VERSION "created by canmatrix"

NS_ :

BS_:

BU_: HUT T_BOX GW XBOX_D CEM Tester

BO_ 728 HUT23: 8 HUT
 SG_ ADAS_Stub_MsgTyp : 7|3@0+ (1,0) [0|7] "" GW
 SG_ ADAS_Stub_Offset : 4|13@0+ (1,0) [0|8190] "m" GW
 SG_ ADAS_Stub_CycCnt : 23|2@0+ (1,0) [0|3] "" GW
 SG_ ADAS_Stub_PathIdx : 21|6@0+ (1,0) [0|63] "" GW
 SG_ ADAS_Stub_StubPathIdx : 31|6@0+ (1,0) [0|63] "" GW
 SG_ ADAS_Stub_Retr : 25|1@0+ (1,0) [0|1] "" GW
 SG_ ADAS_Stub_Update : 24|1@0+ (1,0) [0|1] "" GW
 SG_ ADAS_Stub_RelProbb : 39|5@0+ (3.33333333333333,0) [0|100] "" GW
 SG_ ADAS_Stub_FuncRoadClass : 34|3@0+ (1,0) [0|7] "" GW
 SG_ ADAS_Stub_PartOfCalcRoute : 47|2@0+ (1,0) [0|3] "" GW
 SG_ ADAS_Stub_CmplxInsct : 45|2@0+ (1,0) [0|3] "" GW
 SG_ ADAS_Stub_FormOfWay : 43|4@0+ (1,0) [0|15] "" GW
 SG_ ADAS_Stub_TurnAngl : 55|8@0+ (1.41732283464567,0) [0|358.583] "" GW
 SG_ ADAS_Stub_LastStub : 63|1@0+ (1,0) [0|1] "" GW
 SG_ ADAS_Stub_RtOfWay : 62|2@0+ (1,0) [0|3] "" GW
 SG_ ADAS_Stub_NumOfLaneOppDir : 60|2@0+ (1,0) [0|3] "" GW
 SG_ ADAS_Stub_NumOfLaneDrvDir : 58|3@0+ (1,0) [0|7] "" GW

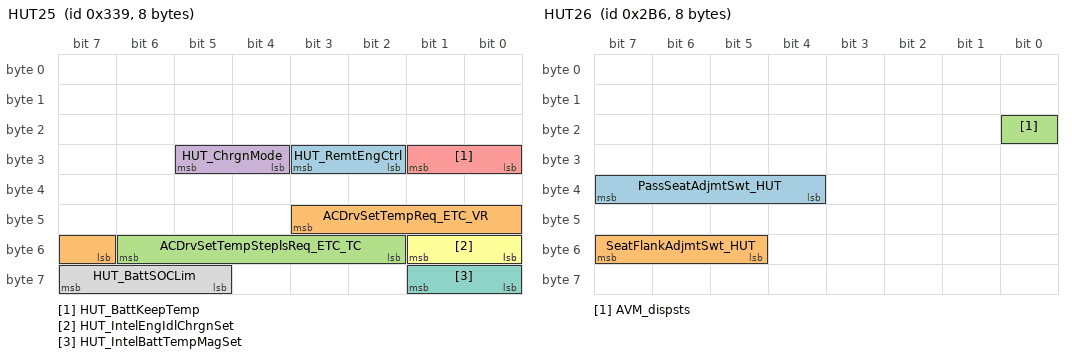
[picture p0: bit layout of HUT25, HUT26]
BO_ 825 HUT25: 8 HUT
 SG_ HUT_RemtEngCtrl : 27|2@0+ (1,0) [0|3] "" T_BOX
 SG_ ACDrvSetTempReq_ETC_VR : 43|5@0+ (1,0) [0|31] "" Vector__XXX
 SG_ ACDrvSetTempSteplsReq_ETC_TC : 54|5@0+ (1,0) [0|31] "" Vector__XXX
 SG_ HUT_ChrgnMode : 29|2@0+ (1,0) [0|3] "" GW
 SG_ HUT_BattKeepTemp : 25|2@0+ (1,0) [0|3] "" GW
 SG_ HUT_IntelEngIdlChrgnSet : 49|2@0+ (1,0) [0|3] "" GW
 SG_ HUT_IntelBattTempMagSet : 57|2@0+ (1,0) [0|3] "" GW
 SG_ HUT_BattSOCLim : 63|3@0+ (1,0) [0|7] "" GW

BO_ 694 HUT26: 8 HUT
 SG_ PassSeatAdjmtSwt_HUT : 39|4@0+ (1,0) [0|15] "" CEM
 SG_ SeatFlankAdjmtSwt_HUT : 55|3@0+ (1,0) [0|7] "" CEM
 SG_ AVM_dispsts : 16|1@0+ (1,0) [0|1] "" Vector__XXX

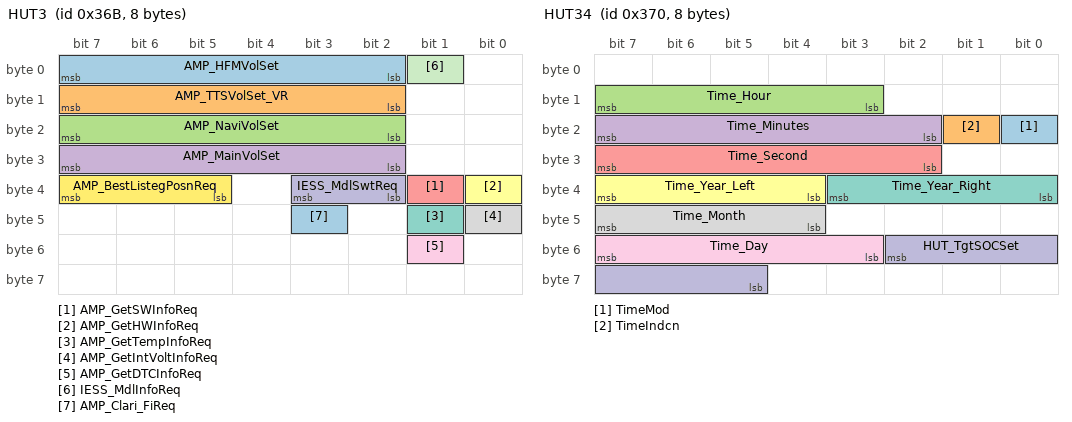
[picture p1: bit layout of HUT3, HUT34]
BO_ 875 HUT3: 8 HUT
 SG_ AMP_HFMVolSet : 7|6@0+ (1,0) [0|39] "" GW
 SG_ AMP_TTSVolSet_VR : 15|6@0+ (1,0) [0|39] "" GW
 SG_ AMP_NaviVolSet : 23|6@0+ (1,0) [0|39] "" GW
 SG_ AMP_MainVolSet : 31|6@0+ (1,0) [0|39] "" GW
 SG_ AMP_GetSWInfoReq : 33|1@0+ (1,0) [0|1] "" GW
 SG_ AMP_GetHWInfoReq : 32|1@0+ (1,0) [0|1] "" GW
 SG_ AMP_GetTempInfoReq : 41|1@0+ (1,0) [0|1] "" GW
 SG_ AMP_GetIntVoltInfoReq : 40|1@0+ (1,0) [0|1] "" GW
 SG_ AMP_GetDTCInfoReq : 49|1@0+ (1,0) [0|1] "" GW
 SG_ IESS_MdlSwtReq : 35|2@0+ (1,0) [0|3] "" GW
 SG_ IESS_MdlInfoReq : 1|1@0+ (1,0) [0|1] "" GW
 SG_ AMP_BestListegPosnReq : 39|3@0+ (1,0) [0|7] "" GW
 SG_ AMP_Clari_FiReq : 43|1@0+ (1,0) [0|1] "" GW

BO_ 489 HUT30: 8 HUT
 SG_ HUD_HeightLvlSwt : 12|5@0+ (1,0) [0|31] "" GW
 SG_ HUD_BrightnessLvlSwt : 31|4@0+ (1,0) [0|15] "" GW
 SG_ HUD_SwtReq : 25|2@0+ (1,0) [0|3] "" GW
 SG_ BackReq_AVM : 13|1@0+ (1,0) [0|1] "" CEM
 SG_ PPMIHWSwtSet : 5|2@0+ (1,0) [0|3] "" Vector__XXX
 SG_ PPMIBSRSwtSet : 3|2@0+ (1,0) [0|3] "" Vector__XXX
 SG_ PPMIHW_SwtSet : 5|2@0+ (1,0) [0|3] "" Vector__XXX
 SG_ PPMIBSR_SwtSet : 3|2@0+ (1,0) [0|3] "" Vector__XXX

BO_ 780 HUT31: 8 HUT
 SG_ HUT_PhoneNextRoad : 7|64@0+ (1,0) [0|1.84467440737096E+019] "" Vector__XXX

BO_ 623 HUT32: 8 HUT
 SG_ CheckSum_HUT32 : 7|8@0+ (1,0) [0|255] "" GW
 SG_ ScrnOpSts : 47|2@0+ (1,0) [0|3] "" GW
 SG_ XLvl : 23|11@0+ (1,0) [0|2046] "" GW
 SG_ YLvl : 26|11@0+ (1,0) [0|2046] "" GW
 SG_ DetVideoLost : 9|1@0+ (1,0) [0|1] "" GW
 SG_ PrkgCtrlModReqValid : 10|1@0+ (1,0) [0|1] "" GW
 SG_ PrkgCtrlModReq : 13|2@0+ (1,0) [0|3] "" GW
 SG_ ContnPrkgReqValid : 8|1@0+ (1,0) [0|1] "" GW
 SG_ ContnPrkgReq : 15|2@0+ (1,0) [0|3] "" GW
 SG_ PrkStraightSwtReq_HUT : 11|1@0+ (1,0) [0|1] "" GW
 SG_ PrkStraightSuspendOrFinishReq_HU : 28|2@0+ (1,0) [0|3] "" GW
 SG_ PrkStraightModSel_HUT : 63|3@0+ (1,0) [0|3] "" GW
 SG_ PrkStraightSts_HUT : 60|1@0+ (1,0) [0|1] "" GW
 SG_ PrkStraightStrtReq_HUT : 45|1@0+ (1,0) [0|1] "" GW
 SG_ PrkStraightVehStrtReq_HUT_Valid : 44|1@0+ (1,0) [0|1] "" GW
 SG_ PrkStraightContinueReq_HUT : 55|1@0+ (1,0) [0|1] "" GW
 SG_ P2P_PrkgDirSwtReq : 54|1@0+ (1,0) [0|1] "" Vector__XXX
 SG_ RainMode_Swt_Req : 51|1@0+ (1,0) [0|1] "" GW
 SG_ LCMode_Swt_Req : 50|2@0+ (1,0) [0|3] "" GW
 SG_ NavDecSwtReq : 48|1@0+ (1,0) [0|1] "_" GW
 SG_ RollingCounter_HUT32 : 59|4@0+ (1,0) [0|15] "" GW

BO_ 493 HUT33: 8 HUT
 SG_ FlaoutUnlockSet : 5|2@0+ (1,0) [0|3] "" CEM
 SG_ PrkInDirChoice : 12|2@0+ (1,0) [0|3] "" GW
 SG_ ADASDispSwt : 61|2@0+ (1,0) [0|1] "" Vector__XXX
 SG_ NaviDispSwt : 57|2@0+ (1,0) [0|1] "" Vector__XXX
 SG_ NaviDispSwt_VR : 59|2@0+ (1,0) [0|1] "" Vector__XXX
 SG_ ADASDispSwt_VR : 63|2@0+ (1,0) [0|1] "" Vector__XXX
 SG_ ApproachLampSet : 7|2@0+ (1,0) [0|3] "" CEM
 SG_ SuperLockSet : 3|2@0+ (1,0) [0|3] "" CEM
 SG_ ALCMDynModSet : 52|3@0+ (1,0) [0|7] "" CEM
 SG_ RLWinSwtReq_VR : 34|3@0+ (1,0) [0|7] "" CEM
 SG_ RRWinSwtReq_VR : 55|3@0+ (1,0) [0|7] "" CEM
 SG_ DrvWinSwtReq_VR : 15|3@0+ (1,0) [0|7] "" CEM
 SG_ PassWinSwtReq_VR : 37|3@0+ (1,0) [0|7] "" CEM
 SG_ ChairMemPosnSetSwt : 10|3@0+ (1,0) [0|7] "" CEM
 SG_ PathLrngFinshCmd : 17|1@0+ (1,0) [0|1] "" GW
 SG_ PathLrngStartCmd : 18|1@0+ (1,0) [0|1] "" GW
 SG_ SelPrkOutDirReq : 23|3@0+ (1,0) [0|7] "" GW
 SG_ StartPrkgPath2Cmd : 25|1@0+ (1,0) [0|1] "" GW
 SG_ DeletePath2Cmd : 26|1@0+ (1,0) [0|1] "" GW
 SG_ StartPrkgPath1Cmd : 27|1@0+ (1,0) [0|1] "" GW
 SG_ DeletePath1Cmd : 28|1@0+ (1,0) [0|1] "" GW
 SG_ SelPrkgFctnCmd : 31|3@0+ (1,0) [0|7] "" GW
 SG_ ParkMdlCmd : 19|1@0+ (1,0) [0|1] "" GW
 SG_ BackReq_APS : 20|1@0+ (1,0) [0|1] "" GW
 SG_ ACFGAEnaReq_TC : 47|2@0+ (1,0) [0|3] "" GW
 SG_ ACFGAChanTyp_TC : 45|3@0+ (1,0) [0|7] "" GW
 SG_ ACFGALvlReq_TC : 42|3@0+ (1,0) [0|7] "" GW
 SG_ P2P_PrkgDirectSwtCmd : 16|1@0+ (1,0) [0|1] "" GW

BO_ 880 HUT34: 8 HUT
 SG_ TimeMod : 16|1@0+ (1,0) [0|1] "" GW,CEM
 SG_ TimeIndcn : 17|1@0+ (1,0) [0|1] "" GW,CEM
 SG_ Time_Hour : 15|5@0+ (1,0) [0|31] "" GW,CEM,XBOX_D,T_BOX
 SG_ Time_Minutes : 23|6@0+ (1,0) [0|63] "" GW,CEM,XBOX_D,T_BOX
 SG_ Time_Second : 31|6@0+ (1,0) [0|63] "" GW,CEM,XBOX_D,T_BOX
 SG_ Time_Year_Left : 39|4@0+ (1,0) [0|15] "" GW,CEM,XBOX_D,T_BOX
 SG_ Time_Year_Right : 35|4@0+ (1,0) [0|15] "" GW,CEM,XBOX_D,T_BOX
 SG_ Time_Month : 47|4@0+ (1,0) [0|15] "" GW,CEM,XBOX_D,T_BOX
 SG_ Time_Day : 55|5@0+ (1,0) [0|31] "" GW,CEM,XBOX_D,T_BOX
 SG_ HUT_TgtSOCSet : 50|6@0+ (1,30) [30|80] "" GW

BO_ 485 HUT35: 8 HUT
 SG_ ACRearTempReq_ETC_VR : 23|5@0+ (1,0) [0|31] "" Vector__XXX
 SG_ ACRearTempSteplsReq_ETC_TC : 31|5@0+ (1,0) [0|31] "" Vector__XXX
 SG_ ACDrvTempDecReq_ETC_TC : 39|2@0+ (1,0) [0|3] "" Vector__XXX
 SG_ ACDrvTempIncReq_ETC_TC : 37|2@0+ (1,0) [0|3] "" Vector__XXX
 SG_ ACRearTempDecReq_ETC_TC : 35|2@0+ (1,0) [0|3] "" Vector__XXX
 SG_ ACRearTempIncReq_ETC_TC : 33|2@0+ (1,0) [0|3] "" Vector__XXX
 SG_ ACRearPowerReq_VR : 47|2@0+ (1,0) [0|3] "" GW,CEM
 SG_ ACMaxReq_VR : 26|2@0+ (1,0) [0|3] "" GW,CEM
 SG_ ACMaxReq_TC : 18|2@0+ (1,0) [0|3] "" GW,CEM
 SG_ FrntWiprCtrl_VR : 63|2@0+ (1,0) [0|3] "" CEM
 SG_ ACRearAutoModReq_VR : 43|2@0+ (1,0) [0|3] "" GW,CEM
 SG_ LockWinSet : 49|1@0+ (1,0) [0|1] "" CEM
 SG_ ACRearLockReq_TC : 45|2@0+ (1,0) [0|3] "" GW
 SG_ SrSpdCtrlSwt : 16|1@0+ (1,0) [0|1] "" CEM
 SG_ DPF_Request : 58|2@0+ (1,0) [0|3] "" GW
 SG_ ColorCategory : 3|2@0+ (1,0) [0|3] "" CEM
 SG_ SingleColorNr : 14|7@0+ (1,0) [0|64] "" CEM

BO_ 487 HUT38: 8 HUT
 SG_ ACRLTempDecReq_TC : 7|2@0+ (1,0) [0|3] "" GW,CEM
 SG_ ACRLTempIncReq_TC : 5|2@0+ (1,0) [0|3] "" GW,CEM
 SG_ ACRLTempReq_VR : 15|6@0+ (0.5,15.5) [16|32] "" GW,CEM
 SG_ ACRRTempDecReq_TC : 3|2@0+ (1,0) [0|3] "" CEM
 SG_ ACRRTempIncReq_TC : 1|2@0+ (1,0) [0|3] "" CEM
 SG_ ACRRTempReq_VR : 23|6@0+ (0.5,15.5) [16|32] "" CEM
 SG_ ACRRTempSteplsReq_TC : 17|2@0+ (1,0) [0|3] "" CEM
 SG_ ACHumidifierReq_VR : 31|2@0+ (1,0) [0|3] "" CEM
 SG_ ACHumidifierReq_TC : 29|2@0+ (1,0) [0|3] "" CEM
 SG_ ACOzoneReq_TC : 27|2@0+ (1,0) [0|3] "" CEM
 SG_ ACOzoneReq_VR : 25|2@0+ (1,0) [0|3] "" CEM
 SG_ ACUltravioletReq_TC : 39|2@0+ (1,0) [0|3] "" CEM
 SG_ ACUltravioletReq_VR : 37|2@0+ (1,0) [0|3] "" CEM
 SG_ ACFrntWinHeatCmd_TC : 35|2@0+ (1,0) [0|3] "" CEM
 SG_ ACFrntWinHeatCmd_VR : 33|2@0+ (1,0) [0|3] "" CEM
 SG_ DrvDoorALCMFlashFreq : 47|3@0+ (1,0) [0|7] "" CEM
 SG_ PassDoorALCMFlashFreq : 44|3@0+ (1,0) [0|7] "" CEM
 SG_ LRDoorALCMFlashFreq : 41|3@0+ (1,0) [0|7] "" CEM
 SG_ RRDoorALCMFlashFreq : 54|3@0+ (1,0) [0|7] "" CEM
 SG_ FootALCMFlashFreq : 51|3@0+ (1,0) [0|7] "" CEM
 SG_ LeftPanelALCMFlashFreq : 63|3@0+ (1,0) [0|7] "" CEM
 SG_ RightPanelALCMFlashFreq : 60|3@0+ (1,0) [0|7] "" CEM
 SG_ ACRearLockReq_VR : 57|2@0+ (1,0) [0|3] "" GW

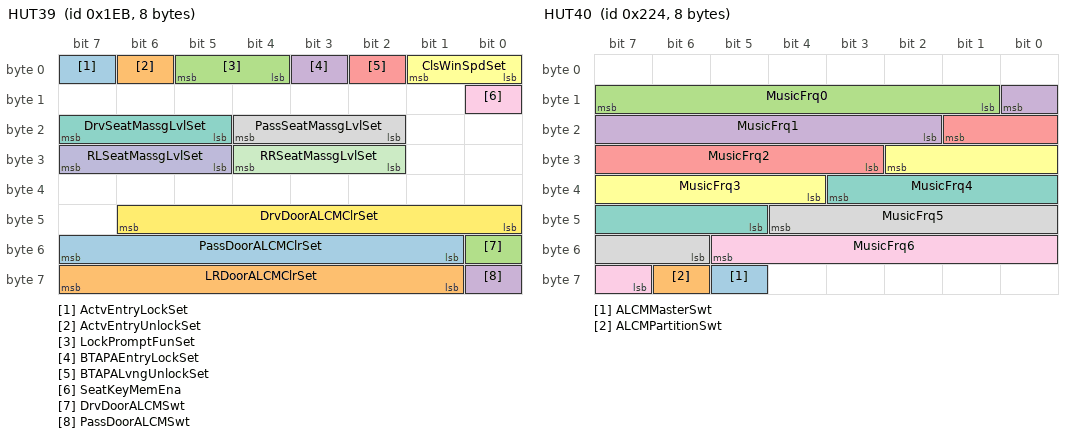
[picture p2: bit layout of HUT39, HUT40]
BO_ 491 HUT39: 8 HUT
 SG_ ActvEntryLockSet : 7|1@0+ (1,0) [0|1] "" CEM
 SG_ ActvEntryUnlockSet : 6|1@0+ (1,0) [0|1] "" CEM
 SG_ LockPromptFunSet : 5|2@0+ (1,0) [0|3] "" CEM
 SG_ BTAPAEntryLockSet : 3|1@0+ (1,0) [0|1] "" CEM
 SG_ BTAPALvngUnlockSet : 2|1@0+ (1,0) [0|1] "" CEM
 SG_ ClsWinSpdSet : 1|2@0+ (1,0) [0|3] "" CEM
 SG_ DrvSeatMassgLvlSet : 23|3@0+ (1,0) [0|7] "" GW,CEM
 SG_ PassSeatMassgLvlSet : 20|3@0+ (1,0) [0|7] "" GW,CEM
 SG_ SeatKeyMemEna : 8|1@0+ (1,0) [0|1] "" CEM
 SG_ RLSeatMassgLvlSet : 31|3@0+ (1,0) [0|7] "" GW,CEM
 SG_ RRSeatMassgLvlSet : 28|3@0+ (1,0) [0|7] "" GW,CEM
 SG_ DrvDoorALCMClrSet : 46|7@0+ (1,0) [0|127] "" CEM
 SG_ PassDoorALCMClrSet : 55|7@0+ (1,0) [0|127] "" CEM
 SG_ LRDoorALCMClrSet : 63|7@0+ (1,0) [0|127] "" CEM
 SG_ DrvDoorALCMSwt : 48|1@0+ (1,0) [0|1] "" CEM
 SG_ PassDoorALCMSwt : 56|1@0+ (1,0) [0|1] "" CEM

BO_ 877 HUT4: 8 HUT
 SG_ DrvSeatVentnLvlSet : 9|2@0+ (1,0) [0|3] "" CEM
 SG_ PassSeatVentnLvlSet : 23|2@0+ (1,0) [0|3] "" CEM
 SG_ ACAutoModReq_VR : 25|2@0+ (1,0) [0|3] "" GW
 SG_ ACCmprReq_VR : 39|2@0+ (1,0) [0|3] "" GW
 SG_ ACPowerReq_VR : 37|2@0+ (1,0) [0|3] "" GW
 SG_ ACBlwrSpdReq_VR : 35|4@0+ (1,0) [0|15] "" GW
 SG_ ACDrvTempReq_VR : 47|6@0+ (0.5,15.5) [16|32] "Ã‚Â°C" GW
 SG_ ACFrntDefrostReq_VR : 41|2@0+ (1,0) [0|3] "" GW
 SG_ ACDrvAirDistribModReq_VR : 55|3@0+ (1,0) [0|7] "" GW
 SG_ ACAirInletReq_VR : 52|2@0+ (1,0) [0|3] "" GW
 SG_ ACModReq_HUT : 63|2@0+ (1,0) [0|3] "" Vector__XXX
 SG_ ElecSideSteppingSysSet : 21|1@0+ (1,0) [0|1] "" CEM
 SG_ RoofModSet : 18|1@0+ (1,0) [0|1] "" CEM
 SG_ AllTerrainDislSet : 29|1@0+ (1,0) [0|1] "" CEM
 SG_ RemUpgrdSts : 56|1@0+ (1,0) [0|1] "" CEM,T_BOX
 SG_ ACRearAutoModReq_TC : 13|1@0+ (1,0) [0|1] "" GW,CEM
 SG_ DrvSeatSupportLvlSet : 7|3@0+ (1,0) [0|7] "" CEM
 SG_ PassSeatSupportLvlSet : 2|3@0+ (1,0) [0|7] "" CEM
 SG_ ACRearOffReq_TC : 10|1@0+ (1,0) [0|3] "" GW,CEM
 SG_ ACRearAirDistribModReq_TC : 50|3@0+ (1,0) [0|7] "" GW,CEM
 SG_ RLSeatVentnLvlSet : 20|2@0+ (1,0) [0|3] "" CEM
 SG_ RRSeatVentnLvlSet : 17|2@0+ (1,0) [0|3] "" CEM

BO_ 548 HUT40: 8 HUT
 SG_ ALCMMasterSwt : 61|1@0+ (1,0) [0|1] "" CEM
 SG_ ALCMPartitionSwt : 62|1@0+ (1,0) [0|1] "" CEM
 SG_ MusicFrq0 : 15|7@0+ (1,0) [0|127] "" CEM
 SG_ MusicFrq1 : 8|7@0+ (1,0) [0|127] "" CEM
 SG_ MusicFrq2 : 17|7@0+ (1,0) [0|127] "" CEM
 SG_ MusicFrq3 : 26|7@0+ (1,0) [0|127] "" CEM
 SG_ MusicFrq4 : 35|7@0+ (1,0) [0|127] "" CEM
 SG_ MusicFrq5 : 44|7@0+ (1,0) [0|127] "" CEM
 SG_ MusicFrq6 : 53|7@0+ (1,0) [0|127] "" CEM

BO_ 507 HUT41: 8 HUT
 SG_ RRDoorALCMClrSet : 7|7@0+ (1,0) [0|127] "" CEM
 SG_ LeftPanelALCMClrSet : 15|7@0+ (1,0) [0|127] "" CEM
 SG_ RightPanelALCMClrSet : 23|7@0+ (1,0) [0|127] "" CEM
 SG_ FootALCMClrSet : 31|7@0+ (1,0) [0|127] "" CEM
 SG_ DrvDoorALCMLightLvlSet : 39|4@0+ (1,0) [0|15] "" CEM
 SG_ PassDoorALCMLightLvlSet : 35|4@0+ (1,0) [0|15] "" CEM
 SG_ LRDoorALCMLightLvlSet : 47|4@0+ (1,0) [0|15] "" CEM
 SG_ RRDoorALCMLightLvlSet : 43|4@0+ (1,0) [0|15] "" CEM
 SG_ LeftPanelALCMLightLvlSet : 55|4@0+ (1,0) [0|15] "" CEM
 SG_ RightPanelALCMLightLvlSet : 51|4@0+ (1,0) [0|15] "" CEM
 SG_ FootALCMLightLvlSet : 63|4@0+ (1,0) [0|15] "" CEM
 SG_ ALCMFloSwt : 0|1@0+ (1,0) [0|1] "" CEM
 SG_ ALCMBreSwt : 8|1@0+ (1,0) [0|1] "" CEM
 SG_ RightPanelALCMSwt : 24|1@0+ (1,0) [0|1] "" CEM
 SG_ LRDoorALCMSwt : 59|1@0+ (1,0) [0|1] "" CEM
 SG_ RRDoorALCMSwt : 58|1@0+ (1,0) [0|1] "" CEM
 SG_ FootALCMSwt : 57|1@0+ (1,0) [0|1] "" CEM
 SG_ RoofALCMSwt : 56|1@0+ (1,0) [0|1] "" CEM
 SG_ LeftPanelALCMSwt : 16|1@0+ (1,0) [0|1] "" CEM

BO_ 505 HUT42: 8 HUT
 SG_ ACRLTempSteplsReq_TC : 37|6@0+ (0.5,15.5) [16|32] "" GW

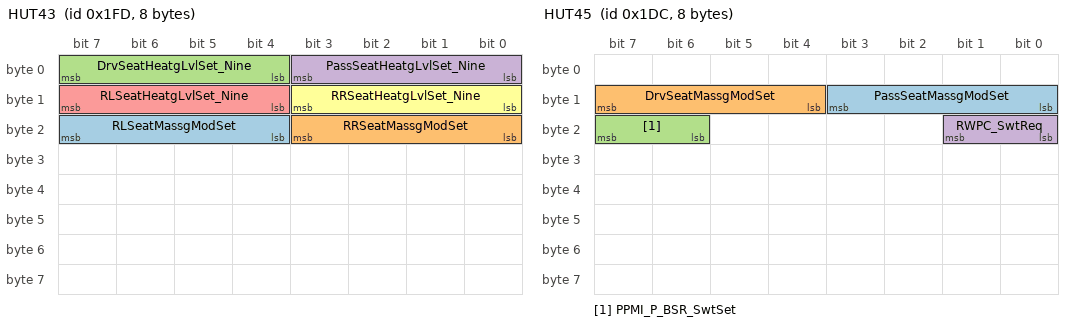
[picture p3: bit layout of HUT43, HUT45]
BO_ 509 HUT43: 8 HUT
 SG_ RLSeatMassgModSet : 23|4@0+ (1,0) [0|15] "" GW,CEM
 SG_ RRSeatMassgModSet : 19|4@0+ (1,0) [0|15] "" GW,CEM
 SG_ DrvSeatHeatgLvlSet_Nine : 7|4@0+ (1,0) [0|15] "" CEM
 SG_ PassSeatHeatgLvlSet_Nine : 3|4@0+ (1,0) [0|15] "" CEM
 SG_ RLSeatHeatgLvlSet_Nine : 15|4@0+ (1,0) [0|15] "" CEM
 SG_ RRSeatHeatgLvlSet_Nine : 11|4@0+ (1,0) [0|15] "" CEM

BO_ 476 HUT45: 8 HUT
 SG_ PassSeatMassgModSet : 11|4@0+ (1,0) [0|15] "" GW
 SG_ DrvSeatMassgModSet : 15|4@0+ (1,0) [0|15] "" GW
 SG_ PPMI_P_BSR_SwtSet : 23|2@0+ (1,0) [0|3] "" Vector__XXX
 SG_ RWPC_SwtReq : 17|2@0+ (1,0) [0|3] "" Vector__XXX

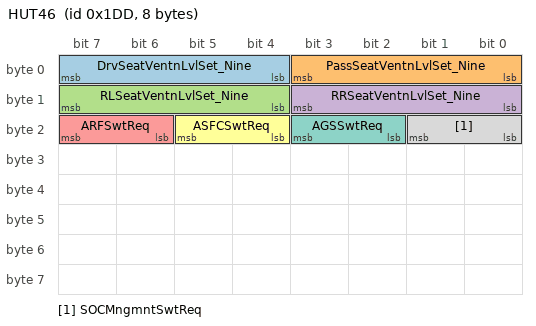
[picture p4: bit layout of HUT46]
BO_ 477 HUT46: 8 HUT
 SG_ DrvSeatVentnLvlSet_Nine : 7|4@0+ (1,0) [0|15] "" CEM
 SG_ PassSeatVentnLvlSet_Nine : 3|4@0+ (1,0) [0|15] "" CEM
 SG_ RLSeatVentnLvlSet_Nine : 15|4@0+ (1,0) [0|15] "" CEM
 SG_ RRSeatVentnLvlSet_Nine : 11|4@0+ (1,0) [0|15] "" CEM
 SG_ ARFSwtReq : 23|2@0+ (1,0) [0|2] "" GW
 SG_ ASFCSwtReq : 21|2@0+ (1,0) [0|2] "" GW
 SG_ AGSSwtReq : 19|2@0+ (1,0) [0|2] "" GW
 SG_ SOCMngmntSwtReq : 17|2@0+ (1,0) [0|2] "" GW

BO_ 74 HUT6: 8 HUT
 SG_ AUTODefrost_TC : 6|2@0+ (1,0) [0|3] "" GW,CEM
 SG_ AUTODefrost_VR : 4|2@0+ (1,0) [0|3] "" GW,CEM
 SG_ LaneCalActvtCmd : 42|1@0+ (1,0) [0|1] "" GW
 SG_ MODChgReq : 62|1@0+ (1,0) [0|1] "" GW
 SG_ Radar_DispCmd : 40|1@0+ (1,0) [0|1] "" GW
 SG_ Guid_Ovl_Display_Cmd : 7|1@0+ (1,0) [0|1] "" GW
 SG_ Sgl_View_Sel : 36|4@0+ (1,0) [0|15] "" GW
 SG_ SwToFieldCalRstCmd : 58|1@0+ (1,0) [0|1] "" GW
 SG_ AutoViewChgCmd : 55|1@0+ (1,0) [0|1] "" GW
 SG_ MdlColrChgCmd : 53|1@0+ (1,0) [0|1] "" GW
 SG_ CarMdlTrsprcySwtCmd : 49|1@0+ (1,0) [0|1] "" GW
 SG_ CarMdlDispCmd : 63|1@0+ (1,0) [0|1] "" GW
 SG_ AutoAVMSwSet_Cmd : 57|1@0+ (1,0) [0|1] "" GW
 SG_ FPAS_AutoModSwt : 60|1@0+ (1,0) [0|1] "" GW
 SG_ MEBSwtSet : 61|1@0+ (1,0) [0|1] "" GW
 SG_ WshSoftSwt : 56|1@0+ (1,0) [0|1] "" GW
 SG_ View_SoftswitchCmd : 59|1@0+ (1,0) [0|1] "" GW

BO_ 465 HUT49: 8 HUT
 SG_ AntiDisIdnResp : 7|32@0+ (1,0) [0|4294967295] "" GW

BO_ 288 Ibooster_FD2: 64 GW
 SG_ IB_Warn : 46|1@0+ (1,0) [0|1] "" HUT

BO_ 573 IFC_FD2: 64 IFC
 SG_ Checksum_IFC3 : 71|8@0+ (1,0) [0|255] "" HUT
 SG_ LDWResp : 79|1@0+ (1,0) [0|1] "" HUT
 SG_ LKAResp : 78|1@0+ (1,0) [0|1] "" HUT
 SG_ LCKResp : 77|1@0+ (1,0) [0|1] "" HUT
 SG_ ELKResp : 76|1@0+ (1,0) [0|1] "" HUT
 SG_ LDW_LKA_Snvty : 74|2@0+ (1,0) [0|3] "" HUT
 SG_ IFCHUTInterface : 72|1@0+ (1,0) [0|1] "" HUT
 SG_ LSSWarnFormResp : 85|2@0+ (1,0) [0|3] "" HUT
 SG_ LSSResp : 83|1@0+ (1,0) [0|1] "" HUT
 SG_ AESSts : 81|2@0+ (1,0) [0|3] "" HUT
 SG_ ESSSts : 95|2@0+ (1,0) [0|3] "" HUT
 SG_ AESErrSts : 93|1@0+ (1,0) [0|1] "" HUT
 SG_ ESSErrSts : 92|1@0+ (1,0) [0|1] "" HUT
 SG_ RollingCounter_IFC3 : 123|4@0+ (1,0) [0|15] "" HUT
 SG_ Checksum_IFC4 : 135|8@0+ (1,0) [0|255] "" HUT
 SG_ IFC_Handsoffwarn : 157|3@0+ (1,0) [0|7] "" HUT
 SG_ IFCCalibrationSts : 154|2@0+ (1,0) [0|3] "" HUT
 SG_ CameraBlockageSts : 152|1@0+ (1,0) [0|1] "" HUT
 SG_ LDW_LKAWarn : 143|2@0+ (1,0) [0|3] "" HUT
 SG_ LSSIntervention : 141|3@0+ (1,0) [0|7] "" HUT,T_BOX
 SG_ LSSFuncSts : 138|3@0+ (1,0) [0|7] "" HUT
 SG_ ELKMainState : 151|3@0+ (1,0) [0|7] "" HUT
 SG_ LaneAvailability : 148|2@0+ (1,0) [0|3] "" HUT
 SG_ TJA_FollowSts : 146|2@0+ (1,0) [0|3] "" HUT
 SG_ LSSErrSts : 144|3@0+ (1,0) [0|7] "" HUT
 SG_ AESintervention : 191|2@0+ (1,0) [0|3] "" HUT
 SG_ ESSintervention : 189|2@0+ (1,0) [0|3] "" HUT
 SG_ ELKActSts : 167|2@0+ (1,0) [0|3] "" HUT
 SG_ IntelligentEvaActSts : 165|2@0+ (1,0) [0|3] "" HUT
 SG_ LCKStsIndcr : 163|2@0+ (1,0) [0|3] "" HUT
 SG_ RollingCounter_IFC4 : 187|4@0+ (1,0) [0|15] "" HUT
 SG_ Checksum_IFC5 : 199|8@0+ (1,0) [0|255] "" HUT
 SG_ IFC_LaneCurve : 207|12@0+ (0.000015,-0.030705) [-0.030705|0.030705] "" HUT
 SG_ IFC_LeLaneTyp : 211|3@0+ (1,0) [0|7] "" HUT
 SG_ IFC_RiLaneTyp : 208|3@0+ (1,0) [0|7] "" HUT
 SG_ IFC_NextLeLaneTyp : 221|3@0+ (1,0) [0|7] "" HUT
 SG_ IFC_NextRiLaneTyp : 218|3@0+ (1,0) [0|7] "" HUT
 SG_ IFC_LeLane_dy : 231|12@0+ (0.00390625,-8) [-8|7.9921875] "" HUT
 SG_ IFC_RiLane_dy : 235|12@0+ (0.00390625,-8) [-8|7.9921875] "" HUT
 SG_ RollingCounter_IFC5 : 251|4@0+ (1,0) [0|15] "" HUT
 SG_ Checksum_IFC6 : 263|8@0+ (1,0) [0|255] "" HUT
 SG_ IFC_NextLeLane_dy : 271|12@0+ (0.00390625,-8) [-8|7.9921875] "" HUT
 SG_ IFC_NextRiLane_dy : 275|12@0+ (0.00390625,-8) [-8|7.9921875] "" HUT
 SG_ RollingCounter_IFC6 : 315|4@0+ (1,0) [0|15] "" HUT
 SG_ AESResp : 75|1@0+ (1,0) [0|1] "" HUT
 SG_ ESS_Pedresp : 87|1@0+ (1,0) [0|1] "" HUT
 SG_ ESS_Vehresp : 86|1@0+ (1,0) [0|1] "" HUT
 SG_ IntelligentEvaResp : 82|1@0+ (1,0) [0|1] "" HUT
 SG_ FreshnessValue_IFC_FD2 : 455|16@0+ (1,0) [0|65535] "" HUT
 SG_ MAC_Check_IFC_FD2 : 471|48@0+ (1,0) [0|281474976710655] "" HUT

BO_ 719 IFC_FD3: 64 GW
 SG_ TSRResp : 79|1@0+ (1,0) [0|1] "" HUT
 SG_ TSRSpdLimUnit : 78|2@0+ (1,0) [0|3] "" HUT
 SG_ TSRSpdLim : 87|6@0+ (1,0) [0|63] "" HUT
 SG_ TSRSpdLimCfdc : 76|2@0+ (1,0) [0|3] "" HUT
 SG_ TSRSts : 74|3@0+ (1,0) [0|7] "" HUT
 SG_ TSRSpdLimSts : 81|2@0+ (1,0) [0|3] "" HUT
 SG_ TSRTrfcSignValCfdc : 95|2@0+ (1,0) [0|3] "" HUT
 SG_ TSRTrfcSignVal : 93|8@0+ (1,0) [0|255] "" HUT
 SG_ TSRSpdLimWarn : 101|1@0+ (1,0) [0|1] "" HUT
 SG_ TSRWarnResp : 108|1@0+ (1,0) [0|1] "" HUT
 SG_ TSR_Snvty : 100|5@0+ (1,-15) [-15|15] "kmh" HUT
 SG_ IDC_L2_TurnLightReq : 110|2@0+ (1,0) [0|3] "" HUT
 SG_ HWA_ALC_Trig : 143|2@0+ (1,0) [0|3] "" HUT
 SG_ HWA_WarnInfoDisp : 141|4@0+ (1,0) [0|15] "" HUT
 SG_ HWA_TakOver_Trig : 151|3@0+ (1,0) [0|7] "" HUT
 SG_ HWA_TakOver_Req : 137|2@0+ (1,0) [0|3] "" HUT
 SG_ MRC_InterSysInfoDisp : 148|4@0+ (1,0) [0|15] "" HUT
 SG_ MRC_TakOver_Req : 159|2@0+ (1,0) [0|3] "" HUT
 SG_ NOH_WarnInfoDisp : 157|4@0+ (1,0) [0|15] "" HUT
 SG_ IFC_Line01_Source : 144|1@0+ (1,0) [0|1] "" HUT
 SG_ IFC_Line02_Source : 174|1@0+ (1,0) [0|1] "" HUT
 SG_ TSR_Traffic_Light_Posn : 153|2@0+ (1,0) [0|3] "" HUT
 SG_ Stop_Mark_Detn : 173|2@0+ (1,0) [0|3] "" HUT
 SG_ Stop_Mark_Dx : 167|9@0+ (0.5,0) [0|150] "m" HUT
 SG_ Zebra_Mark_Detn : 171|2@0+ (1,0) [0|3] "" HUT
 SG_ Grid_Mark_Detn : 169|2@0+ (1,0) [0|3] "" HUT
 SG_ HWA_InhibitWarn : 183|3@0+ (1,0) [0|7] "" HUT
 SG_ LaneChngCfmSwt_Resp : 189|1@0+ (1,0) [0|1] "" HUT
 SG_ ALC_SwtReq_Resp : 190|1@0+ (1,0) [0|1] "" HUT
 SG_ AutoSpdSetSwt_Resp : 191|1@0+ (1,0) [0|1] "" HUT
 SG_ VoiceBrdcSwt_Resp : 176|1@0+ (1,0) [0|1] "" HUT
 SG_ UsrManSts_Resp : 180|4@0+ (1,0) [0|15] "" HUT
 SG_ Grid_Mark_Dx : 207|9@0+ (0.5,0) [0|150] "m" HUT
 SG_ Zebra_Mark_Dx : 223|9@0+ (0.5,0) [0|150] "m" HUT
 SG_ TSR_Traffic_Light : 214|2@0+ (1,0) [0|3] "" HUT
 SG_ TSR_Traffic_Light_Through : 212|2@0+ (1,0) [0|3] "" HUT
 SG_ TSR_Traffic_Light_Le : 210|2@0+ (1,0) [0|3] "" HUT
 SG_ TSR_Traffic_Light_Ri : 230|2@0+ (1,0) [0|3] "" HUT
 SG_ RainMode_Swt_Resp : 228|1@0+ (1,0) [0|1] "" HUT
 SG_ LCMode_Swt_Resp : 227|2@0+ (1,0) [0|1] "" HUT
 SG_ NavDecSwtResp : 225|1@0+ (1,0) [0|1] "" HUT

BO_ 415 IFC_FD5: 64 GW
 SG_ IFC_Line01_Dy : 15|13@0+ (0.01,-30) [-30|30] "m" HUT
 SG_ IFC_Line01_Curv : 18|15@0+ (0.000016,-0.25) [-0.25|0.25] "1m" HUT
 SG_ IFC_Line01_CurvChange : 35|20@0+ (5E-008,-0.024) [-0.024|0.024] "1(m*m)" HUT
 SG_ IFC_Line01_Type : 63|4@0+ (1,0) [0|15] "" HUT
 SG_ IFC_Line02_Dy : 79|13@0+ (0.01,-30) [-30|30] "m" HUT
 SG_ IFC_Line02_Curv : 82|15@0+ (0.000016,-0.25) [-0.25|0.25] "1m" HUT
 SG_ IFC_Line02_CurvChange : 99|20@0+ (5E-008,-0.024) [-0.024|0.024] "1(m*m)" HUT
 SG_ IFC_Line02_Type : 127|4@0+ (1,0) [0|15] "" HUT
 SG_ IFC_Line03_Dy : 143|13@0+ (0.01,-30) [-30|30] "m" HUT
 SG_ IFC_Line03_Curv : 146|15@0+ (0.000016,-0.25) [-0.25|0.25] "1m" HUT
 SG_ IFC_Line03_CurvChange : 163|20@0+ (5E-008,-0.024) [-0.024|0.024] "1(m*m)" HUT
 SG_ IFC_Line03_Type : 191|4@0+ (1,0) [0|15] "" HUT
 SG_ IFC_Line04_Dy : 207|13@0+ (0.01,-30) [-30|30] "m" HUT
 SG_ IFC_Line04_Curv : 210|15@0+ (0.000016,-0.25) [-0.25|0.25] "1m" HUT
 SG_ IFC_Line04_CurvChange : 227|20@0+ (5E-008,-0.024) [-0.024|0.024] "1(m*m)" HUT
 SG_ IFC_Line04_Type : 255|4@0+ (1,0) [0|15] "" HUT
 SG_ IFC_Roadedge01_Dy : 271|13@0+ (0.01,-30) [-30|30] "m" HUT
 SG_ IFC_Roadedge01_Curv : 274|15@0+ (0.000016,-0.25) [-0.25|0.25] "1m" HUT
 SG_ IFC_Roadedge01_CurvChange : 291|20@0+ (5E-008,-0.024) [-0.024|0.024] "1(m*m)" HUT
 SG_ IFC_Roadedge01_Type : 319|4@0+ (1,0) [0|15] "" HUT
 SG_ IFC_Roadedge02_Dy : 335|13@0+ (0.01,-30) [-30|30] "m" HUT
 SG_ IFC_Roadedge02_Curv : 338|15@0+ (0.000016,-0.25) [-0.25|0.25] "1m" HUT
 SG_ IFC_Roadedge02_CurvChange : 355|20@0+ (5E-008,-0.024) [-0.024|0.024] "1(m*m)" HUT
 SG_ IFC_Roadedge02_Type : 383|4@0+ (1,0) [0|15] "" HUT

BO_ 546 IFC_FD6: 64 GW
 SG_ IFC_Line01_DxStart : 15|15@0+ (0.01,0) [0|200] "m" HUT
 SG_ IFC_Line01_DxEnd : 16|15@0+ (0.01,0) [0|200] "m" HUT
 SG_ IFC_Line01_HeadingAngle : 33|9@0+ (0.01,-2) [-2|2] "rad" HUT
 SG_ IFC_Line02_HeadingAngle : 40|9@0+ (0.01,-2) [-2|2] "rad" HUT
 SG_ IFC_Line02_DxStart : 79|15@0+ (0.01,0) [0|200] "m" HUT
 SG_ IFC_Line02_DxEnd : 95|15@0+ (0.01,0) [0|200] "m" HUT
 SG_ IFC_Line03_DxStart : 111|15@0+ (0.01,0) [0|200] "m" HUT
 SG_ IFC_Line03_DxEnd : 143|15@0+ (0.01,0) [0|200] "m" HUT
 SG_ IFC_Line03_HeadingAngle : 144|9@0+ (0.01,-2) [-2|2] "rad" HUT
 SG_ IFC_Line04_DxStart : 167|15@0+ (0.01,0) [0|200] "m" HUT
 SG_ IFC_Line04_HeadingAngle : 168|9@0+ (0.01,-2) [-2|2] "rad" HUT
 SG_ IFC_Line04_DxEnd : 207|15@0+ (0.01,0) [0|200] "m" HUT
 SG_ IFC_Roadedge01_DxStart : 223|15@0+ (0.01,0) [0|200] "m" HUT
 SG_ IFC_Roadedge01_DxEnd : 239|15@0+ (0.01,0) [0|200] "m" HUT
 SG_ IFC_Roadedge01_HeadingAngle : 271|9@0+ (0.01,-2) [-2|2] "rad" HUT
 SG_ IFC_Roadedge02_DxStart : 278|15@0+ (0.01,0) [0|200] "m" HUT
 SG_ IFC_Roadedge02_DxEnd : 295|15@0+ (0.01,0) [0|200] "m" HUT
 SG_ IFC_Roadedge02_HeadingAngle : 296|9@0+ (0.01,-2) [-2|2] "rad" HUT

BO_ 265 IFC1: 8 GW
 SG_ IFCTrqOvlCmdProtnValue : 15|14@0+ (1,0) [0|16383] "" HUT
 SG_ IFCTrqOvlCmdReqValue : 39|11@0+ (0.01,-10.23) [-10.23|10.24] "Nm" HUT

CM_ SG_ 728 ADAS_Stub_MsgTyp "Identify type of messageADAS-CANFD To:IFC,IDC_L2";
CM_ SG_ 728 ADAS_Stub_Offset "Distance from stub start to Path startADAS-CANFD To:IFC,IDC_L2";
CM_ SG_ 728 ADAS_Stub_CycCnt "Message rollingcounterADAS-CANFD To:IFC,IDC_L2";
CM_ SG_ 728 ADAS_Stub_PathIdx "ADAS_Stub_PathIdxADAS-CANFD To:IFC,IDC_L2";
CM_ SG_ 728 ADAS_Stub_StubPathIdx "stub path  indexesADAS-CANFD To:IFC,IDC_L2";
CM_ SG_ 728 ADAS_Stub_Retr "ADAS_Stub_RetrADAS-CANFD To:IFC,IDC_L2";
CM_ SG_ 728 ADAS_Stub_Update "Stub Segment updateADAS-CANFD To:IFC,IDC_L2";
CM_ SG_ 728 ADAS_Stub_RelProbb "Relative probability of new path at the intersectionADAS-CANFD To:IFC,IDC_L2";
CM_ SG_ 728 ADAS_Stub_FuncRoadClass "stub FRC informationÃ¯Â¼Âˆfor lane typeÃ¯Â¼Â‰ADAS-CANFD To:IFC,IDC_L2";
CM_ SG_ 728 ADAS_Stub_PartOfCalcRoute "Whether stub plan path informationADAS-CANFD To:IFC,IDC_L2";
CM_ SG_ 728 ADAS_Stub_CmplxInsct "complex intersection information from stubADAS-CANFD To:IFC,IDC_L2";
CM_ SG_ 728 ADAS_Stub_FormOfWay "Road facilities information from stubADAS-CANFD To:IFC,IDC_L2";
CM_ SG_ 728 ADAS_Stub_TurnAngl "Steering angle information from stubADAS-CANFD To:IFC,IDC_L2";
CM_ SG_ 728 ADAS_Stub_LastStub "ADAS_Stub_LastStubADAS-CANFD To:IFC,IDC_L2";
CM_ SG_ 728 ADAS_Stub_RtOfWay "Right of way information from stubADAS-CANFD To:IFC,IDC_L2";
CM_ SG_ 728 ADAS_Stub_NumOfLaneOppDir "Number of tfaffic lane in opposite  direction from stubADAS-CANFD To:IFC,IDC_L2";
CM_ SG_ 728 ADAS_Stub_NumOfLaneDrvDir "Number of tfaffic lane in forward  direction from stubADAS-CANFD To:IFC,IDC_L2";
CM_ SG_ 825 HUT_RemtEngCtrl "Remote engine control";
CM_ SG_ 825 ACDrvSetTempReq_ETC_VR "ETC AC(Air Conditioning) Driver Set Temperature Request(Voice Request)";
CM_ SG_ 825 ACDrvSetTempSteplsReq_ETC_TC "ETC AC(Air Conditioning) Driver Set Temperature Stepless Request-Touch Control";
CM_ SG_ 825 HUT_ChrgnMode "Charging mode including Immediate Charging and Delay Charging set on HUTHC_CAN:To PDCU";
CM_ SG_ 825 HUT_BattKeepTemp "Setting Battery Keep Temperature by user on  HUTHC_CAN:To PDCU";
CM_ SG_ 825 HUT_IntelEngIdlChrgnSet "Intelligent  Engine Idle Charging for BMS Setting on HUTHC_CAN:To PDCU";
CM_ SG_ 825 HUT_IntelBattTempMagSet "Intelligent Battery Temperature Management Setting on HUTHC_CAN:To PDCU";
CM_ SG_ 825 HUT_BattSOCLim "Setting external charging level for SOCHC_CAN:To PDCU";
CM_ SG_ 694 PassSeatAdjmtSwt_HUT "Passenger seat adjustment switch by HUT";
CM_ SG_ 694 SeatFlankAdjmtSwt_HUT "Seat flank adjustment switch by HUT";
CM_ SG_ 694 AVM_dispsts "AVM Display Status";
CM_ SG_ 875 AMP_HFMVolSet "HFM(Hand Free Mode), RT(Ring Tone) and Tbox-IBcall(InformationBreakdown call) volume set.BD2-CAN To:AMP";
CM_ SG_ 875 AMP_TTSVolSet_VR "TTS(text to sound) volume set.(Voice Request)BD2-CAN To:AMP";
CM_ SG_ 875 AMP_NaviVolSet "Navigation volume set.BD2-CAN To:AMP";
CM_ SG_ 875 AMP_MainVolSet "Main volume set.BD2-CAN To:AMP";
CM_ SG_ 875 AMP_GetSWInfoReq "Get Amplifier Software Information RequestBD2-CAN To:AMP";
CM_ SG_ 875 AMP_GetHWInfoReq "Get Amplifier Hardware Information RequestBD2-CAN To:AMP";
CM_ SG_ 875 AMP_GetTempInfoReq "Get Amplifier temperature Value requestBD2-CAN To:AMP";
CM_ SG_ 875 AMP_GetIntVoltInfoReq "Get Amplifier internal voltage information request.BD2-CAN To:AMP";
CM_ SG_ 875 AMP_GetDTCInfoReq "Get Amplifier DTC(Diagnostic Trouble Code) information request.BD2-CAN To:AMP";
CM_ SG_ 875 IESS_MdlSwtReq "IESS(Internal Electronic Sound Synthesis)  Model requestBD2-CAN To:AMP";
CM_ SG_ 875 IESS_MdlInfoReq "IESS(Internal Electronic Sound Synthesis) Model information requestBD2-CAN To:AMP";
CM_ SG_ 875 AMP_BestListegPosnReq "Best listenting Position request.BD2-CAN To:AMP";
CM_ SG_ 875 AMP_Clari_FiReq "Clari_Fi request.Ã¯Â¼ÂˆAudio source repair Technology Request)BD2-CAN To:AMP";
CM_ SG_ 489 HUD_HeightLvlSwt "HUD Height Level switchBD2-CAN To:HUD";
CM_ SG_ 489 HUD_BrightnessLvlSwt "HUD Brightness Level switchBD2-CAN To:HUD";
CM_ SG_ 489 HUD_SwtReq "HUD switch requestBD2-CAN To:HUD";
CM_ SG_ 489 BackReq_AVM "Exit AVM and back to HUT interface request";
CM_ SG_ 489 PPMIHWSwtSet "PPMI Haptic Warning switch set";
CM_ SG_ 489 PPMIBSRSwtSet "PPMI Belt Slack Reduction switch set";
CM_ SG_ 489 PPMIHW_SwtSet "PPMI Haptic Warning switch set";
CM_ SG_ 489 PPMIBSR_SwtSet "PPMI Belt Slack Reduction switch set";
CM_ SG_ 780 HUT_PhoneNextRoad "HUT_PhoneNumber
And HUT_PhoneName AndHUT_NextRoadName
Since UTF-8 variable length character encoding is adopted, coding is not defined in the signal matrix. For details, please refer to HUT-HUD interactive function requirement specification";
CM_ SG_ 623 CheckSum_HUT32 "Use the checksum strategy from document Ã¢Â€ÂœEnd-to-End Communication Protection SpecificationÃ¢Â€ÂADAS-CANFD To:HAP";
CM_ SG_ 623 ScrnOpSts "HUT screen operate statusADAS-CANFD To:HAP,PAS";
CM_ SG_ 623 XLvl "View's global X-coordinate signalADAS-CANFD To:HAP,PAS";
CM_ SG_ 623 YLvl "View's global Y-coordinate signalADAS-CANFD To:HAP,PAS";
CM_ SG_ 623 DetVideoLost "HUT detect video lostADAS-CANFD To:HAP,PAS";
CM_ SG_ 623 PrkgCtrlModReqValid "Parking control mode request validADAS-CANFD To:HAP";
CM_ SG_ 623 PrkgCtrlModReq "Parking control mode requestADAS-CANFD To:HAP";
CM_ SG_ 623 ContnPrkgReqValid "Continue parking request validADAS-CANFD To:HAP";
CM_ SG_ 623 ContnPrkgReq "Continue parking requestADAS-CANFD To:HAP";
CM_ SG_ 623 PrkStraightSwtReq_HUT "Remote parking straight Switch requestADAS-CANFD To:HAP";
CM_ SG_ 623 PrkStraightSuspendOrFinishReq_HU "User suspend or finish parking straight functionADAS-CANFD To:HAP";
CM_ SG_ 623 PrkStraightModSel_HUT "Remote parking straight mode selection requestADAS-CANFD To:HAP";
CM_ SG_ 623 PrkStraightSts_HUT "Remote parking straight statusADAS-CANFD To:HAP";
CM_ SG_ 623 PrkStraightStrtReq_HUT "Remote parking straight handshake requestADAS-CANFD To:HAP";
CM_ SG_ 623 PrkStraightVehStrtReq_HUT_Valid "Remote parking straight handshake request validADAS-CANFD To:HAP";
CM_ SG_ 623 PrkStraightContinueReq_HUT "Remote parking straight continue forward or backwark requestADAS-CANFD To:HAP";
CM_ SG_ 623 P2P_PrkgDirSwtReq "Point to Point Parking Direct Switch requestADAS-CANFD To:HAP";
CM_ SG_ 623 RainMode_Swt_Req "Request_of_rain_mode_switchADAS-CANFD To:ICU1.5";
CM_ SG_ 623 LCMode_Swt_Req "Request_of_lane_change_mode_switchADAS-CANFD To:ICU1.5";
CM_ SG_ 623 NavDecSwtReq "Request_of_Control_NavDec(Navigation_Deceleration__Recognition)_SwitchADAS1_CAN:To ICU1.5";
CM_ SG_ 623 RollingCounter_HUT32 "Rolling Counter_HUT32ADAS-CANFD To:HAP";
CM_ SG_ 493 FlaoutUnlockSet "Flameout unlock set";
CM_ SG_ 493 PrkInDirChoice "UsedÃ‚Â toÃ‚Â chooseÃ‚Â whetherÃ‚Â toÃ‚Â parkÃ‚Â inÃ‚Â frontÃ‚Â orÃ‚Â rear of carADAS-CANFD To:HAP";
CM_ SG_ 493 ADASDispSwt "ADAS display switch by HUT";
CM_ SG_ 493 NaviDispSwt "Navigation display switch by HUT";
CM_ SG_ 493 NaviDispSwt_VR "Navigation display switch by HUT(Voice Request)";
CM_ SG_ 493 ADASDispSwt_VR "ADAS display switch by HUT(Voice Request)";
CM_ SG_ 493 ApproachLampSet "Approach lamp set";
CM_ SG_ 493 SuperLockSet "Super lock set";
CM_ SG_ 493 ALCMDynModSet "ALCM dynamic mode set";
CM_ SG_ 493 RLWinSwtReq_VR "Rear left window Switch request status(Voice Request)";
CM_ SG_ 493 RRWinSwtReq_VR "Rear right window Switch request status(Voice Request)";
CM_ SG_ 493 DrvWinSwtReq_VR "Driver window Switch request status(Voice Request)";
CM_ SG_ 493 PassWinSwtReq_VR "Passenger window Switch request status(Voice Request)";
CM_ SG_ 493 ChairMemPosnSetSwt "Chair Memory Position Set switch";
CM_ SG_ 493 PathLrngFinshCmd "Path learning finished commandADAS-CANFD To:HAP";
CM_ SG_ 493 PathLrngStartCmd "Start path learning commandADAS-CANFD To:HAP";
CM_ SG_ 493 SelPrkOutDirReq "Select parking out direction requestADAS-CANFD To:HAP";
CM_ SG_ 493 StartPrkgPath2Cmd "Start parking path two commandADAS-CANFD To:HAP";
CM_ SG_ 493 DeletePath2Cmd "Delete path two commandADAS-CANFD To:HAP";
CM_ SG_ 493 StartPrkgPath1Cmd "Start parking path one commandADAS-CANFD To:HAP";
CM_ SG_ 493 DeletePath1Cmd "Delete path one commandADAS-CANFD To:HAP";
CM_ SG_ 493 SelPrkgFctnCmd "Select Parking function commandADAS-CANFD To:HAP";
CM_ SG_ 493 ParkMdlCmd "Parking mode change requestADAS-CANFD To:HAP";
CM_ SG_ 493 BackReq_APS "Back to AVM interface requestADAS-CANFD To:HAP";
CM_ SG_ 493 ACFGAEnaReq_TC "AC(Air Conditioning) Fragrance system enable request-Touch ControlBD1_CAN:To AC";
CM_ SG_ 493 ACFGAChanTyp_TC "AC(Air Conditioning) Fragrance Type Channel Select-Touch ControlBD1_CAN:To AC";
CM_ SG_ 493 ACFGALvlReq_TC "AC(Air Conditioning) Fragrance concentration request-Touch ControlBD1_CAN:To AC";
CM_ SG_ 493 P2P_PrkgDirectSwtCmd "P2P Parking Direction switch commandADAS1_CAN:To ICU1.5";
CM_ SG_ 880 TimeMod "Time ModeBD1-CAN To:WPC,AC,BLE
BD2-CAN To:ABM,AMP,SVM,ELD,TOD
PT_CAN:EDC
ADAS-CANFD To:IFC,HAP,PAS,IDC_L2
HC_CAN:To DCDC,BSG,BMS
BD_Sub_CAN:To DDCM,PDCM,DSC,HVSM,CP,RHVSM";
CM_ SG_ 880 TimeIndcn "Indicaion for  time :am or pmBD1-CAN To:WPC,AC,BLE
BD2-CAN To:ABM,AMP,SVM,ELD,TOD
PT_CAN:EDC
ADAS-CANFD To:IFC,HAP,PAS,IDC_L2
HC_CAN:To DCDC,BSG,BMS
BD_Sub_CAN:To DDCM,PDCM,DSC,HVSM,CP,RHVSM";
CM_ SG_ 880 Time_Hour "The value for hoursBD1-CAN To:CSA,ESCL,WPC,AC,BLE
BD2-CAN To:ABM,HUD,AMP,PPMI_D,PPMI_P,SBWM,SVM,ELD,TOD
PT_CAN To:ECM,ESP,TCU,Ibooster,EDC,EPS
ADAS-CANFD To:IFC,RSDS_R,RSDS_L,HAP,PAS,RPAS,CR_L,CR_R,ALS,IDC_L2
HC_CAN:To DCDC,BSG,BMS
BD_Sub_CAN:To DDCM,PDCM,DSC,HVSM,CP,RHVSM";
CM_ SG_ 880 Time_Minutes "The value for minutesBD1-CAN To:CSA,ESCL,WPC,AC,BLE
BD2-CAN To:ABM,HUD,AMP,PPMI_D,PPMI_P,SBWM,SVM,ELD,TOD
PT_CAN To:ECM,ESP,TCU,Ibooster,EDC,EPS
ADAS-CANFD To:IFC,RSDS_R,RSDS_L,HAP,PAS,RPAS,CR_L,CR_R,ALS,IDC_L2
HC_CAN:To DCDC,BSG,BMS
BD_Sub_CAN:To DDCM,PDCM,DSC,HVSM,CP,RHVSM";
CM_ SG_ 880 Time_Second "The value for secondsBD1-CAN To:AC
BD2-CAN To:ABM,HUD,AMP,SVM,ELD,TOD
PT_CAN To:TCU,Ibooster,EDC
ADAS-CANFD To:IFC,RSDS_R,RSDS_L,HAP,PAS,RPAS,CR_L,CR_R,ALS,IDC_L2
HC_CAN:To DCDC,BSG,BMS
BD_Sub_CAN:To DDCM,PDCM,DSC,HVSM,CP,RHVSM";
CM_ SG_ 880 Time_Year_Left "The value for yearsBD1-CAN To:CSA,ESCL,WPC,AC,BLE
BD2-CAN To:ABM,AMP,PPMI_D,PPMI_P,SBWM,SVM,ELD,TOD
PT_CAN To:ECM,ESP,TCU,Ibooster,EDC,EPS
ADAS-CANFD To:IFC,RSDS_R,RSDS_L,HAP,PAS,RPAS,CR_L,CR_R,ALS,IDC_L2
HC_CAN:To DCDC,BSG,BMS
BD_Sub_CAN:To DDCM,PDCM,DSC,HVSM,CP,RHVSM";
CM_ SG_ 880 Time_Year_Right "The value for yearsBD1-CAN To:CSA,ESCL,WPC,AC,BLE
BD2-CAN To:ABM,HUD,AMP,PPMI_D,PPMI_P,SBWM,SVM,ELD,TOD
PT_CAN To:ECM,ESP,TCU,Ibooster,EDC,EPS
ADAS-CANFD To:IFC,RSDS_R,RSDS_L,HAP,PAS,RPAS,CR_L,CR_R,ALS,IDC_L2
HC_CAN:To DCDC,BSG,BMS
BD_Sub_CAN:To DDCM,PDCM,DSC,HVSM,CP,RHVSM";
CM_ SG_ 880 Time_Month "The value for monthsBD1-CAN To:CSA,ESCL,WPC,AC,BLE
BD2-CAN To:ABM,HUD,AMP,PPMI_D,PPMI_P,SBWM,SVM,ELD,TOD
PT_CAN To:ECM,ESP,TCU,Ibooster,EDC,EPS
ADAS-CANFD To:IFC,RSDS_R,RSDS_L,HAP,PAS,RPAS,CR_L,CR_R,ALS,IDC_L2
HC_CAN:To DCDC,BSG,BMS
BD_Sub_CAN:To DDCM,PDCM,DSC,HVSM,CP,RHVSM";
CM_ SG_ 880 Time_Day "The value for daysBD1-CAN To:CSA,ESCL,WPC,AC,BLE
BD2-CAN To:ABM,HUD,AMP,PPMI_D,PPMI_P,SBWM,SVM,ELD,TOD
PT_CAN To:ECM,ESP,TCU,Ibooster,EDC,EPS
ADAS-CANFD To:IFC,RSDS_R,RSDS_L,HAP,PAS,RPAS,CR_L,CR_R,ALS,IDC_L2
HC_CAN:To DCDC,BSG,BMS
BD_Sub_CAN:To DDCM,PDCM,DSC,HVSM,CP,RHVSM";
CM_ SG_ 880 HUT_TgtSOCSet "Target value for custom SOC setPT-CAN To:PDCU";
CM_ SG_ 485 ACRearTempReq_ETC_VR "ETC Rear AC(Air Conditioning) Temperature  Request(Voice Request)";
CM_ SG_ 485 ACRearTempSteplsReq_ETC_TC "ETC Rear AC(Air Conditioning) Temperature Stepless Request-Touch Control";
CM_ SG_ 485 ACDrvTempDecReq_ETC_TC "ETC AC(Air Conditioning) Driver Temperature Decrease Request-Touch Control";
CM_ SG_ 485 ACDrvTempIncReq_ETC_TC "ETC AC(Air Conditioning) Driver Temperature Increase  Request-Touch Control";
CM_ SG_ 485 ACRearTempDecReq_ETC_TC "ETC Rear AC(Air Conditioning) Temperature Decrease Request-Touch Control";
CM_ SG_ 485 ACRearTempIncReq_ETC_TC "ETC Rear AC(Air Conditioning) Temperature Increase Request-Touch Control";
CM_ SG_ 485 ACRearPowerReq_VR "AC rear system power onoff request  for AC controlling  (Voice Request)BD1_CAN:To AC";
CM_ SG_ 485 ACMaxReq_VR "AC(Air Conditioning) Max Request-Voice RequestBD1_CAN:To AC";
CM_ SG_ 485 ACMaxReq_TC "AC(Air Conditioning) Max Request-Touch ControlBD1_CAN:To AC";
CM_ SG_ 485 FrntWiprCtrl_VR "Front Wiper Control (Voice Request)";
CM_ SG_ 485 ACRearAutoModReq_VR "Rear auto mode request for AC(Air Conditioning) controlling  (Voice Request)BD1_CAN:To AC";
CM_ SG_ 485 LockWinSet "Lock Window Set";
CM_ SG_ 485 ACRearLockReq_TC "Rear AC(Air Conditioning) Lock Request by HUT(Head Unit System)-Touch ControlBD1_CAN:To AC";
CM_ SG_ 485 SrSpdCtrlSwt "Sunroof speed control switch";
CM_ SG_ 485 DPF_Request "DPF RequestPT-CAN To:ECM";
CM_ SG_ 485 ColorCategory "Color category";
CM_ SG_ 485 SingleColorNr "Single color number";
CM_ SG_ 487 ACRLTempDecReq_TC "AC(Air Conditioning) Rear Left Temperature Decrease Request-Touch ControlBD1_CAN:To AC";
CM_ SG_ 487 ACRLTempIncReq_TC "AC(Air Conditioning) Rear Left  Temperature Increase Request-Touch ControlBD1_CAN:To AC";
CM_ SG_ 487 ACRLTempReq_VR "AC(Air Conditioning) Rear Left  Temperature  Request(Voice Request)BD1_CAN:To AC";
CM_ SG_ 487 ACRRTempDecReq_TC "AC(Air Conditioning) Rear Right Temperature Decrease Request-Touch Control";
CM_ SG_ 487 ACRRTempIncReq_TC "AC(Air Conditioning) Rear Right Temperature Increase Request-Touch Control";
CM_ SG_ 487 ACRRTempReq_VR "AC(Air Conditioning) Rear Right Temperature  Request(Voice Request)";
CM_ SG_ 487 ACRRTempSteplsReq_TC "AC(Air Conditioning) Rear Right Temperature Stepless Request-Touch Control";
CM_ SG_ 487 ACHumidifierReq_VR "AC(Air Conditioning) Humidifier Request(Voice Request)";
CM_ SG_ 487 ACHumidifierReq_TC "AC(Air Conditioning) Humidifier Request-Touch Control";
CM_ SG_ 487 ACOzoneReq_TC "AC(Air Conditioning) Air Ozone Unit Request-Touch Control";
CM_ SG_ 487 ACOzoneReq_VR "AC(Air Conditioning) Air Ozone Unit Request(Voice Request)";
CM_ SG_ 487 ACUltravioletReq_TC "AC(Air Conditioning) Ultraviolet Rays Unit request-Touch Control";
CM_ SG_ 487 ACUltravioletReq_VR "AC(Air Conditioning) Ultraviolet Rays Unit request(Voice Request)";
CM_ SG_ 487 ACFrntWinHeatCmd_TC "AC(Air Conditioning) Front Window Heat Command-Touch Control";
CM_ SG_ 487 ACFrntWinHeatCmd_VR "AC(Air Conditioning) Front Window Heat Command(Voice Request)";
CM_ SG_ 487 DrvDoorALCMFlashFreq "Driver door ALCM flash frequency";
CM_ SG_ 487 PassDoorALCMFlashFreq "Passenger door ALCM flash frequency";
CM_ SG_ 487 LRDoorALCMFlashFreq "Left rear door ALCM flash frequency";
CM_ SG_ 487 RRDoorALCMFlashFreq "Right rear door ALCM flash frequency";
CM_ SG_ 487 FootALCMFlashFreq "Foot ALCM flash frequency";
CM_ SG_ 487 LeftPanelALCMFlashFreq "Left panel ALCM flash frequency";
CM_ SG_ 487 RightPanelALCMFlashFreq "Right panel ALCM flash frequency";
CM_ SG_ 487 ACRearLockReq_VR "Rear AC(Air Conditioning) Lock Request by HUT(Head Unit System)-Voice RequestBD1_CAN:To AC";
CM_ SG_ 491 ActvEntryLockSet "Active entry lock set";
CM_ SG_ 491 ActvEntryUnlockSet "Active entry unlock set";
CM_ SG_ 491 LockPromptFunSet "Unlock prompt function Settings";
CM_ SG_ 491 BTAPAEntryLockSet "Bluetooth APA entry lock set";
CM_ SG_ 491 BTAPALvngUnlockSet "Bluetooth APA leaving unlock set";
CM_ SG_ 491 ClsWinSpdSet "Close windows speed set";
CM_ SG_ 491 DrvSeatMassgLvlSet "Driver Seat massage level setBD_Sub_CAN:To DSC";
CM_ SG_ 491 PassSeatMassgLvlSet "Passenger Seat massage level setBD_Sub_CAN:To DSC";
CM_ SG_ 491 SeatKeyMemEna "Seat key memory enablement";
CM_ SG_ 491 RLSeatMassgLvlSet "Rear Left Seat massage level setBD_Sub_CAN:To DSC";
CM_ SG_ 491 RRSeatMassgLvlSet "Rear Right Seat massage level setBD_Sub_CAN:To DSC";
CM_ SG_ 491 DrvDoorALCMClrSet "Driver door ALCM color set";
CM_ SG_ 491 PassDoorALCMClrSet "Passenger door ALCM color set";
CM_ SG_ 491 LRDoorALCMClrSet "Left rear door ALCM color set";
CM_ SG_ 491 DrvDoorALCMSwt "Driver door ALCM switch";
CM_ SG_ 491 PassDoorALCMSwt "Passenger door ALCM switch";
CM_ SG_ 877 DrvSeatVentnLvlSet "Driver Seat ventilation level set";
CM_ SG_ 877 PassSeatVentnLvlSet "Passenger Seat ventilation level set";
CM_ SG_ 877 ACAutoModReq_VR "Auto mode request for AC(Air Conditioning) controlling  (Voice Request)BD1-CAN To:AC";
CM_ SG_ 877 ACCmprReq_VR "Compressor Request  for AC(Air Conditioning) controlling(Voice Request)BD1-CAN To:AC";
CM_ SG_ 877 ACPowerReq_VR "AC system power onoff request  for AC controlling  (Voice Request)BD1-CAN To:AC";
CM_ SG_ 877 ACBlwrSpdReq_VR "Blower speed request  for AC(Air Conditioning) controlling  (Voice Request)BD1-CAN To:AC";
CM_ SG_ 877 ACDrvTempReq_VR "Driver side temperature request  for AC(Air Conditioning) controlling  (Voice Request)BD1-CAN To:AC";
CM_ SG_ 877 ACFrntDefrostReq_VR "Front defrost request  for AC(Air Conditioning) controlling  (Voice Request)BD1-CAN To:AC";
CM_ SG_ 877 ACDrvAirDistribModReq_VR "Driver Air Distribution Mode Request for AC(Air Conditioning) controlling  (Voice Request)BD1-CAN To:AC";
CM_ SG_ 877 ACAirInletReq_VR "Air Conditioning FreshRecirculation mode request for AC controlling  (Voice Request)BD1-CAN To:AC";
CM_ SG_ 877 ACModReq_HUT "AC mode request by HUT(Head Unit System)";
CM_ SG_ 877 ElecSideSteppingSysSet "Electric side stepping system set";
CM_ SG_ 877 RoofModSet "Roof mode set";
CM_ SG_ 877 AllTerrainDislSet "All terrain disable set";
CM_ SG_ 877 RemUpgrdSts "Remote upgrade mode";
CM_ SG_ 877 ACRearAutoModReq_TC "Rear AC(Air Conditioning) Auto Mode Request-Touch ControlBD1-CAN:To AC";
CM_ SG_ 877 DrvSeatSupportLvlSet "Driver Seat supporting level set";
CM_ SG_ 877 PassSeatSupportLvlSet "Passenger Seat supporting level set";
CM_ SG_ 877 ACRearOffReq_TC "Rear Off AC Request  by HUT-Touch ControlBD1-CAN:To AC";
CM_ SG_ 877 ACRearAirDistribModReq_TC "AC(Air Conditioning) Rear Air Distribution Mode Request-Touch ControlBD1-CAN:To AC";
CM_ SG_ 877 RLSeatVentnLvlSet "Rear Left Seat ventilation level set";
CM_ SG_ 877 RRSeatVentnLvlSet "Rear Right Seat ventilation level set";
CM_ SG_ 548 ALCMMasterSwt "ALCM master switch";
CM_ SG_ 548 ALCMPartitionSwt "ALCM partition switch";
CM_ SG_ 548 MusicFrq0 "Music frequency 0";
CM_ SG_ 548 MusicFrq1 "Music frequency 1";
CM_ SG_ 548 MusicFrq2 "Music frequency 2";
CM_ SG_ 548 MusicFrq3 "Music frequency 3";
CM_ SG_ 548 MusicFrq4 "Music frequency 4";
CM_ SG_ 548 MusicFrq5 "Music frequency 5";
CM_ SG_ 548 MusicFrq6 "Music frequency 6";
CM_ SG_ 507 RRDoorALCMClrSet "Right rear door ALCM color set";
CM_ SG_ 507 LeftPanelALCMClrSet "Left panel ALCM color set";
CM_ SG_ 507 RightPanelALCMClrSet "Right panel ALCM color set";
CM_ SG_ 507 FootALCMClrSet "Foot ALCM color set";
CM_ SG_ 507 DrvDoorALCMLightLvlSet "Driver door ALCM light level set";
CM_ SG_ 507 PassDoorALCMLightLvlSet "Passenger door ALCM light level set";
CM_ SG_ 507 LRDoorALCMLightLvlSet "Left rear door ALCM light level set";
CM_ SG_ 507 RRDoorALCMLightLvlSet "Right rear door ALCM light level set";
CM_ SG_ 507 LeftPanelALCMLightLvlSet "Left panel ALCM light level set";
CM_ SG_ 507 RightPanelALCMLightLvlSet "Right panel ALCM light level set";
CM_ SG_ 507 FootALCMLightLvlSet "Foot ALCM light level set";
CM_ SG_ 507 ALCMFloSwt "Flowing mode Swtich";
CM_ SG_ 507 ALCMBreSwt "Breathing mode Swtich";
CM_ SG_ 507 RightPanelALCMSwt "Right panel ALCM switch";
CM_ SG_ 507 LRDoorALCMSwt "Left rear door ALCM switch";
CM_ SG_ 507 RRDoorALCMSwt "Right rear door ALCM switch";
CM_ SG_ 507 FootALCMSwt "Foot ALCM switch";
CM_ SG_ 507 RoofALCMSwt "Roof ALCM switch";
CM_ SG_ 507 LeftPanelALCMSwt "Left panel ALCM switch";
CM_ SG_ 505 ACRLTempSteplsReq_TC "AC(Air Conditioning) Rear Left  Temperature Stepless  Request-Touch ControlBD1_CAN:To AC";
CM_ SG_ 509 RLSeatMassgModSet "Rear Left Seat massage mode setBD_Sub_CAN:To DSC";
CM_ SG_ 509 RRSeatMassgModSet "Rear Right Seat massage mode setBD_Sub_CAN:To DSC";
CM_ SG_ 509 DrvSeatHeatgLvlSet_Nine "Driver Seat Heating 9 level  set";
CM_ SG_ 509 PassSeatHeatgLvlSet_Nine "Passenger Seat Heating 9 level set";
CM_ SG_ 509 RLSeatHeatgLvlSet_Nine "Rear Left Passenger Seat Heating 9 level set";
CM_ SG_ 509 RRSeatHeatgLvlSet_Nine "Rear Right Passenger Seat Heating 9 level set";
CM_ SG_ 476 PassSeatMassgModSet "Passenger Seat massage mode setBD_Sub_CAN:To DSC";
CM_ SG_ 476 DrvSeatMassgModSet "Driver Seat massage mode setBD_Sub_CAN:To DSC";
CM_ SG_ 476 PPMI_P_BSR_SwtSet "PPMI_P Belt Slack Reduction switch set";
CM_ SG_ 476 RWPC_SwtReq "RWPC switch request";
CM_ SG_ 477 DrvSeatVentnLvlSet_Nine "Driver Seat ventilation 9 level setTo:DSC HVSM";
CM_ SG_ 477 PassSeatVentnLvlSet_Nine "Passenger Seat ventilation 9 level setTo:DSC HVSM";
CM_ SG_ 477 RLSeatVentnLvlSet_Nine "Rear Left Seat ventilation 9 level set";
CM_ SG_ 477 RRSeatVentnLvlSet_Nine "Rear Right Seat ventilation 9 level set";
CM_ SG_ 477 ARFSwtReq "Adaptive Recuperation function requestPT-CAN To:PDCU";
CM_ SG_ 477 ASFCSwtReq "Adaptive startstop control function requestPT-CAN To:PDCU";
CM_ SG_ 477 AGSSwtReq "Adaptive gear shifting function requestPT-CAN To:PDCU";
CM_ SG_ 477 SOCMngmntSwtReq "Soc management function requestPT-CAN To:PDCU";
CM_ SG_ 74 AUTODefrost_TC "AUTO Defrost Request-Touch ControlBD1-CAN:To AC";
CM_ SG_ 74 AUTODefrost_VR "AUTO Defrost request for AC controlling  (Voice Request)BD1-CAN:To AC";
CM_ SG_ 74 LaneCalActvtCmd "Lane-Calibration Activate CommandADAS-CANFD To:HAP,PAS";
CM_ SG_ 74 MODChgReq "MOD change requestADAS-CANFD To:HAP,PAS";
CM_ SG_ 74 Radar_DispCmd "Used to configure the display mothod of guidance overlayADAS-CANFD To:HAP,PAS";
CM_ SG_ 74 Guid_Ovl_Display_Cmd "Used to configure the display mothod of guidance overlayADAS-CANFD To:HAP,PAS";
CM_ SG_ 74 Sgl_View_Sel "Single View SelectionADAS-CANFD To:HAP,PAS";
CM_ SG_ 74 SwToFieldCalRstCmd "Return to Auto or Manual  Calibration Result commandADAS-CANFD To:HAP,PAS";
CM_ SG_ 74 AutoViewChgCmd "Auto change view function switchADAS-CANFD To:HAP,PAS";
CM_ SG_ 74 MdlColrChgCmd "Switch the color of car modelADAS-CANFD To:HAP,PAS";
CM_ SG_ 74 CarMdlTrsprcySwtCmd "Car Model Transparency Switch CommandADAS-CANFD To:HAP,PAS";
CM_ SG_ 74 CarMdlDispCmd "Change 2D3D display mode commandADAS-CANFD To:HAP,PAS";
CM_ SG_ 74 AutoAVMSwSet_Cmd "Auto Around view swtich command to AVM.ADAS-CANFD To:HAP,PAS";
CM_ SG_ 74 FPAS_AutoModSwt "Front Park Assistant System Automatic mode RequestADAS-CANFD To:HAP,PAS";
CM_ SG_ 74 MEBSwtSet "Maneuver Braking Assistance  switch SetADAS-CANFD To:HAP,PAS,RPAS";
CM_ SG_ 74 WshSoftSwt "Car wash function softswitchADAS-CANFD To:HAP,PAS";
CM_ SG_ 74 View_SoftswitchCmd "View mode SoftswitchADAS-CANFD To:HAP,PAS";
CM_ SG_ 465 AntiDisIdnResp "Anti-dismantle identification responseBD1_CAN:To ETC";
CM_ SG_ 288 IB_Warn "iBooster requests the yellow warning lamp in the dashboard";
CM_ SG_ 573 Checksum_IFC3 "Use the checksum strategy from document Ã¢Â€ÂœEnd-to-End Communication Protection SpecificationÃ¢Â€Â";
CM_ SG_ 573 LDWResp "Indicate LDW(Lane Detection Warning) Switch status";
CM_ SG_ 573 LKAResp "Indicate LKA(Ã‚Â Lane Keeping Assist) Switch status";
CM_ SG_ 573 LCKResp "Indicate LCK(Ã‚Â Lane Center Keeping ) Switch status";
CM_ SG_ 573 ELKResp "Indicate ELK(Ã‚Â Emergency Lane Keeping ) Switch status";
CM_ SG_ 573 LDW_LKA_Snvty "LDW(Lane Detection Warning)_LKA(Ã‚Â Lane Keeping Assist)   Sensitivity";
CM_ SG_ 573 IFCHUTInterface "This signal indicates if IFC and HUT communication  interface is available or not.";
CM_ SG_ 573 LSSWarnFormResp "LSS Warning Form Switch status";
CM_ SG_ 573 LSSResp "Indicate LSS(Ã‚Â Lane Support System ) Switch status";
CM_ SG_ 573 AESSts "AES function statusIP Received";
CM_ SG_ 573 ESSSts "ESS function statusIP Received";
CM_ SG_ 573 AESErrSts "AES function error statusIP Received";
CM_ SG_ 573 ESSErrSts "ESS function error statusIP Received";
CM_ SG_ 573 RollingCounter_IFC3 "RollingCounter_IFC3";
CM_ SG_ 573 Checksum_IFC4 "Use the checksum strategy from document Ã¢Â€ÂœEnd-to-End Communication Protection SpecificationÃ¢Â€Â";
CM_ SG_ 573 IFC_Handsoffwarn "Hands Off Warning";
CM_ SG_ 573 IFCCalibrationSts "Lane Detection Warning Calibration Status
IFC Calibration StatusIP Received";
CM_ SG_ 573 CameraBlockageSts "Camera Blockage StatusIP Received";
CM_ SG_ 573 LDW_LKAWarn "LDW waring statusIP Received";
CM_ SG_ 573 LSSIntervention "LSS(Lane Support System)  torque intercention statusIP Received";
CM_ SG_ 573 LSSFuncSts "LSS(Lane Support System) statusIP Received";
CM_ SG_ 573 ELKMainState "ELK Main State";
CM_ SG_ 573 LaneAvailability "Lane availabilityIP Received";
CM_ SG_ 573 TJA_FollowSts "Indicator TJA function lateral control's following status";
CM_ SG_ 573 LSSErrSts "LSS(Lane Support System)  error status.IP Received";
CM_ SG_ 573 AESintervention "AES intervention statusIP Received";
CM_ SG_ 573 ESSintervention "ESS intervention statusIP Received";
CM_ SG_ 573 ELKActSts "ELK function active status";
CM_ SG_ 573 IntelligentEvaActSts "Intelligent Evade function active status";
CM_ SG_ 573 LCKStsIndcr "LCK(Lane Center Keeping) Status Indicator";
CM_ SG_ 573 RollingCounter_IFC4 "RollingCounter_IFC4";
CM_ SG_ 573 Checksum_IFC5 "Use the checksum strategy from document Ã¢Â€ÂœEnd-to-End Communication Protection SpecificationÃ¢Â€Â";
CM_ SG_ 573 IFC_LaneCurve "Lane curatureIP Received";
CM_ SG_ 573 IFC_LeLaneTyp "Left lane typeIP Received";
CM_ SG_ 573 IFC_RiLaneTyp "Right lane typeIP Received";
CM_ SG_ 573 IFC_NextLeLaneTyp "Left Next lane typeIP Received";
CM_ SG_ 573 IFC_NextRiLaneTyp "Right Next lane typeIP Received";
CM_ SG_ 573 IFC_LeLane_dy "Distance from the vehicle to the left next laneIP Received";
CM_ SG_ 573 IFC_RiLane_dy "Distance from the vehicle to the right next laneIP Received";
CM_ SG_ 573 RollingCounter_IFC5 "RollingCounter_IFC5";
CM_ SG_ 573 Checksum_IFC6 "Use the checksum strategy from document Ã¢Â€ÂœEnd-to-End Communication Protection SpecificationÃ¢Â€Â";
CM_ SG_ 573 IFC_NextLeLane_dy "Distance from the vehicle to the left lane";
CM_ SG_ 573 IFC_NextRiLane_dy "Distance from the vehicle to the right lane";
CM_ SG_ 573 RollingCounter_IFC6 "RollingCounter_IFC6";
CM_ SG_ 573 AESResp "Indicate AES(Automatic Emergency Steering) Switch status";
CM_ SG_ 573 ESS_Pedresp "ESS(Evasive Steering Support)-Pedestrian switch status response";
CM_ SG_ 573 ESS_Vehresp "ESS(Evasive Steering Support)-Vehicle switch status response";
CM_ SG_ 573 IntelligentEvaResp "Intelligent evade switch status response";
CM_ SG_ 573 MAC_Check_IFC_FD2 "MAC protection mechanism should comply with the GWM MAC Specificatio";
CM_ SG_ 719 TSRResp "Indicate TSR(Traffic Sign Recognition) switch status";
CM_ SG_ 719 TSRSpdLimUnit "Indicate speed limit unit of current rode";
CM_ SG_ 719 TSRSpdLim "Indicate the value of speed limit sign detected by cameraIP Received";
CM_ SG_ 719 TSRSpdLimCfdc "Indicate the confidience of the speed limit";
CM_ SG_ 719 TSRSts "Indicate current mode of the TSR(Traffic Sign Recognition)IP Received";
CM_ SG_ 719 TSRSpdLimSts "Indicate speed limit status of current roadIP Received";
CM_ SG_ 719 TSRTrfcSignValCfdc "Indicate the confidience of the traffic sign";
CM_ SG_ 719 TSRTrfcSignVal "Indicate the value of speed limit sign detected by cameraIP Received";
CM_ SG_ 719 TSRSpdLimWarn "Request to warn when this vehicle speed is over speed limitIP Received";
CM_ SG_ 719 TSRWarnResp "Indicate TSR(Traffic Sign Warning) switch status";
CM_ SG_ 719 TSR_Snvty "TSR Warning offsetIP Received";
CM_ SG_ 719 IDC_L2_TurnLightReq "Open the Turn light from IDC_L2";
CM_ SG_ 719 HWA_ALC_Trig "Trigger for ALC";
CM_ SG_ 719 HWA_WarnInfoDisp "HWA warning for driver";
CM_ SG_ 719 HWA_TakOver_Trig "triggers for takeoverÃ¦ÂŽÂ¥Ã§Â®Â¡Ã¨Â§Â¦Ã¥ÂÂ‘Ã¥ÂŽÂŸÃ¥Â›Â ";
CM_ SG_ 719 HWA_TakOver_Req "requests for takeoverÃ¨Â¯Â·Ã¦Â±Â‚Ã¦ÂŽÂ¥Ã§Â®Â¡";
CM_ SG_ 719 MRC_InterSysInfoDisp "MRC warning for driver";
CM_ SG_ 719 MRC_TakOver_Req "requests for MRC takeover MRCÃ¦ÂŽÂ¥Ã§Â®Â¡Ã¨Â¯Â·Ã¦Â±Â‚";
CM_ SG_ 719 NOH_WarnInfoDisp "NOH warning for driver";
CM_ SG_ 719 IFC_Line01_Source "source of Line 01 detectionÃ¨Â½Â¦Ã©ÂÂ“Ã§ÂºÂ¿Ã¦Â£Â€Ã¦ÂµÂ‹Ã¦ÂÂ¥Ã¦ÂºÂ";
CM_ SG_ 719 IFC_Line02_Source "source of Line 02 detectionÃ¨Â½Â¦Ã©ÂÂ“Ã§ÂºÂ¿Ã¦Â£Â€Ã¦ÂµÂ‹Ã¦ÂÂ¥Ã¦ÂºÂ";
CM_ SG_ 719 TSR_Traffic_Light_Posn "Position of traffic lightÃ¤ÂºÂ¤Ã©Â€ÂšÃ§ÂÂ¯Ã§ÂšÂ„Ã¤Â½ÂÃ§Â½Â®";
CM_ SG_ 719 Stop_Mark_Detn "existence of stop lineÃ¥ÂÂœÃ¦Â­Â¢Ã§ÂºÂ¿Ã¦Â˜Â¯Ã¥ÂÂ¦Ã¥Â­Â˜Ã¥ÂœÂ¨";
CM_ SG_ 719 Stop_Mark_Dx "longitudinal distance of stop lineÃ¥ÂÂœÃ¦Â­Â¢Ã§ÂºÂ¿Ã¨Â·ÂÃ¨Â‡ÂªÃ¨Â½Â¦Ã§ÂšÂ„Ã§ÂºÂµÃ¥ÂÂ‘Ã¨Â·ÂÃ§Â¦Â»";
CM_ SG_ 719 Zebra_Mark_Detn "existence of zebra lineÃ¦Â–Â‘Ã©Â©Â¬Ã§ÂºÂ¿Ã¦Â˜Â¯Ã¥ÂÂ¦Ã¥Â­Â˜Ã¥ÂœÂ¨";
CM_ SG_ 719 Grid_Mark_Detn "existence of grid lineÃ§Â½Â‘Ã¦Â Â¼Ã§ÂºÂ¿Ã¦Â˜Â¯Ã¥ÂÂ¦Ã¥Â­Â˜Ã¥ÂœÂ¨";
CM_ SG_ 719 HWA_InhibitWarn "i-pilot faultsÃ¦Â™ÂºÃ¦Â…Â§Ã¥Â·Â¡Ã¨ÂˆÂªÃ¤Â¸ÂÃ¥ÂÂ¯Ã§Â”Â¨Ã¥ÂŽÂŸÃ¥Â›Â ";
CM_ SG_ 719 LaneChngCfmSwt_Resp "controller response  for the switch of lane change manual confirmationÃ§Â”Â¨Ã¦ÂˆÂ·Ã©Â€ÂšÃ¨Â¿Â‡Ã¤Â¸Â­Ã¦ÂŽÂ§Ã¨Â®Â¾Ã§Â½Â®Ã§Â•ÂŒÃ©ÂÂ¢Ã¨Â®Â¾Ã§Â½Â®Ã¦Â„ÂÃ¥Â›Â¾Ã§Â¡Â®Ã¨Â®Â¤Ã¥ÂŠÂŸÃ¨ÂƒÂ½Ã¤Â¸ÂºÃ¥Â¼Â€Ã¥ÂÂ¯Ã¦ÂˆÂ–Ã¥Â…Â³Ã©Â—Â­Ã¦Â—Â¶Ã¯Â¼ÂŒADASÃ¦ÂŽÂ§Ã¥ÂˆÂ¶Ã¥Â™Â¨Ã¥ÂÂ‘Ã©Â€ÂÃ§ÂšÂ„Ã¥ÂÂÃ©Â¦ÂˆÃ¤Â¿Â¡Ã¥ÂÂ·";
CM_ SG_ 719 ALC_SwtReq_Resp "controller response for the switch of automated lane changeÃ¨Â‡ÂªÃ¥ÂŠÂ¨Ã¥ÂÂ˜Ã©ÂÂ“Ã¨Â¾Â…Ã¥ÂŠÂ©Ã¥ÂŠÂŸÃ¨ÂƒÂ½Ã¥Â¼Â€Ã¥Â…Â³(Ã¦ÂŒÂ‰Ã¨Â®Â°Ã¥Â½Â•Ã§ÂšÂ„Ã§ÂŠÂ¶Ã¦Â€ÂÃ¨Â¿Â›Ã¨Â¡ÂŒÃ¥ÂÂ‘Ã©Â€Â)Ã§ÂšÂ„Ã¥ÂÂÃ©Â¦ÂˆÃ¤Â¿Â¡Ã¥ÂÂ·";
CM_ SG_ 719 AutoSpdSetSwt_Resp "controller response for the auto speed set switchÃ¨Â‡ÂªÃ¥ÂŠÂ¨Ã¨Â°ÂƒÃ¨ÂŠÂ‚Ã¨Â½Â¦Ã¨Â¾Â†Ã©Â™ÂÃ©Â€ÂŸÃ¥ÂŠÂŸÃ¨ÂƒÂ½Ã¥Â¼Â€Ã¥Â…Â³(Ã¦ÂŒÂ‰Ã¨Â®Â°Ã¥Â½Â•Ã§ÂšÂ„Ã§ÂŠÂ¶Ã¦Â€ÂÃ¨Â¿Â›Ã¨Â¡ÂŒÃ¥ÂÂ‘Ã©Â€Â)Ã§ÂšÂ„Ã¥ÂÂÃ©Â¦ÂˆÃ¤Â¿Â¡Ã¥ÂÂ·";
CM_ SG_ 719 VoiceBrdcSwt_Resp "controller response for the voice ONOFF switchÃ§Â”Â¨Ã¦ÂˆÂ·Ã¦Â‰Â“Ã¥Â¼Â€Ã¥Â’ÂŒÃ¥Â…Â³Ã©Â—Â­Ã¨Â¯Â­Ã©ÂŸÂ³Ã¦Â’Â­Ã¦ÂŠÂ¥Ã§ÂšÂ„Ã¦ÂƒÂ…Ã¥Â†ÂµÃ¯Â¼ÂˆÃ§Â”Â¨Ã¤ÂºÂŽÃ¦Â•Â°Ã¦ÂÂ®Ã¥Â›ÂžÃ¤Â¼Â Ã¯Â¼Â‰Ã§ÂšÂ„Ã¥ÂÂÃ©Â¦ÂˆÃ¤Â¿Â¡Ã¥ÂÂ·";
CM_ SG_ 719 UsrManSts_Resp "controller response for the survey of user manual usage Ã§Â”Â¨Ã¦ÂˆÂ·Ã¦Â‰Â“Ã¥Â¼Â€Ã¥Â’ÂŒÃ¥Â…Â³Ã©Â—Â­Ã¦Â–Â°Ã¦Â‰Â‹Ã¦Â•Â™Ã§Â¨Â‹Ã§ÂšÂ„Ã¦ÂƒÂ…Ã¥Â†ÂµÃ¯Â¼ÂˆÃ§Â”Â¨Ã¤ÂºÂŽÃ¦Â•Â°Ã¦ÂÂ®Ã¥Â›ÂžÃ¤Â¼Â Ã¯Â¼Â‰Ã§ÂšÂ„Ã¥ÂÂÃ©Â¦ÂˆÃ¤Â¿Â¡Ã¥ÂÂ·";
CM_ SG_ 719 Grid_Mark_Dx "longitudinal distance of grid lineÃ§Â½Â‘Ã¦Â Â¼Ã§ÂºÂ¿Ã¨Â·ÂÃ¨Â‡ÂªÃ¨Â½Â¦Ã§ÂšÂ„Ã§ÂºÂµÃ¥ÂÂ‘Ã¨Â·ÂÃ§Â¦Â»";
CM_ SG_ 719 Zebra_Mark_Dx "longitudinal distance of zebra lineÃ¦Â–Â‘Ã©Â©Â¬Ã§ÂºÂ¿Ã¨Â·ÂÃ¨Â‡ÂªÃ¨Â½Â¦Ã§ÂšÂ„Ã§ÂºÂµÃ¥ÂÂ‘Ã¨Â·ÂÃ§Â¦Â»";
CM_ SG_ 719 TSR_Traffic_Light "Color of traffic lightÃ¤ÂºÂ¤Ã©Â€ÂšÃ§ÂÂ¯Ã§ÂšÂ„Ã©Â¢ÂœÃ¨Â‰Â²";
CM_ SG_ 719 TSR_Traffic_Light_Through "Color of through traffic lightÃ§Â›Â´Ã¨Â¡ÂŒÃ¤ÂºÂ¤Ã©Â€ÂšÃ§ÂÂ¯Ã§ÂšÂ„Ã©Â¢ÂœÃ¨Â‰Â²";
CM_ SG_ 719 TSR_Traffic_Light_Le "Color of left turn traffic lightÃ¥Â·Â¦Ã¨Â½Â¬Ã¤ÂºÂ¤Ã©Â€ÂšÃ§ÂÂ¯Ã§ÂšÂ„Ã©Â¢ÂœÃ¨Â‰Â²";
CM_ SG_ 719 TSR_Traffic_Light_Ri "Color of right turn traffic lightÃ¥ÂÂ³Ã¨Â½Â¬Ã¤ÂºÂ¤Ã©Â€ÂšÃ§ÂÂ¯Ã§ÂšÂ„Ã©Â¢ÂœÃ¨Â‰Â²";
CM_ SG_ 719 RainMode_Swt_Resp "Response_of_rain_mode_switch";
CM_ SG_ 719 LCMode_Swt_Resp "Response_of_lane_change_mode_switch";
CM_ SG_ 719 NavDecSwtResp "Indicate_NavDec(Navigation_Deceleration__Recognition)_Switch_status";
CM_ SG_ 415 IFC_Line01_Dy "Dy at position of DxStart  (not always x=0, because of high values for 2nd segment)";
CM_ SG_ 415 IFC_Line01_Curv "Curvature of the Line, also called kappa";
CM_ SG_ 415 IFC_Line01_CurvChange "Currvature change or alteration of the Line, also called kappaDt";
CM_ SG_ 415 IFC_Line01_Type "Type of the Line";
CM_ SG_ 415 IFC_Line02_Dy "Dy at position of DxStart  (not always x=0, because of high values for 2nd segment)";
CM_ SG_ 415 IFC_Line02_Curv "Curvature of the Line, also called kappa";
CM_ SG_ 415 IFC_Line02_CurvChange "Currvature change or alteration of the Line, also called kappaDt";
CM_ SG_ 415 IFC_Line02_Type "Type of the Line";
CM_ SG_ 415 IFC_Line03_Dy "Dy at position of DxStart  (not always x=0, because of high values for 2nd segment)";
CM_ SG_ 415 IFC_Line03_Curv "Curvature of the Line, also called kappa";
CM_ SG_ 415 IFC_Line03_CurvChange "Currvature change or alteration of the Line, also called kappaDt";
CM_ SG_ 415 IFC_Line03_Type "Type of the Line";
CM_ SG_ 415 IFC_Line04_Dy "Dy at position of DxStart  (not always x=0, because of high values for 2nd segment)";
CM_ SG_ 415 IFC_Line04_Curv "Curvature of the Line, also called kappa";
CM_ SG_ 415 IFC_Line04_CurvChange "Currvature change or alteration of the Line, also called kappaDt";
CM_ SG_ 415 IFC_Line04_Type "Type of the Line";
CM_ SG_ 415 IFC_Roadedge01_Dy "Dy at position of DxStart  (not always x=0, because of high values for 2nd segment)";
CM_ SG_ 415 IFC_Roadedge01_Curv "Curvature of the Line, also called kappa";
CM_ SG_ 415 IFC_Roadedge01_CurvChange "Currvature change or alteration of the Line, also called kappaDt";
CM_ SG_ 415 IFC_Roadedge01_Type "Type of the Line";
CM_ SG_ 415 IFC_Roadedge02_Dy "Dy at position of DxStart  (not always x=0, because of high values for 2nd segment)";
CM_ SG_ 415 IFC_Roadedge02_Curv "Curvature of the Line, also called kappa";
CM_ SG_ 415 IFC_Roadedge02_CurvChange "Currvature change or alteration of the Line, also called kappaDt";
CM_ SG_ 415 IFC_Roadedge02_Type "Type of the Line";
CM_ SG_ 546 IFC_Line01_DxStart "Longitudinal start point of the line, also called dxStart";
CM_ SG_ 546 IFC_Line01_DxEnd "Longitudinal range of the line, also called dxEnd";
CM_ SG_ 546 IFC_Line01_HeadingAngle "Heading angle, difference in yaw angle between vehicle heading and Line";
CM_ SG_ 546 IFC_Line02_HeadingAngle "Heading angle, difference in yaw angle between vehicle heading and Line";
CM_ SG_ 546 IFC_Line02_DxStart "Longitudinal start point of the line, also called dxStart";
CM_ SG_ 546 IFC_Line02_DxEnd "Longitudinal range of the line, also called dxEnd";
CM_ SG_ 546 IFC_Line03_DxStart "Longitudinal start point of the line, also called dxStart";
CM_ SG_ 546 IFC_Line03_DxEnd "Longitudinal range of the line, also called dxEnd";
CM_ SG_ 546 IFC_Line03_HeadingAngle "Heading angle, difference in yaw angle between vehicle heading and Line";
CM_ SG_ 546 IFC_Line04_DxStart "Longitudinal start point of the line, also called dxStart";
CM_ SG_ 546 IFC_Line04_HeadingAngle "Heading angle, difference in yaw angle between vehicle heading and Line";
CM_ SG_ 546 IFC_Line04_DxEnd "Longitudinal range of the line, also called dxEnd";
CM_ SG_ 546 IFC_Roadedge01_DxStart "Longitudinal start point of the line, also called dxStart";
CM_ SG_ 546 IFC_Roadedge01_DxEnd "Longitudinal range of the line, also called dxEnd";
CM_ SG_ 546 IFC_Roadedge01_HeadingAngle "Heading angle, difference in yaw angle between vehicle heading and Line";
CM_ SG_ 546 IFC_Roadedge02_DxStart "Longitudinal start point of the line, also called dxStart";
CM_ SG_ 546 IFC_Roadedge02_DxEnd "Longitudinal range of the line, also called dxEnd";
CM_ SG_ 546 IFC_Roadedge02_HeadingAngle "Heading angle, difference in yaw angle between vehicle heading and Line";
CM_ SG_ 265 IFCTrqOvlCmdProtnValue "Lane Keeping Assist Torque overlay Command Protection Value";
CM_ SG_ 265 IFCTrqOvlCmdReqValue "Lane Keeping Assist Torque overlay Command Request ValuePositive means steers left, negative means steers right";

BA_DEF_ BO_ "DiagRequest" ENUM  "No","Yes";
BA_DEF_ BO_ "DiagResponse" ENUM  "No","Yes";
BA_DEF_ BO_ "DiagState" ENUM  "No","Yes";
BA_DEF_ BO_ "GenMsgCycleTime" INT 0 65535;
BA_DEF_ BO_ "GenMsgCycleTimeFast" INT 0 65535;
BA_DEF_ BO_ "GenMsgILSupport" ENUM  "No","Yes";
BA_DEF_ BO_ "GenMsgNrOfRepetition" INT 0 65535;
BA_DEF_ BO_ "GenMsgSendType" ENUM  "Cyclic","CyclicAndSpontanX","Event";
BA_DEF_ BO_ "NmAsrMessage" ENUM  "No","Yes";
BA_DEF_ BO_ "OriginFrame" STRING;
BA_DEF_ BO_ "SCP_AuthInfoTxLength" INT 0 512;
BA_DEF_ BO_ "SCP_DataId" INT 0 65535;
BA_DEF_ BO_ "SCP_FreshnessValueLength" INT 0 512;
BA_DEF_ BO_ "SCP_FreshnessValueTxLength" INT 0 512;
BA_DEF_ BO_ "SC_Message" ENUM  "NO","YES";
BA_DEF_ BO_ "VFrameFormat" ENUM  "StandardCAN","ExtendedCAN","reserved","reserved","reserved","reserved","reserved","reserved","reserved","reserved","reserved","reserved","reserved","reserved","StandardCAN_FD","ExtendedCAN_FD";
BA_DEF_ SG_ "GenSigCycleTime" INT 0 65535;
BA_DEF_ SG_ "GenSigSendType" ENUM  "Cyclic","OnWrite","OnWriteWithRepetition","OnChange","OnChangeWithRepetition","NotUsed","NotUsed","NoSigSendType";
BA_DEF_ SG_ "GenSigStartValue" FLOAT 0 100000000000;
BA_DEF_ SG_ "Match" STRING;
BA_DEF_ SG_ "Origin" STRING;
BA_DEF_ SG_ "SystemSignalLongSymbol" STRING;
BA_DEF_DEF_ "DiagRequest" "No";
BA_DEF_DEF_ "DiagResponse" "No";
BA_DEF_DEF_ "DiagState" "No";
BA_DEF_DEF_ "GenMsgCycleTime" 0;
BA_DEF_DEF_ "GenMsgCycleTimeFast" 0;
BA_DEF_DEF_ "GenMsgILSupport" "No";
BA_DEF_DEF_ "GenMsgNrOfRepetition" 0;
BA_DEF_DEF_ "GenMsgSendType" "Cyclic";
BA_DEF_DEF_ "GenSigCycleTime" 0;
BA_DEF_DEF_ "GenSigSendType" "Cyclic";
BA_DEF_DEF_ "GenSigStartValue" 0;
BA_DEF_DEF_ "Match" "";
BA_DEF_DEF_ "NmAsrMessage" "No";
BA_DEF_DEF_ "Origin" "";
BA_DEF_DEF_ "OriginFrame" "";
BA_DEF_DEF_ "SCP_AuthInfoTxLength" 0;
BA_DEF_DEF_ "SCP_DataId" 0;
BA_DEF_DEF_ "SCP_FreshnessValueLength" 0;
BA_DEF_DEF_ "SCP_FreshnessValueTxLength" 0;
BA_DEF_DEF_ "SC_Message" "NO";
BA_DEF_DEF_ "SystemSignalLongSymbol" "";
BA_DEF_DEF_ "VFrameFormat" "";
BA_ "GenMsgCycleTimeFast" BO_ 728 20;
BA_ "GenMsgILSupport" BO_ 728 1;
BA_ "GenMsgNrOfRepetition" BO_ 728 5;
BA_ "GenMsgSendType" BO_ 728 2;
BA_ "OriginFrame" BO_ 728 "fuel,ev";
BA_ "VFrameFormat" BO_ 728 14;
BA_ "GenMsgCycleTimeFast" BO_ 825 20;
BA_ "GenMsgILSupport" BO_ 825 1;
BA_ "GenMsgNrOfRepetition" BO_ 825 5;
BA_ "GenMsgSendType" BO_ 825 2;
BA_ "OriginFrame" BO_ 825 "fuel,ev";
BA_ "VFrameFormat" BO_ 825 14;
BA_ "GenMsgCycleTime" BO_ 694 100;
BA_ "GenMsgILSupport" BO_ 694 1;
BA_ "OriginFrame" BO_ 694 "fuel,ev";
BA_ "VFrameFormat" BO_ 694 14;
BA_ "GenMsgCycleTimeFast" BO_ 875 20;
BA_ "GenMsgILSupport" BO_ 875 1;
BA_ "GenMsgNrOfRepetition" BO_ 875 5;
BA_ "GenMsgSendType" BO_ 875 2;
BA_ "OriginFrame" BO_ 875 "fuel,ev";
BA_ "VFrameFormat" BO_ 875 14;
BA_ "GenMsgCycleTimeFast" BO_ 489 20;
BA_ "GenMsgILSupport" BO_ 489 1;
BA_ "GenMsgNrOfRepetition" BO_ 489 5;
BA_ "GenMsgSendType" BO_ 489 2;
BA_ "OriginFrame" BO_ 489 "fuel,ev";
BA_ "VFrameFormat" BO_ 489 14;
BA_ "GenMsgCycleTime" BO_ 780 200;
BA_ "GenMsgILSupport" BO_ 780 1;
BA_ "OriginFrame" BO_ 780 "fuel,ev";
BA_ "VFrameFormat" BO_ 780 14;
BA_ "GenMsgCycleTime" BO_ 623 50;
BA_ "GenMsgILSupport" BO_ 623 1;
BA_ "OriginFrame" BO_ 623 "fuel,ev";
BA_ "VFrameFormat" BO_ 623 14;
BA_ "GenMsgCycleTimeFast" BO_ 493 20;
BA_ "GenMsgILSupport" BO_ 493 1;
BA_ "GenMsgNrOfRepetition" BO_ 493 5;
BA_ "GenMsgSendType" BO_ 493 2;
BA_ "OriginFrame" BO_ 493 "fuel,ev";
BA_ "VFrameFormat" BO_ 493 14;
BA_ "GenMsgCycleTime" BO_ 880 1000;
BA_ "GenMsgILSupport" BO_ 880 1;
BA_ "OriginFrame" BO_ 880 "fuel,ev";
BA_ "VFrameFormat" BO_ 880 14;
BA_ "GenMsgCycleTimeFast" BO_ 485 20;
BA_ "GenMsgILSupport" BO_ 485 1;
BA_ "GenMsgNrOfRepetition" BO_ 485 5;
BA_ "GenMsgSendType" BO_ 485 2;
BA_ "OriginFrame" BO_ 485 "fuel,ev";
BA_ "VFrameFormat" BO_ 485 14;
BA_ "GenMsgCycleTimeFast" BO_ 487 20;
BA_ "GenMsgILSupport" BO_ 487 1;
BA_ "GenMsgNrOfRepetition" BO_ 487 5;
BA_ "GenMsgSendType" BO_ 487 2;
BA_ "OriginFrame" BO_ 487 "fuel,ev";
BA_ "VFrameFormat" BO_ 487 14;
BA_ "GenMsgCycleTimeFast" BO_ 491 20;
BA_ "GenMsgILSupport" BO_ 491 1;
BA_ "GenMsgNrOfRepetition" BO_ 491 5;
BA_ "GenMsgSendType" BO_ 491 2;
BA_ "OriginFrame" BO_ 491 "fuel,ev";
BA_ "VFrameFormat" BO_ 491 14;
BA_ "GenMsgCycleTimeFast" BO_ 877 20;
BA_ "GenMsgILSupport" BO_ 877 1;
BA_ "GenMsgNrOfRepetition" BO_ 877 5;
BA_ "GenMsgSendType" BO_ 877 2;
BA_ "OriginFrame" BO_ 877 "fuel,ev";
BA_ "VFrameFormat" BO_ 877 14;
BA_ "GenMsgCycleTime" BO_ 548 50;
BA_ "GenMsgILSupport" BO_ 548 1;
BA_ "OriginFrame" BO_ 548 "fuel,ev";
BA_ "VFrameFormat" BO_ 548 14;
BA_ "GenMsgCycleTimeFast" BO_ 507 20;
BA_ "GenMsgILSupport" BO_ 507 1;
BA_ "GenMsgNrOfRepetition" BO_ 507 5;
BA_ "GenMsgSendType" BO_ 507 2;
BA_ "OriginFrame" BO_ 507 "fuel,ev";
BA_ "VFrameFormat" BO_ 507 14;
BA_ "GenMsgCycleTimeFast" BO_ 505 20;
BA_ "GenMsgILSupport" BO_ 505 1;
BA_ "GenMsgNrOfRepetition" BO_ 505 5;
BA_ "GenMsgSendType" BO_ 505 2;
BA_ "OriginFrame" BO_ 505 "fuel,ev";
BA_ "VFrameFormat" BO_ 505 14;
BA_ "GenMsgCycleTimeFast" BO_ 509 20;
BA_ "GenMsgILSupport" BO_ 509 1;
BA_ "GenMsgNrOfRepetition" BO_ 509 5;
BA_ "GenMsgSendType" BO_ 509 2;
BA_ "OriginFrame" BO_ 509 "fuel,ev";
BA_ "VFrameFormat" BO_ 509 14;
BA_ "GenMsgCycleTimeFast" BO_ 476 20;
BA_ "GenMsgILSupport" BO_ 476 1;
BA_ "GenMsgNrOfRepetition" BO_ 476 5;
BA_ "GenMsgSendType" BO_ 476 2;
BA_ "OriginFrame" BO_ 476 "fuel,ev";
BA_ "VFrameFormat" BO_ 476 14;
BA_ "GenMsgCycleTimeFast" BO_ 477 20;
BA_ "GenMsgILSupport" BO_ 477 1;
BA_ "GenMsgNrOfRepetition" BO_ 477 5;
BA_ "GenMsgSendType" BO_ 477 2;
BA_ "OriginFrame" BO_ 477 "fuel,ev";
BA_ "VFrameFormat" BO_ 477 14;
BA_ "GenMsgCycleTimeFast" BO_ 74 20;
BA_ "GenMsgILSupport" BO_ 74 1;
BA_ "GenMsgNrOfRepetition" BO_ 74 5;
BA_ "GenMsgSendType" BO_ 74 2;
BA_ "OriginFrame" BO_ 74 "fuel,ev";
BA_ "VFrameFormat" BO_ 74 14;
BA_ "GenMsgCycleTimeFast" BO_ 465 20;
BA_ "GenMsgILSupport" BO_ 465 1;
BA_ "GenMsgNrOfRepetition" BO_ 465 5;
BA_ "GenMsgSendType" BO_ 465 2;
BA_ "OriginFrame" BO_ 465 "fuel,ev";
BA_ "VFrameFormat" BO_ 465 14;
BA_ "GenMsgCycleTime" BO_ 288 20;
BA_ "GenMsgILSupport" BO_ 288 1;
BA_ "OriginFrame" BO_ 288 "fuel,ev";
BA_ "VFrameFormat" BO_ 288 14;
BA_ "GenMsgCycleTime" BO_ 573 50;
BA_ "GenMsgILSupport" BO_ 573 1;
BA_ "OriginFrame" BO_ 573 "fuel,ev";
BA_ "SCP_AuthInfoTxLength" BO_ 573 48;
BA_ "SCP_DataId" BO_ 573 573;
BA_ "SCP_FreshnessValueLength" BO_ 573 64;
BA_ "SCP_FreshnessValueTxLength" BO_ 573 16;
BA_ "SC_Message" BO_ 573 1;
BA_ "VFrameFormat" BO_ 573 14;
BA_ "GenMsgCycleTime" BO_ 719 100;
BA_ "GenMsgILSupport" BO_ 719 1;
BA_ "OriginFrame" BO_ 719 "fuel,ev";
BA_ "VFrameFormat" BO_ 719 14;
BA_ "GenMsgCycleTime" BO_ 415 50;
BA_ "GenMsgILSupport" BO_ 415 1;
BA_ "OriginFrame" BO_ 415 "fuel,ev";
BA_ "VFrameFormat" BO_ 415 14;
BA_ "GenMsgCycleTime" BO_ 546 50;
BA_ "GenMsgILSupport" BO_ 546 1;
BA_ "OriginFrame" BO_ 546 "fuel,ev";
BA_ "VFrameFormat" BO_ 546 14;
BA_ "GenMsgCycleTime" BO_ 265 20;
BA_ "GenMsgILSupport" BO_ 265 1;
BA_ "OriginFrame" BO_ 265 "fuel,ev";
BA_ "VFrameFormat" BO_ 265 14;
BA_ "GenSigSendType" SG_ 728 ADAS_Stub_MsgTyp 2;
BA_ "Match" SG_ 728 ADAS_Stub_MsgTyp "ADAS_Stub_MsgTyp";
BA_ "Origin" SG_ 728 ADAS_Stub_MsgTyp "fuel,ev";
BA_ "GenSigSendType" SG_ 728 ADAS_Stub_Offset 2;
BA_ "Match" SG_ 728 ADAS_Stub_Offset "ADAS_Stub_Offset";
BA_ "Origin" SG_ 728 ADAS_Stub_Offset "fuel,ev";
BA_ "GenSigSendType" SG_ 728 ADAS_Stub_CycCnt 2;
BA_ "Match" SG_ 728 ADAS_Stub_CycCnt "ADAS_Stub_CycCnt";
BA_ "Origin" SG_ 728 ADAS_Stub_CycCnt "fuel,ev";
BA_ "GenSigSendType" SG_ 728 ADAS_Stub_PathIdx 2;
BA_ "Match" SG_ 728 ADAS_Stub_PathIdx "ADAS_Stub_PathIdx";
BA_ "Origin" SG_ 728 ADAS_Stub_PathIdx "fuel,ev";
BA_ "GenSigSendType" SG_ 728 ADAS_Stub_StubPathIdx 2;
BA_ "Match" SG_ 728 ADAS_Stub_StubPathIdx "ADAS_Stub_StubPathIdx";
BA_ "Origin" SG_ 728 ADAS_Stub_StubPathIdx "fuel,ev";
BA_ "GenSigSendType" SG_ 728 ADAS_Stub_Retr 2;
BA_ "Match" SG_ 728 ADAS_Stub_Retr "ADAS_Stub_Retr";
BA_ "Origin" SG_ 728 ADAS_Stub_Retr "fuel,ev";
BA_ "GenSigSendType" SG_ 728 ADAS_Stub_Update 2;
BA_ "Match" SG_ 728 ADAS_Stub_Update "ADAS_Stub_Update";
BA_ "Origin" SG_ 728 ADAS_Stub_Update "fuel,ev";
BA_ "GenSigSendType" SG_ 728 ADAS_Stub_RelProbb 2;
BA_ "Match" SG_ 728 ADAS_Stub_RelProbb "ADAS_Stub_RelProbb";
BA_ "Origin" SG_ 728 ADAS_Stub_RelProbb "fuel,ev";
BA_ "GenSigSendType" SG_ 728 ADAS_Stub_FuncRoadClass 2;
BA_ "Match" SG_ 728 ADAS_Stub_FuncRoadClass "ADAS_Stub_FuncRoadClass";
BA_ "Origin" SG_ 728 ADAS_Stub_FuncRoadClass "fuel,ev";
BA_ "GenSigSendType" SG_ 728 ADAS_Stub_PartOfCalcRoute 2;
BA_ "Match" SG_ 728 ADAS_Stub_PartOfCalcRoute "ADAS_Stub_PartOfCalcRoute";
BA_ "Origin" SG_ 728 ADAS_Stub_PartOfCalcRoute "fuel,ev";
BA_ "GenSigSendType" SG_ 728 ADAS_Stub_CmplxInsct 2;
BA_ "Match" SG_ 728 ADAS_Stub_CmplxInsct "ADAS_Stub_CmplxInsct";
BA_ "Origin" SG_ 728 ADAS_Stub_CmplxInsct "fuel,ev";
BA_ "GenSigSendType" SG_ 728 ADAS_Stub_FormOfWay 2;
BA_ "Match" SG_ 728 ADAS_Stub_FormOfWay "ADAS_Stub_FormOfWay";
BA_ "Origin" SG_ 728 ADAS_Stub_FormOfWay "fuel,ev";
BA_ "GenSigSendType" SG_ 728 ADAS_Stub_TurnAngl 2;
BA_ "Match" SG_ 728 ADAS_Stub_TurnAngl "ADAS_Stub_TurnAngl";
BA_ "Origin" SG_ 728 ADAS_Stub_TurnAngl "fuel,ev";
BA_ "GenSigSendType" SG_ 728 ADAS_Stub_LastStub 2;
BA_ "Match" SG_ 728 ADAS_Stub_LastStub "ADAS_Stub_LastStub";
BA_ "Origin" SG_ 728 ADAS_Stub_LastStub "fuel,ev";
BA_ "GenSigSendType" SG_ 728 ADAS_Stub_RtOfWay 2;
BA_ "Match" SG_ 728 ADAS_Stub_RtOfWay "ADAS_Stub_RtOfWay";
BA_ "Origin" SG_ 728 ADAS_Stub_RtOfWay "fuel,ev";
BA_ "GenSigSendType" SG_ 728 ADAS_Stub_NumOfLaneOppDir 2;
BA_ "Match" SG_ 728 ADAS_Stub_NumOfLaneOppDir "ADAS_Stub_NumOfLaneOppDir";
BA_ "Origin" SG_ 728 ADAS_Stub_NumOfLaneOppDir "fuel,ev";
BA_ "GenSigSendType" SG_ 728 ADAS_Stub_NumOfLaneDrvDir 2;
BA_ "Match" SG_ 728 ADAS_Stub_NumOfLaneDrvDir "ADAS_Stub_NumOfLaneDrvDir";
BA_ "Origin" SG_ 728 ADAS_Stub_NumOfLaneDrvDir "fuel,ev";
BA_ "GenSigSendType" SG_ 825 HUT_RemtEngCtrl 2;
BA_ "Match" SG_ 825 HUT_RemtEngCtrl "HUT_RemtEngCtrl";
BA_ "Origin" SG_ 825 HUT_RemtEngCtrl "fuel,ev";
BA_ "GenSigSendType" SG_ 825 ACDrvSetTempReq_ETC_VR 2;
BA_ "Match" SG_ 825 ACDrvSetTempReq_ETC_VR "ACDrvSetTempReq_ETC_VR";
BA_ "Origin" SG_ 825 ACDrvSetTempReq_ETC_VR "fuel,ev";
BA_ "GenSigSendType" SG_ 825 ACDrvSetTempSteplsReq_ETC_TC 2;
BA_ "Match" SG_ 825 ACDrvSetTempSteplsReq_ETC_TC "ACDrvSetTempSteplsReq_ETC_TC";
BA_ "Origin" SG_ 825 ACDrvSetTempSteplsReq_ETC_TC "fuel,ev";
BA_ "GenSigSendType" SG_ 825 HUT_ChrgnMode 2;
BA_ "Match" SG_ 825 HUT_ChrgnMode "HUT_ChrgnMode";
BA_ "Origin" SG_ 825 HUT_ChrgnMode "ev";
BA_ "GenSigSendType" SG_ 825 HUT_BattKeepTemp 2;
BA_ "Match" SG_ 825 HUT_BattKeepTemp "HUT_BattKeepTemp";
BA_ "Origin" SG_ 825 HUT_BattKeepTemp "ev";
BA_ "GenSigSendType" SG_ 825 HUT_IntelEngIdlChrgnSet 2;
BA_ "Match" SG_ 825 HUT_IntelEngIdlChrgnSet "HUT_IntelEngIdlChrgnSet";
BA_ "Origin" SG_ 825 HUT_IntelEngIdlChrgnSet "ev";
BA_ "GenSigSendType" SG_ 825 HUT_IntelBattTempMagSet 2;
BA_ "Match" SG_ 825 HUT_IntelBattTempMagSet "HUT_IntelBattTempMagSet";
BA_ "Origin" SG_ 825 HUT_IntelBattTempMagSet "ev";
BA_ "GenSigSendType" SG_ 825 HUT_BattSOCLim 2;
BA_ "GenSigStartValue" SG_ 825 HUT_BattSOCLim 6;
BA_ "Match" SG_ 825 HUT_BattSOCLim "HUT_BattSOCLim";
BA_ "Origin" SG_ 825 HUT_BattSOCLim "ev";
BA_ "GenSigCycleTime" SG_ 694 PassSeatAdjmtSwt_HUT 100;
BA_ "Match" SG_ 694 PassSeatAdjmtSwt_HUT "PassSeatAdjmtSwt_HUT";
BA_ "Origin" SG_ 694 PassSeatAdjmtSwt_HUT "fuel,ev";
BA_ "GenSigCycleTime" SG_ 694 SeatFlankAdjmtSwt_HUT 100;
BA_ "Match" SG_ 694 SeatFlankAdjmtSwt_HUT "SeatFlankAdjmtSwt_HUT";
BA_ "Origin" SG_ 694 SeatFlankAdjmtSwt_HUT "fuel,ev";
BA_ "GenSigCycleTime" SG_ 694 AVM_dispsts 100;
BA_ "Match" SG_ 694 AVM_dispsts "AVM_dispsts";
BA_ "Origin" SG_ 694 AVM_dispsts "fuel,ev";
BA_ "GenSigSendType" SG_ 875 AMP_HFMVolSet 2;
BA_ "GenSigStartValue" SG_ 875 AMP_HFMVolSet 10;
BA_ "Match" SG_ 875 AMP_HFMVolSet "AMP_HFMVolSet";
BA_ "Origin" SG_ 875 AMP_HFMVolSet "fuel,ev";
BA_ "GenSigSendType" SG_ 875 AMP_TTSVolSet_VR 2;
BA_ "GenSigStartValue" SG_ 875 AMP_TTSVolSet_VR 10;
BA_ "Match" SG_ 875 AMP_TTSVolSet_VR "AMP_TTSVolSet_VR";
BA_ "Origin" SG_ 875 AMP_TTSVolSet_VR "fuel,ev";
BA_ "GenSigSendType" SG_ 875 AMP_NaviVolSet 2;
BA_ "GenSigStartValue" SG_ 875 AMP_NaviVolSet 10;
BA_ "Match" SG_ 875 AMP_NaviVolSet "AMP_NaviVolSet";
BA_ "Origin" SG_ 875 AMP_NaviVolSet "fuel,ev";
BA_ "GenSigSendType" SG_ 875 AMP_MainVolSet 2;
BA_ "GenSigStartValue" SG_ 875 AMP_MainVolSet 10;
BA_ "Match" SG_ 875 AMP_MainVolSet "AMP_MainVolSet";
BA_ "Origin" SG_ 875 AMP_MainVolSet "fuel,ev";
BA_ "GenSigSendType" SG_ 875 AMP_GetSWInfoReq 2;
BA_ "Match" SG_ 875 AMP_GetSWInfoReq "AMP_GetSWInfoReq";
BA_ "Origin" SG_ 875 AMP_GetSWInfoReq "fuel,ev";
BA_ "GenSigSendType" SG_ 875 AMP_GetHWInfoReq 2;
BA_ "Match" SG_ 875 AMP_GetHWInfoReq "AMP_GetHWInfoReq";
BA_ "Origin" SG_ 875 AMP_GetHWInfoReq "fuel,ev";
BA_ "GenSigSendType" SG_ 875 AMP_GetTempInfoReq 2;
BA_ "Match" SG_ 875 AMP_GetTempInfoReq "AMP_GetTempInfoReq";
BA_ "Origin" SG_ 875 AMP_GetTempInfoReq "fuel,ev";
BA_ "GenSigSendType" SG_ 875 AMP_GetIntVoltInfoReq 2;
BA_ "Match" SG_ 875 AMP_GetIntVoltInfoReq "AMP_GetIntVoltInfoReq";
BA_ "Origin" SG_ 875 AMP_GetIntVoltInfoReq "fuel,ev";
BA_ "GenSigSendType" SG_ 875 AMP_GetDTCInfoReq 2;
BA_ "Match" SG_ 875 AMP_GetDTCInfoReq "AMP_GetDTCInfoReq";
BA_ "Origin" SG_ 875 AMP_GetDTCInfoReq "fuel,ev";
BA_ "GenSigSendType" SG_ 875 IESS_MdlSwtReq 2;
BA_ "Match" SG_ 875 IESS_MdlSwtReq "IESS_MdlSwtReq";
BA_ "Origin" SG_ 875 IESS_MdlSwtReq "fuel,ev";
BA_ "GenSigSendType" SG_ 875 IESS_MdlInfoReq 2;
BA_ "Match" SG_ 875 IESS_MdlInfoReq "IESS_MdlInfoReq";
BA_ "Origin" SG_ 875 IESS_MdlInfoReq "fuel,ev";
BA_ "GenSigSendType" SG_ 875 AMP_BestListegPosnReq 2;
BA_ "Match" SG_ 875 AMP_BestListegPosnReq "AMP_BestListegPosnReq";
BA_ "Origin" SG_ 875 AMP_BestListegPosnReq "fuel,ev";
BA_ "GenSigSendType" SG_ 875 AMP_Clari_FiReq 2;
BA_ "GenSigStartValue" SG_ 875 AMP_Clari_FiReq 1;
BA_ "Match" SG_ 875 AMP_Clari_FiReq "AMP_Clari_FiReq";
BA_ "Origin" SG_ 875 AMP_Clari_FiReq "fuel,ev";
BA_ "GenSigSendType" SG_ 489 HUD_HeightLvlSwt 2;
BA_ "Match" SG_ 489 HUD_HeightLvlSwt "HUD_HeightLvlSwt";
BA_ "Origin" SG_ 489 HUD_HeightLvlSwt "fuel,ev";
BA_ "GenSigSendType" SG_ 489 HUD_BrightnessLvlSwt 2;
BA_ "Match" SG_ 489 HUD_BrightnessLvlSwt "HUD_BrightnessLvlSwt";
BA_ "Origin" SG_ 489 HUD_BrightnessLvlSwt "fuel,ev";
BA_ "GenSigSendType" SG_ 489 HUD_SwtReq 2;
BA_ "Match" SG_ 489 HUD_SwtReq "HUD_SwtReq";
BA_ "Origin" SG_ 489 HUD_SwtReq "fuel,ev";
BA_ "GenSigSendType" SG_ 489 BackReq_AVM 2;
BA_ "Match" SG_ 489 BackReq_AVM "BackReq_AVM";
BA_ "Origin" SG_ 489 BackReq_AVM "fuel,ev";
BA_ "GenSigSendType" SG_ 489 PPMIHWSwtSet 2;
BA_ "GenSigStartValue" SG_ 489 PPMIHWSwtSet 2;
BA_ "Match" SG_ 489 PPMIHWSwtSet "PPMIHWSwtSet";
BA_ "Origin" SG_ 489 PPMIHWSwtSet "fuel";
BA_ "GenSigSendType" SG_ 489 PPMIBSRSwtSet 2;
BA_ "GenSigStartValue" SG_ 489 PPMIBSRSwtSet 2;
BA_ "Match" SG_ 489 PPMIBSRSwtSet "PPMIBSRSwtSet";
BA_ "Origin" SG_ 489 PPMIBSRSwtSet "fuel";
BA_ "GenSigSendType" SG_ 489 PPMIHW_SwtSet 2;
BA_ "GenSigStartValue" SG_ 489 PPMIHW_SwtSet 2;
BA_ "Match" SG_ 489 PPMIHW_SwtSet "PPMIHW_SwtSet";
BA_ "Origin" SG_ 489 PPMIHW_SwtSet "ev";
BA_ "GenSigSendType" SG_ 489 PPMIBSR_SwtSet 2;
BA_ "GenSigStartValue" SG_ 489 PPMIBSR_SwtSet 2;
BA_ "Match" SG_ 489 PPMIBSR_SwtSet "PPMIBSR_SwtSet";
BA_ "Origin" SG_ 489 PPMIBSR_SwtSet "ev";
BA_ "GenSigCycleTime" SG_ 780 HUT_PhoneNextRoad 200;
BA_ "Match" SG_ 780 HUT_PhoneNextRoad "HUT_PhoneNextRoad";
BA_ "Origin" SG_ 780 HUT_PhoneNextRoad "fuel,ev";
BA_ "GenSigCycleTime" SG_ 623 CheckSum_HUT32 50;
BA_ "Match" SG_ 623 CheckSum_HUT32 "CheckSum_HUT32";
BA_ "Origin" SG_ 623 CheckSum_HUT32 "fuel,ev";
BA_ "GenSigCycleTime" SG_ 623 ScrnOpSts 50;
BA_ "Match" SG_ 623 ScrnOpSts "ScrnOpSts";
BA_ "Origin" SG_ 623 ScrnOpSts "fuel,ev";
BA_ "GenSigCycleTime" SG_ 623 XLvl 50;
BA_ "GenSigStartValue" SG_ 623 XLvl 2047;
BA_ "Match" SG_ 623 XLvl "XLvl";
BA_ "Origin" SG_ 623 XLvl "fuel,ev";
BA_ "GenSigCycleTime" SG_ 623 YLvl 50;
BA_ "GenSigStartValue" SG_ 623 YLvl 2047;
BA_ "Match" SG_ 623 YLvl "YLvl";
BA_ "Origin" SG_ 623 YLvl "fuel,ev";
BA_ "GenSigCycleTime" SG_ 623 DetVideoLost 50;
BA_ "Match" SG_ 623 DetVideoLost "DetVideoLost";
BA_ "Origin" SG_ 623 DetVideoLost "fuel,ev";
BA_ "GenSigCycleTime" SG_ 623 PrkgCtrlModReqValid 50;
BA_ "Match" SG_ 623 PrkgCtrlModReqValid "PrkgCtrlModReqValid";
BA_ "Origin" SG_ 623 PrkgCtrlModReqValid "fuel,ev";
BA_ "GenSigCycleTime" SG_ 623 PrkgCtrlModReq 50;
BA_ "Match" SG_ 623 PrkgCtrlModReq "PrkgCtrlModReq";
BA_ "Origin" SG_ 623 PrkgCtrlModReq "fuel,ev";
BA_ "GenSigCycleTime" SG_ 623 ContnPrkgReqValid 50;
BA_ "Match" SG_ 623 ContnPrkgReqValid "ContnPrkgReqValid";
BA_ "Origin" SG_ 623 ContnPrkgReqValid "fuel,ev";
BA_ "GenSigCycleTime" SG_ 623 ContnPrkgReq 50;
BA_ "Match" SG_ 623 ContnPrkgReq "ContnPrkgReq";
BA_ "Origin" SG_ 623 ContnPrkgReq "fuel,ev";
BA_ "GenSigCycleTime" SG_ 623 PrkStraightSwtReq_HUT 50;
BA_ "Match" SG_ 623 PrkStraightSwtReq_HUT "PrkStraightSwtReq_HUT";
BA_ "Origin" SG_ 623 PrkStraightSwtReq_HUT "fuel,ev";
BA_ "GenSigCycleTime" SG_ 623 PrkStraightSuspendOrFinishReq_HU 50;
BA_ "Match" SG_ 623 PrkStraightSuspendOrFinishReq_HU "PrkStraightSuspendOrFinishReq_HUT";
BA_ "Origin" SG_ 623 PrkStraightSuspendOrFinishReq_HU "fuel,ev";
BA_ "SystemSignalLongSymbol" SG_ 623 PrkStraightSuspendOrFinishReq_HU "PrkStraightSuspendOrFinishReq_HUT";
BA_ "GenSigCycleTime" SG_ 623 PrkStraightModSel_HUT 50;
BA_ "Match" SG_ 623 PrkStraightModSel_HUT "PrkStraightModSel_HUT";
BA_ "Origin" SG_ 623 PrkStraightModSel_HUT "fuel,ev";
BA_ "GenSigCycleTime" SG_ 623 PrkStraightSts_HUT 50;
BA_ "Match" SG_ 623 PrkStraightSts_HUT "PrkStraightSts_HUT";
BA_ "Origin" SG_ 623 PrkStraightSts_HUT "fuel,ev";
BA_ "GenSigCycleTime" SG_ 623 PrkStraightStrtReq_HUT 50;
BA_ "Match" SG_ 623 PrkStraightStrtReq_HUT "PrkStraightStrtReq_HUT";
BA_ "Origin" SG_ 623 PrkStraightStrtReq_HUT "fuel,ev";
BA_ "GenSigCycleTime" SG_ 623 PrkStraightVehStrtReq_HUT_Valid 50;
BA_ "Match" SG_ 623 PrkStraightVehStrtReq_HUT_Valid "PrkStraightVehStrtReq_HUT_Valid";
BA_ "Origin" SG_ 623 PrkStraightVehStrtReq_HUT_Valid "fuel,ev";
BA_ "GenSigCycleTime" SG_ 623 PrkStraightContinueReq_HUT 50;
BA_ "Match" SG_ 623 PrkStraightContinueReq_HUT "PrkStraightContinueReq_HUT";
BA_ "Origin" SG_ 623 PrkStraightContinueReq_HUT "fuel,ev";
BA_ "GenSigCycleTime" SG_ 623 P2P_PrkgDirSwtReq 50;
BA_ "Match" SG_ 623 P2P_PrkgDirSwtReq "P2P_PrkgDirSwtReq";
BA_ "Origin" SG_ 623 P2P_PrkgDirSwtReq "fuel,ev";
BA_ "GenSigCycleTime" SG_ 623 RainMode_Swt_Req 50;
BA_ "Match" SG_ 623 RainMode_Swt_Req "RainMode_Swt_Req";
BA_ "Origin" SG_ 623 RainMode_Swt_Req "fuel,ev";
BA_ "GenSigCycleTime" SG_ 623 LCMode_Swt_Req 50;
BA_ "Match" SG_ 623 LCMode_Swt_Req "LCMode_Swt_Req";
BA_ "Origin" SG_ 623 LCMode_Swt_Req "fuel,ev";
BA_ "GenSigCycleTime" SG_ 623 NavDecSwtReq 50;
BA_ "Match" SG_ 623 NavDecSwtReq "NavDecSwtReq";
BA_ "Origin" SG_ 623 NavDecSwtReq "fuel,ev";
BA_ "GenSigCycleTime" SG_ 623 RollingCounter_HUT32 50;
BA_ "Match" SG_ 623 RollingCounter_HUT32 "RollingCounter_HUT32";
BA_ "Origin" SG_ 623 RollingCounter_HUT32 "fuel,ev";
BA_ "GenSigSendType" SG_ 493 FlaoutUnlockSet 2;
BA_ "GenSigStartValue" SG_ 493 FlaoutUnlockSet 2;
BA_ "Match" SG_ 493 FlaoutUnlockSet "FlaoutUnlockSet";
BA_ "Origin" SG_ 493 FlaoutUnlockSet "fuel,ev";
BA_ "GenSigSendType" SG_ 493 PrkInDirChoice 2;
BA_ "Match" SG_ 493 PrkInDirChoice "PrkInDirChoice";
BA_ "Origin" SG_ 493 PrkInDirChoice "fuel,ev";
BA_ "GenSigSendType" SG_ 493 ADASDispSwt 2;
BA_ "Match" SG_ 493 ADASDispSwt "ADASDispSwt";
BA_ "Origin" SG_ 493 ADASDispSwt "fuel,ev";
BA_ "GenSigSendType" SG_ 493 NaviDispSwt 2;
BA_ "Match" SG_ 493 NaviDispSwt "NaviDispSwt";
BA_ "Origin" SG_ 493 NaviDispSwt "fuel,ev";
BA_ "GenSigSendType" SG_ 493 NaviDispSwt_VR 2;
BA_ "Match" SG_ 493 NaviDispSwt_VR "NaviDispSwt_VR";
BA_ "Origin" SG_ 493 NaviDispSwt_VR "fuel,ev";
BA_ "GenSigSendType" SG_ 493 ADASDispSwt_VR 2;
BA_ "Match" SG_ 493 ADASDispSwt_VR "ADASDispSwt_VR";
BA_ "Origin" SG_ 493 ADASDispSwt_VR "fuel,ev";
BA_ "GenSigSendType" SG_ 493 ApproachLampSet 2;
BA_ "GenSigStartValue" SG_ 493 ApproachLampSet 2;
BA_ "Match" SG_ 493 ApproachLampSet "ApproachLampSet";
BA_ "Origin" SG_ 493 ApproachLampSet "fuel,ev";
BA_ "GenSigSendType" SG_ 493 SuperLockSet 2;
BA_ "GenSigStartValue" SG_ 493 SuperLockSet 2;
BA_ "Match" SG_ 493 SuperLockSet "SuperLockSet";
BA_ "Origin" SG_ 493 SuperLockSet "fuel,ev";
BA_ "GenSigSendType" SG_ 493 ALCMDynModSet 2;
BA_ "Match" SG_ 493 ALCMDynModSet "ALCMDynModSet";
BA_ "Origin" SG_ 493 ALCMDynModSet "fuel,ev";
BA_ "GenSigSendType" SG_ 493 RLWinSwtReq_VR 2;
BA_ "Match" SG_ 493 RLWinSwtReq_VR "RLWinSwtReq_VR";
BA_ "Origin" SG_ 493 RLWinSwtReq_VR "fuel,ev";
BA_ "GenSigSendType" SG_ 493 RRWinSwtReq_VR 2;
BA_ "Match" SG_ 493 RRWinSwtReq_VR "RRWinSwtReq_VR";
BA_ "Origin" SG_ 493 RRWinSwtReq_VR "fuel,ev";
BA_ "GenSigSendType" SG_ 493 DrvWinSwtReq_VR 2;
BA_ "Match" SG_ 493 DrvWinSwtReq_VR "DrvWinSwtReq_VR";
BA_ "Origin" SG_ 493 DrvWinSwtReq_VR "fuel,ev";
BA_ "GenSigSendType" SG_ 493 PassWinSwtReq_VR 2;
BA_ "Match" SG_ 493 PassWinSwtReq_VR "PassWinSwtReq_VR";
BA_ "Origin" SG_ 493 PassWinSwtReq_VR "fuel,ev";
BA_ "GenSigSendType" SG_ 493 ChairMemPosnSetSwt 2;
BA_ "Match" SG_ 493 ChairMemPosnSetSwt "ChairMemPosnSetSwt";
BA_ "Origin" SG_ 493 ChairMemPosnSetSwt "fuel,ev";
BA_ "GenSigSendType" SG_ 493 PathLrngFinshCmd 2;
BA_ "Match" SG_ 493 PathLrngFinshCmd "PathLrngFinshCmd";
BA_ "Origin" SG_ 493 PathLrngFinshCmd "fuel,ev";
BA_ "GenSigSendType" SG_ 493 PathLrngStartCmd 2;
BA_ "Match" SG_ 493 PathLrngStartCmd "PathLrngStartCmd";
BA_ "Origin" SG_ 493 PathLrngStartCmd "fuel,ev";
BA_ "GenSigSendType" SG_ 493 SelPrkOutDirReq 2;
BA_ "Match" SG_ 493 SelPrkOutDirReq "SelPrkOutDirReq";
BA_ "Origin" SG_ 493 SelPrkOutDirReq "fuel,ev";
BA_ "GenSigSendType" SG_ 493 StartPrkgPath2Cmd 2;
BA_ "Match" SG_ 493 StartPrkgPath2Cmd "StartPrkgPath2Cmd";
BA_ "Origin" SG_ 493 StartPrkgPath2Cmd "fuel,ev";
BA_ "GenSigSendType" SG_ 493 DeletePath2Cmd 2;
BA_ "Match" SG_ 493 DeletePath2Cmd "DeletePath2Cmd";
BA_ "Origin" SG_ 493 DeletePath2Cmd "fuel,ev";
BA_ "GenSigSendType" SG_ 493 StartPrkgPath1Cmd 2;
BA_ "Match" SG_ 493 StartPrkgPath1Cmd "StartPrkgPath1Cmd";
BA_ "Origin" SG_ 493 StartPrkgPath1Cmd "fuel,ev";
BA_ "GenSigSendType" SG_ 493 DeletePath1Cmd 2;
BA_ "Match" SG_ 493 DeletePath1Cmd "DeletePath1Cmd";
BA_ "Origin" SG_ 493 DeletePath1Cmd "fuel,ev";
BA_ "GenSigSendType" SG_ 493 SelPrkgFctnCmd 2;
BA_ "Match" SG_ 493 SelPrkgFctnCmd "SelPrkgFctnCmd";
BA_ "Origin" SG_ 493 SelPrkgFctnCmd "fuel,ev";
BA_ "GenSigSendType" SG_ 493 ParkMdlCmd 2;
BA_ "Match" SG_ 493 ParkMdlCmd "ParkMdlCmd";
BA_ "Origin" SG_ 493 ParkMdlCmd "fuel,ev";
BA_ "GenSigSendType" SG_ 493 BackReq_APS 2;
BA_ "Match" SG_ 493 BackReq_APS "BackReq_APS";
BA_ "Origin" SG_ 493 BackReq_APS "fuel,ev";
BA_ "GenSigSendType" SG_ 493 ACFGAEnaReq_TC 2;
BA_ "Match" SG_ 493 ACFGAEnaReq_TC "ACFGAEnaReq_TC";
BA_ "Origin" SG_ 493 ACFGAEnaReq_TC "fuel,ev";
BA_ "GenSigSendType" SG_ 493 ACFGAChanTyp_TC 2;
BA_ "Match" SG_ 493 ACFGAChanTyp_TC "ACFGAChanTyp_TC";
BA_ "Origin" SG_ 493 ACFGAChanTyp_TC "fuel,ev";
BA_ "GenSigSendType" SG_ 493 ACFGALvlReq_TC 2;
BA_ "Match" SG_ 493 ACFGALvlReq_TC "ACFGALvlReq_TC";
BA_ "Origin" SG_ 493 ACFGALvlReq_TC "fuel,ev";
BA_ "GenSigSendType" SG_ 493 P2P_PrkgDirectSwtCmd 2;
BA_ "Match" SG_ 493 P2P_PrkgDirectSwtCmd "P2P_PrkgDirectSwtCmd";
BA_ "Origin" SG_ 493 P2P_PrkgDirectSwtCmd "fuel,ev";
BA_ "GenSigCycleTime" SG_ 880 TimeMod 1000;
BA_ "Match" SG_ 880 TimeMod "TimeMod";
BA_ "Origin" SG_ 880 TimeMod "fuel,ev";
BA_ "GenSigCycleTime" SG_ 880 TimeIndcn 1000;
BA_ "Match" SG_ 880 TimeIndcn "TimeIndcn";
BA_ "Origin" SG_ 880 TimeIndcn "fuel,ev";
BA_ "GenSigCycleTime" SG_ 880 Time_Hour 1000;
BA_ "GenSigStartValue" SG_ 880 Time_Hour 31;
BA_ "Match" SG_ 880 Time_Hour "Time_Hour";
BA_ "Origin" SG_ 880 Time_Hour "fuel,ev";
BA_ "GenSigCycleTime" SG_ 880 Time_Minutes 1000;
BA_ "GenSigStartValue" SG_ 880 Time_Minutes 63;
BA_ "Match" SG_ 880 Time_Minutes "Time_Minutes";
BA_ "Origin" SG_ 880 Time_Minutes "fuel,ev";
BA_ "GenSigCycleTime" SG_ 880 Time_Second 1000;
BA_ "GenSigStartValue" SG_ 880 Time_Second 63;
BA_ "Match" SG_ 880 Time_Second "Time_Second";
BA_ "Origin" SG_ 880 Time_Second "fuel,ev";
BA_ "GenSigCycleTime" SG_ 880 Time_Year_Left 1000;
BA_ "GenSigStartValue" SG_ 880 Time_Year_Left 15;
BA_ "Match" SG_ 880 Time_Year_Left "Time_Year_Left";
BA_ "Origin" SG_ 880 Time_Year_Left "fuel,ev";
BA_ "GenSigCycleTime" SG_ 880 Time_Year_Right 1000;
BA_ "GenSigStartValue" SG_ 880 Time_Year_Right 15;
BA_ "Match" SG_ 880 Time_Year_Right "Time_Year_Right";
BA_ "Origin" SG_ 880 Time_Year_Right "fuel,ev";
BA_ "GenSigCycleTime" SG_ 880 Time_Month 1000;
BA_ "Match" SG_ 880 Time_Month "Time_Month";
BA_ "Origin" SG_ 880 Time_Month "fuel,ev";
BA_ "GenSigCycleTime" SG_ 880 Time_Day 1000;
BA_ "Match" SG_ 880 Time_Day "Time_Day";
BA_ "Origin" SG_ 880 Time_Day "fuel,ev";
BA_ "GenSigCycleTime" SG_ 880 HUT_TgtSOCSet 1000;
BA_ "Match" SG_ 880 HUT_TgtSOCSet "HUT_TgtSOCSet";
BA_ "Origin" SG_ 880 HUT_TgtSOCSet "ev";
BA_ "GenSigSendType" SG_ 485 ACRearTempReq_ETC_VR 2;
BA_ "Match" SG_ 485 ACRearTempReq_ETC_VR "ACRearTempReq_ETC_VR";
BA_ "Origin" SG_ 485 ACRearTempReq_ETC_VR "fuel,ev";
BA_ "GenSigSendType" SG_ 485 ACRearTempSteplsReq_ETC_TC 2;
BA_ "Match" SG_ 485 ACRearTempSteplsReq_ETC_TC "ACRearTempSteplsReq_ETC_TC";
BA_ "Origin" SG_ 485 ACRearTempSteplsReq_ETC_TC "fuel,ev";
BA_ "GenSigSendType" SG_ 485 ACDrvTempDecReq_ETC_TC 2;
BA_ "Match" SG_ 485 ACDrvTempDecReq_ETC_TC "ACDrvTempDecReq_ETC_TC";
BA_ "Origin" SG_ 485 ACDrvTempDecReq_ETC_TC "fuel,ev";
BA_ "GenSigSendType" SG_ 485 ACDrvTempIncReq_ETC_TC 2;
BA_ "Match" SG_ 485 ACDrvTempIncReq_ETC_TC "ACDrvTempIncReq_ETC_TC";
BA_ "Origin" SG_ 485 ACDrvTempIncReq_ETC_TC "fuel,ev";
BA_ "GenSigSendType" SG_ 485 ACRearTempDecReq_ETC_TC 2;
BA_ "Match" SG_ 485 ACRearTempDecReq_ETC_TC "ACRearTempDecReq_ETC_TC";
BA_ "Origin" SG_ 485 ACRearTempDecReq_ETC_TC "fuel,ev";
BA_ "GenSigSendType" SG_ 485 ACRearTempIncReq_ETC_TC 2;
BA_ "Match" SG_ 485 ACRearTempIncReq_ETC_TC "ACRearTempIncReq_ETC_TC";
BA_ "Origin" SG_ 485 ACRearTempIncReq_ETC_TC "fuel,ev";
BA_ "GenSigSendType" SG_ 485 ACRearPowerReq_VR 2;
BA_ "Match" SG_ 485 ACRearPowerReq_VR "ACRearPowerReq_VR";
BA_ "Origin" SG_ 485 ACRearPowerReq_VR "fuel,ev";
BA_ "GenSigSendType" SG_ 485 ACMaxReq_VR 2;
BA_ "Match" SG_ 485 ACMaxReq_VR "ACMaxReq_VR";
BA_ "Origin" SG_ 485 ACMaxReq_VR "fuel,ev";
BA_ "GenSigSendType" SG_ 485 ACMaxReq_TC 2;
BA_ "Match" SG_ 485 ACMaxReq_TC "ACMaxReq_TC";
BA_ "Origin" SG_ 485 ACMaxReq_TC "fuel,ev";
BA_ "GenSigSendType" SG_ 485 FrntWiprCtrl_VR 2;
BA_ "Match" SG_ 485 FrntWiprCtrl_VR "FrntWiprCtrl_VR";
BA_ "Origin" SG_ 485 FrntWiprCtrl_VR "fuel,ev";
BA_ "GenSigSendType" SG_ 485 ACRearAutoModReq_VR 2;
BA_ "Match" SG_ 485 ACRearAutoModReq_VR "ACRearAutoModReq_VR";
BA_ "Origin" SG_ 485 ACRearAutoModReq_VR "fuel,ev";
BA_ "GenSigSendType" SG_ 485 LockWinSet 2;
BA_ "Match" SG_ 485 LockWinSet "LockWinSet";
BA_ "Origin" SG_ 485 LockWinSet "fuel,ev";
BA_ "GenSigSendType" SG_ 485 ACRearLockReq_TC 2;
BA_ "Match" SG_ 485 ACRearLockReq_TC "ACRearLockReq_TC";
BA_ "Origin" SG_ 485 ACRearLockReq_TC "fuel,ev";
BA_ "GenSigSendType" SG_ 485 SrSpdCtrlSwt 2;
BA_ "Match" SG_ 485 SrSpdCtrlSwt "SrSpdCtrlSwt";
BA_ "Origin" SG_ 485 SrSpdCtrlSwt "fuel";
BA_ "GenSigSendType" SG_ 485 DPF_Request 2;
BA_ "Match" SG_ 485 DPF_Request "DPF_Request";
BA_ "Origin" SG_ 485 DPF_Request "fuel,ev";
BA_ "GenSigSendType" SG_ 485 ColorCategory 2;
BA_ "Match" SG_ 485 ColorCategory "ColorCategory";
BA_ "Origin" SG_ 485 ColorCategory "fuel";
BA_ "GenSigSendType" SG_ 485 SingleColorNr 2;
BA_ "GenSigStartValue" SG_ 485 SingleColorNr 8;
BA_ "Match" SG_ 485 SingleColorNr "SingleColorNr";
BA_ "Origin" SG_ 485 SingleColorNr "fuel";
BA_ "GenSigSendType" SG_ 487 ACRLTempDecReq_TC 2;
BA_ "Match" SG_ 487 ACRLTempDecReq_TC "ACRLTempDecReq_TC";
BA_ "Origin" SG_ 487 ACRLTempDecReq_TC "fuel,ev";
BA_ "GenSigSendType" SG_ 487 ACRLTempIncReq_TC 2;
BA_ "Match" SG_ 487 ACRLTempIncReq_TC "ACRLTempIncReq_TC";
BA_ "Origin" SG_ 487 ACRLTempIncReq_TC "fuel,ev";
BA_ "GenSigSendType" SG_ 487 ACRLTempReq_VR 2;
BA_ "Match" SG_ 487 ACRLTempReq_VR "ACRLTempReq_VR";
BA_ "Origin" SG_ 487 ACRLTempReq_VR "fuel,ev";
BA_ "GenSigSendType" SG_ 487 ACRRTempDecReq_TC 2;
BA_ "Match" SG_ 487 ACRRTempDecReq_TC "ACRRTempDecReq_TC";
BA_ "Origin" SG_ 487 ACRRTempDecReq_TC "fuel,ev";
BA_ "GenSigSendType" SG_ 487 ACRRTempIncReq_TC 2;
BA_ "Match" SG_ 487 ACRRTempIncReq_TC "ACRRTempIncReq_TC";
BA_ "Origin" SG_ 487 ACRRTempIncReq_TC "fuel,ev";
BA_ "GenSigSendType" SG_ 487 ACRRTempReq_VR 2;
BA_ "Match" SG_ 487 ACRRTempReq_VR "ACRRTempReq_VR";
BA_ "Origin" SG_ 487 ACRRTempReq_VR "fuel,ev";
BA_ "GenSigSendType" SG_ 487 ACRRTempSteplsReq_TC 2;
BA_ "Match" SG_ 487 ACRRTempSteplsReq_TC "ACRRTempSteplsReq_TC";
BA_ "Origin" SG_ 487 ACRRTempSteplsReq_TC "fuel,ev";
BA_ "GenSigSendType" SG_ 487 ACHumidifierReq_VR 2;
BA_ "Match" SG_ 487 ACHumidifierReq_VR "ACHumidifierReq_VR";
BA_ "Origin" SG_ 487 ACHumidifierReq_VR "fuel,ev";
BA_ "GenSigSendType" SG_ 487 ACHumidifierReq_TC 2;
BA_ "Match" SG_ 487 ACHumidifierReq_TC "ACHumidifierReq_TC";
BA_ "Origin" SG_ 487 ACHumidifierReq_TC "fuel,ev";
BA_ "GenSigSendType" SG_ 487 ACOzoneReq_TC 2;
BA_ "Match" SG_ 487 ACOzoneReq_TC "ACOzoneReq_TC";
BA_ "Origin" SG_ 487 ACOzoneReq_TC "fuel,ev";
BA_ "GenSigSendType" SG_ 487 ACOzoneReq_VR 2;
BA_ "Match" SG_ 487 ACOzoneReq_VR "ACOzoneReq_VR";
BA_ "Origin" SG_ 487 ACOzoneReq_VR "fuel,ev";
BA_ "GenSigSendType" SG_ 487 ACUltravioletReq_TC 2;
BA_ "Match" SG_ 487 ACUltravioletReq_TC "ACUltravioletReq_TC";
BA_ "Origin" SG_ 487 ACUltravioletReq_TC "fuel,ev";
BA_ "GenSigSendType" SG_ 487 ACUltravioletReq_VR 2;
BA_ "Match" SG_ 487 ACUltravioletReq_VR "ACUltravioletReq_VR";
BA_ "Origin" SG_ 487 ACUltravioletReq_VR "fuel,ev";
BA_ "GenSigSendType" SG_ 487 ACFrntWinHeatCmd_TC 2;
BA_ "Match" SG_ 487 ACFrntWinHeatCmd_TC "ACFrntWinHeatCmd_TC";
BA_ "Origin" SG_ 487 ACFrntWinHeatCmd_TC "fuel,ev";
BA_ "GenSigSendType" SG_ 487 ACFrntWinHeatCmd_VR 2;
BA_ "Match" SG_ 487 ACFrntWinHeatCmd_VR "ACFrntWinHeatCmd_VR";
BA_ "Origin" SG_ 487 ACFrntWinHeatCmd_VR "fuel,ev";
BA_ "GenSigSendType" SG_ 487 DrvDoorALCMFlashFreq 2;
BA_ "Match" SG_ 487 DrvDoorALCMFlashFreq "DrvDoorALCMFlashFreq";
BA_ "Origin" SG_ 487 DrvDoorALCMFlashFreq "fuel,ev";
BA_ "GenSigSendType" SG_ 487 PassDoorALCMFlashFreq 2;
BA_ "Match" SG_ 487 PassDoorALCMFlashFreq "PassDoorALCMFlashFreq";
BA_ "Origin" SG_ 487 PassDoorALCMFlashFreq "fuel,ev";
BA_ "GenSigSendType" SG_ 487 LRDoorALCMFlashFreq 2;
BA_ "Match" SG_ 487 LRDoorALCMFlashFreq "LRDoorALCMFlashFreq";
BA_ "Origin" SG_ 487 LRDoorALCMFlashFreq "fuel,ev";
BA_ "GenSigSendType" SG_ 487 RRDoorALCMFlashFreq 2;
BA_ "Match" SG_ 487 RRDoorALCMFlashFreq "RRDoorALCMFlashFreq";
BA_ "Origin" SG_ 487 RRDoorALCMFlashFreq "fuel,ev";
BA_ "GenSigSendType" SG_ 487 FootALCMFlashFreq 2;
BA_ "Match" SG_ 487 FootALCMFlashFreq "FootALCMFlashFreq";
BA_ "Origin" SG_ 487 FootALCMFlashFreq "fuel";
BA_ "GenSigSendType" SG_ 487 LeftPanelALCMFlashFreq 2;
BA_ "Match" SG_ 487 LeftPanelALCMFlashFreq "LeftPanelALCMFlashFreq";
BA_ "Origin" SG_ 487 LeftPanelALCMFlashFreq "fuel,ev";
BA_ "GenSigSendType" SG_ 487 RightPanelALCMFlashFreq 2;
BA_ "Match" SG_ 487 RightPanelALCMFlashFreq "RightPanelALCMFlashFreq";
BA_ "Origin" SG_ 487 RightPanelALCMFlashFreq "fuel,ev";
BA_ "GenSigSendType" SG_ 487 ACRearLockReq_VR 2;
BA_ "Match" SG_ 487 ACRearLockReq_VR "ACRearLockReq_VR";
BA_ "Origin" SG_ 487 ACRearLockReq_VR "fuel,ev";
BA_ "GenSigSendType" SG_ 491 ActvEntryLockSet 2;
BA_ "Match" SG_ 491 ActvEntryLockSet "ActvEntryLockSet";
BA_ "Origin" SG_ 491 ActvEntryLockSet "fuel,ev";
BA_ "GenSigSendType" SG_ 491 ActvEntryUnlockSet 2;
BA_ "Match" SG_ 491 ActvEntryUnlockSet "ActvEntryUnlockSet";
BA_ "Origin" SG_ 491 ActvEntryUnlockSet "fuel,ev";
BA_ "GenSigSendType" SG_ 491 LockPromptFunSet 2;
BA_ "Match" SG_ 491 LockPromptFunSet "LockPromptFunSet";
BA_ "Origin" SG_ 491 LockPromptFunSet "fuel,ev";
BA_ "GenSigSendType" SG_ 491 BTAPAEntryLockSet 2;
BA_ "Match" SG_ 491 BTAPAEntryLockSet "BTAPAEntryLockSet";
BA_ "Origin" SG_ 491 BTAPAEntryLockSet "fuel,ev";
BA_ "GenSigSendType" SG_ 491 BTAPALvngUnlockSet 2;
BA_ "Match" SG_ 491 BTAPALvngUnlockSet "BTAPALvngUnlockSet";
BA_ "Origin" SG_ 491 BTAPALvngUnlockSet "fuel,ev";
BA_ "GenSigSendType" SG_ 491 ClsWinSpdSet 2;
BA_ "Match" SG_ 491 ClsWinSpdSet "ClsWinSpdSet";
BA_ "Origin" SG_ 491 ClsWinSpdSet "fuel,ev";
BA_ "GenSigSendType" SG_ 491 DrvSeatMassgLvlSet 2;
BA_ "Match" SG_ 491 DrvSeatMassgLvlSet "DrvSeatMassgLvlSet";
BA_ "Origin" SG_ 491 DrvSeatMassgLvlSet "fuel,ev";
BA_ "GenSigSendType" SG_ 491 PassSeatMassgLvlSet 2;
BA_ "Match" SG_ 491 PassSeatMassgLvlSet "PassSeatMassgLvlSet";
BA_ "Origin" SG_ 491 PassSeatMassgLvlSet "fuel,ev";
BA_ "GenSigSendType" SG_ 491 SeatKeyMemEna 2;
BA_ "Match" SG_ 491 SeatKeyMemEna "SeatKeyMemEna";
BA_ "Origin" SG_ 491 SeatKeyMemEna "fuel,ev";
BA_ "GenSigSendType" SG_ 491 RLSeatMassgLvlSet 2;
BA_ "Match" SG_ 491 RLSeatMassgLvlSet "RLSeatMassgLvlSet";
BA_ "Origin" SG_ 491 RLSeatMassgLvlSet "fuel,ev";
BA_ "GenSigSendType" SG_ 491 RRSeatMassgLvlSet 2;
BA_ "Match" SG_ 491 RRSeatMassgLvlSet "RRSeatMassgLvlSet";
BA_ "Origin" SG_ 491 RRSeatMassgLvlSet "fuel,ev";
BA_ "GenSigSendType" SG_ 491 DrvDoorALCMClrSet 2;
BA_ "GenSigStartValue" SG_ 491 DrvDoorALCMClrSet 64;
BA_ "Match" SG_ 491 DrvDoorALCMClrSet "DrvDoorALCMClrSet";
BA_ "Origin" SG_ 491 DrvDoorALCMClrSet "fuel,ev";
BA_ "GenSigSendType" SG_ 491 PassDoorALCMClrSet 2;
BA_ "GenSigStartValue" SG_ 491 PassDoorALCMClrSet 64;
BA_ "Match" SG_ 491 PassDoorALCMClrSet "PassDoorALCMClrSet";
BA_ "Origin" SG_ 491 PassDoorALCMClrSet "fuel,ev";
BA_ "GenSigSendType" SG_ 491 LRDoorALCMClrSet 2;
BA_ "GenSigStartValue" SG_ 491 LRDoorALCMClrSet 64;
BA_ "Match" SG_ 491 LRDoorALCMClrSet "LRDoorALCMClrSet";
BA_ "Origin" SG_ 491 LRDoorALCMClrSet "fuel,ev";
BA_ "GenSigSendType" SG_ 491 DrvDoorALCMSwt 2;
BA_ "Match" SG_ 491 DrvDoorALCMSwt "DrvDoorALCMSwt";
BA_ "Origin" SG_ 491 DrvDoorALCMSwt "fuel,ev";
BA_ "GenSigSendType" SG_ 491 PassDoorALCMSwt 2;
BA_ "Match" SG_ 491 PassDoorALCMSwt "PassDoorALCMSwt";
BA_ "Origin" SG_ 491 PassDoorALCMSwt "fuel,ev";
BA_ "GenSigSendType" SG_ 877 DrvSeatVentnLvlSet 2;
BA_ "Match" SG_ 877 DrvSeatVentnLvlSet "DrvSeatVentnLvlSet";
BA_ "Origin" SG_ 877 DrvSeatVentnLvlSet "fuel,ev";
BA_ "GenSigSendType" SG_ 877 PassSeatVentnLvlSet 2;
BA_ "Match" SG_ 877 PassSeatVentnLvlSet "PassSeatVentnLvlSet";
BA_ "Origin" SG_ 877 PassSeatVentnLvlSet "fuel,ev";
BA_ "GenSigSendType" SG_ 877 ACAutoModReq_VR 2;
BA_ "Match" SG_ 877 ACAutoModReq_VR "ACAutoModReq_VR";
BA_ "Origin" SG_ 877 ACAutoModReq_VR "fuel,ev";
BA_ "GenSigSendType" SG_ 877 ACCmprReq_VR 2;
BA_ "Match" SG_ 877 ACCmprReq_VR "ACCmprReq_VR";
BA_ "Origin" SG_ 877 ACCmprReq_VR "fuel,ev";
BA_ "GenSigSendType" SG_ 877 ACPowerReq_VR 2;
BA_ "Match" SG_ 877 ACPowerReq_VR "ACPowerReq_VR";
BA_ "Origin" SG_ 877 ACPowerReq_VR "fuel,ev";
BA_ "GenSigSendType" SG_ 877 ACBlwrSpdReq_VR 2;
BA_ "Match" SG_ 877 ACBlwrSpdReq_VR "ACBlwrSpdReq_VR";
BA_ "Origin" SG_ 877 ACBlwrSpdReq_VR "fuel,ev";
BA_ "GenSigSendType" SG_ 877 ACDrvTempReq_VR 2;
BA_ "Match" SG_ 877 ACDrvTempReq_VR "ACDrvTempReq_VR";
BA_ "Origin" SG_ 877 ACDrvTempReq_VR "fuel,ev";
BA_ "GenSigSendType" SG_ 877 ACFrntDefrostReq_VR 2;
BA_ "Match" SG_ 877 ACFrntDefrostReq_VR "ACFrntDefrostReq_VR";
BA_ "Origin" SG_ 877 ACFrntDefrostReq_VR "fuel,ev";
BA_ "GenSigSendType" SG_ 877 ACDrvAirDistribModReq_VR 2;
BA_ "Match" SG_ 877 ACDrvAirDistribModReq_VR "ACDrvAirDistribModReq_VR";
BA_ "Origin" SG_ 877 ACDrvAirDistribModReq_VR "fuel,ev";
BA_ "GenSigSendType" SG_ 877 ACAirInletReq_VR 2;
BA_ "Match" SG_ 877 ACAirInletReq_VR "ACAirInletReq_VR";
BA_ "Origin" SG_ 877 ACAirInletReq_VR "fuel,ev";
BA_ "GenSigSendType" SG_ 877 ACModReq_HUT 2;
BA_ "GenSigStartValue" SG_ 877 ACModReq_HUT 1;
BA_ "Match" SG_ 877 ACModReq_HUT "ACModReq_HUT";
BA_ "Origin" SG_ 877 ACModReq_HUT "fuel,ev";
BA_ "GenSigSendType" SG_ 877 ElecSideSteppingSysSet 2;
BA_ "GenSigStartValue" SG_ 877 ElecSideSteppingSysSet 1;
BA_ "Match" SG_ 877 ElecSideSteppingSysSet "ElecSideSteppingSysSet";
BA_ "Origin" SG_ 877 ElecSideSteppingSysSet "fuel,ev";
BA_ "GenSigSendType" SG_ 877 RoofModSet 2;
BA_ "Match" SG_ 877 RoofModSet "RoofModSet";
BA_ "Origin" SG_ 877 RoofModSet "fuel,ev";
BA_ "GenSigSendType" SG_ 877 AllTerrainDislSet 2;
BA_ "Match" SG_ 877 AllTerrainDislSet "AllTerrainDislSet";
BA_ "Origin" SG_ 877 AllTerrainDislSet "fuel,ev";
BA_ "GenSigSendType" SG_ 877 RemUpgrdSts 2;
BA_ "Match" SG_ 877 RemUpgrdSts "RemUpgrdSts";
BA_ "Origin" SG_ 877 RemUpgrdSts "fuel,ev";
BA_ "GenSigSendType" SG_ 877 ACRearAutoModReq_TC 2;
BA_ "Match" SG_ 877 ACRearAutoModReq_TC "ACRearAutoModReq_TC";
BA_ "Origin" SG_ 877 ACRearAutoModReq_TC "fuel,ev";
BA_ "GenSigSendType" SG_ 877 DrvSeatSupportLvlSet 2;
BA_ "Match" SG_ 877 DrvSeatSupportLvlSet "DrvSeatSupportLvlSet";
BA_ "Origin" SG_ 877 DrvSeatSupportLvlSet "fuel,ev";
BA_ "GenSigSendType" SG_ 877 PassSeatSupportLvlSet 2;
BA_ "Match" SG_ 877 PassSeatSupportLvlSet "PassSeatSupportLvlSet";
BA_ "Origin" SG_ 877 PassSeatSupportLvlSet "fuel,ev";
BA_ "GenSigSendType" SG_ 877 ACRearOffReq_TC 2;
BA_ "Match" SG_ 877 ACRearOffReq_TC "ACRearOffReq_TC";
BA_ "Origin" SG_ 877 ACRearOffReq_TC "fuel,ev";
BA_ "GenSigSendType" SG_ 877 ACRearAirDistribModReq_TC 2;
BA_ "Match" SG_ 877 ACRearAirDistribModReq_TC "ACRearAirDistribModReq_TC";
BA_ "Origin" SG_ 877 ACRearAirDistribModReq_TC "fuel,ev";
BA_ "GenSigSendType" SG_ 877 RLSeatVentnLvlSet 2;
BA_ "Match" SG_ 877 RLSeatVentnLvlSet "RLSeatVentnLvlSet";
BA_ "Origin" SG_ 877 RLSeatVentnLvlSet "fuel,ev";
BA_ "GenSigSendType" SG_ 877 RRSeatVentnLvlSet 2;
BA_ "Match" SG_ 877 RRSeatVentnLvlSet "RRSeatVentnLvlSet";
BA_ "Origin" SG_ 877 RRSeatVentnLvlSet "fuel,ev";
BA_ "GenSigCycleTime" SG_ 548 ALCMMasterSwt 50;
BA_ "GenSigStartValue" SG_ 548 ALCMMasterSwt 1;
BA_ "Match" SG_ 548 ALCMMasterSwt "ALCMMasterSwt";
BA_ "Origin" SG_ 548 ALCMMasterSwt "fuel,ev";
BA_ "GenSigCycleTime" SG_ 548 ALCMPartitionSwt 50;
BA_ "Match" SG_ 548 ALCMPartitionSwt "ALCMPartitionSwt";
BA_ "Origin" SG_ 548 ALCMPartitionSwt "fuel,ev";
BA_ "GenSigCycleTime" SG_ 548 MusicFrq0 50;
BA_ "GenSigStartValue" SG_ 548 MusicFrq0 101;
BA_ "Match" SG_ 548 MusicFrq0 "MusicFrq0";
BA_ "Origin" SG_ 548 MusicFrq0 "fuel,ev";
BA_ "GenSigCycleTime" SG_ 548 MusicFrq1 50;
BA_ "GenSigStartValue" SG_ 548 MusicFrq1 101;
BA_ "Match" SG_ 548 MusicFrq1 "MusicFrq1";
BA_ "Origin" SG_ 548 MusicFrq1 "fuel,ev";
BA_ "GenSigCycleTime" SG_ 548 MusicFrq2 50;
BA_ "GenSigStartValue" SG_ 548 MusicFrq2 101;
BA_ "Match" SG_ 548 MusicFrq2 "MusicFrq2";
BA_ "Origin" SG_ 548 MusicFrq2 "fuel,ev";
BA_ "GenSigCycleTime" SG_ 548 MusicFrq3 50;
BA_ "GenSigStartValue" SG_ 548 MusicFrq3 101;
BA_ "Match" SG_ 548 MusicFrq3 "MusicFrq3";
BA_ "Origin" SG_ 548 MusicFrq3 "fuel,ev";
BA_ "GenSigCycleTime" SG_ 548 MusicFrq4 50;
BA_ "GenSigStartValue" SG_ 548 MusicFrq4 101;
BA_ "Match" SG_ 548 MusicFrq4 "MusicFrq4";
BA_ "Origin" SG_ 548 MusicFrq4 "fuel,ev";
BA_ "GenSigCycleTime" SG_ 548 MusicFrq5 50;
BA_ "GenSigStartValue" SG_ 548 MusicFrq5 101;
BA_ "Match" SG_ 548 MusicFrq5 "MusicFrq5";
BA_ "Origin" SG_ 548 MusicFrq5 "fuel,ev";
BA_ "GenSigCycleTime" SG_ 548 MusicFrq6 50;
BA_ "GenSigStartValue" SG_ 548 MusicFrq6 101;
BA_ "Match" SG_ 548 MusicFrq6 "MusicFrq6";
BA_ "Origin" SG_ 548 MusicFrq6 "fuel,ev";
BA_ "GenSigSendType" SG_ 507 RRDoorALCMClrSet 2;
BA_ "GenSigStartValue" SG_ 507 RRDoorALCMClrSet 64;
BA_ "Match" SG_ 507 RRDoorALCMClrSet "RRDoorALCMClrSet";
BA_ "Origin" SG_ 507 RRDoorALCMClrSet "fuel,ev";
BA_ "GenSigSendType" SG_ 507 LeftPanelALCMClrSet 2;
BA_ "GenSigStartValue" SG_ 507 LeftPanelALCMClrSet 64;
BA_ "Match" SG_ 507 LeftPanelALCMClrSet "LeftPanelALCMClrSet";
BA_ "Origin" SG_ 507 LeftPanelALCMClrSet "fuel,ev";
BA_ "GenSigSendType" SG_ 507 RightPanelALCMClrSet 2;
BA_ "GenSigStartValue" SG_ 507 RightPanelALCMClrSet 64;
BA_ "Match" SG_ 507 RightPanelALCMClrSet "RightPanelALCMClrSet";
BA_ "Origin" SG_ 507 RightPanelALCMClrSet "fuel,ev";
BA_ "GenSigSendType" SG_ 507 FootALCMClrSet 2;
BA_ "GenSigStartValue" SG_ 507 FootALCMClrSet 64;
BA_ "Match" SG_ 507 FootALCMClrSet "FootALCMClrSet";
BA_ "Origin" SG_ 507 FootALCMClrSet "fuel";
BA_ "GenSigSendType" SG_ 507 DrvDoorALCMLightLvlSet 2;
BA_ "Match" SG_ 507 DrvDoorALCMLightLvlSet "DrvDoorALCMLightLvlSet";
BA_ "Origin" SG_ 507 DrvDoorALCMLightLvlSet "fuel,ev";
BA_ "GenSigSendType" SG_ 507 PassDoorALCMLightLvlSet 2;
BA_ "Match" SG_ 507 PassDoorALCMLightLvlSet "PassDoorALCMLightLvlSet";
BA_ "Origin" SG_ 507 PassDoorALCMLightLvlSet "fuel,ev";
BA_ "GenSigSendType" SG_ 507 LRDoorALCMLightLvlSet 2;
BA_ "Match" SG_ 507 LRDoorALCMLightLvlSet "LRDoorALCMLightLvlSet";
BA_ "Origin" SG_ 507 LRDoorALCMLightLvlSet "fuel,ev";
BA_ "GenSigSendType" SG_ 507 RRDoorALCMLightLvlSet 2;
BA_ "Match" SG_ 507 RRDoorALCMLightLvlSet "RRDoorALCMLightLvlSet";
BA_ "Origin" SG_ 507 RRDoorALCMLightLvlSet "fuel,ev";
BA_ "GenSigSendType" SG_ 507 LeftPanelALCMLightLvlSet 2;
BA_ "Match" SG_ 507 LeftPanelALCMLightLvlSet "LeftPanelALCMLightLvlSet";
BA_ "Origin" SG_ 507 LeftPanelALCMLightLvlSet "fuel,ev";
BA_ "GenSigSendType" SG_ 507 RightPanelALCMLightLvlSet 2;
BA_ "Match" SG_ 507 RightPanelALCMLightLvlSet "RightPanelALCMLightLvlSet";
BA_ "Origin" SG_ 507 RightPanelALCMLightLvlSet "fuel,ev";
BA_ "GenSigSendType" SG_ 507 FootALCMLightLvlSet 2;
BA_ "Match" SG_ 507 FootALCMLightLvlSet "FootALCMLightLvlSet";
BA_ "Origin" SG_ 507 FootALCMLightLvlSet "fuel";
BA_ "GenSigSendType" SG_ 507 ALCMFloSwt 2;
BA_ "Match" SG_ 507 ALCMFloSwt "ALCMFloSwt";
BA_ "Origin" SG_ 507 ALCMFloSwt "fuel,ev";
BA_ "GenSigSendType" SG_ 507 ALCMBreSwt 2;
BA_ "Match" SG_ 507 ALCMBreSwt "ALCMBreSwt";
BA_ "Origin" SG_ 507 ALCMBreSwt "fuel,ev";
BA_ "GenSigSendType" SG_ 507 RightPanelALCMSwt 2;
BA_ "Match" SG_ 507 RightPanelALCMSwt "RightPanelALCMSwt";
BA_ "Origin" SG_ 507 RightPanelALCMSwt "fuel,ev";
BA_ "GenSigSendType" SG_ 507 LRDoorALCMSwt 2;
BA_ "Match" SG_ 507 LRDoorALCMSwt "LRDoorALCMSwt";
BA_ "Origin" SG_ 507 LRDoorALCMSwt "fuel,ev";
BA_ "GenSigSendType" SG_ 507 RRDoorALCMSwt 2;
BA_ "Match" SG_ 507 RRDoorALCMSwt "RRDoorALCMSwt";
BA_ "Origin" SG_ 507 RRDoorALCMSwt "fuel,ev";
BA_ "GenSigSendType" SG_ 507 FootALCMSwt 2;
BA_ "Match" SG_ 507 FootALCMSwt "FootALCMSwt";
BA_ "Origin" SG_ 507 FootALCMSwt "fuel,ev";
BA_ "GenSigSendType" SG_ 507 RoofALCMSwt 2;
BA_ "Match" SG_ 507 RoofALCMSwt "RoofALCMSwt";
BA_ "Origin" SG_ 507 RoofALCMSwt "fuel,ev";
BA_ "GenSigSendType" SG_ 507 LeftPanelALCMSwt 2;
BA_ "GenSigStartValue" SG_ 507 LeftPanelALCMSwt 1;
BA_ "Match" SG_ 507 LeftPanelALCMSwt "LeftPanelALCMSwt";
BA_ "Origin" SG_ 507 LeftPanelALCMSwt "fuel,ev";
BA_ "GenSigSendType" SG_ 505 ACRLTempSteplsReq_TC 2;
BA_ "Match" SG_ 505 ACRLTempSteplsReq_TC "ACRLTempSteplsReq_TC";
BA_ "Origin" SG_ 505 ACRLTempSteplsReq_TC "fuel,ev";
BA_ "GenSigSendType" SG_ 509 RLSeatMassgModSet 2;
BA_ "Match" SG_ 509 RLSeatMassgModSet "RLSeatMassgModSet";
BA_ "Origin" SG_ 509 RLSeatMassgModSet "fuel,ev";
BA_ "GenSigSendType" SG_ 509 RRSeatMassgModSet 2;
BA_ "Match" SG_ 509 RRSeatMassgModSet "RRSeatMassgModSet";
BA_ "Origin" SG_ 509 RRSeatMassgModSet "fuel,ev";
BA_ "GenSigSendType" SG_ 509 DrvSeatHeatgLvlSet_Nine 2;
BA_ "Match" SG_ 509 DrvSeatHeatgLvlSet_Nine "DrvSeatHeatgLvlSet_Nine";
BA_ "Origin" SG_ 509 DrvSeatHeatgLvlSet_Nine "fuel,ev";
BA_ "GenSigSendType" SG_ 509 PassSeatHeatgLvlSet_Nine 2;
BA_ "Match" SG_ 509 PassSeatHeatgLvlSet_Nine "PassSeatHeatgLvlSet_Nine";
BA_ "Origin" SG_ 509 PassSeatHeatgLvlSet_Nine "fuel,ev";
BA_ "GenSigSendType" SG_ 509 RLSeatHeatgLvlSet_Nine 2;
BA_ "Match" SG_ 509 RLSeatHeatgLvlSet_Nine "RLSeatHeatgLvlSet_Nine";
BA_ "Origin" SG_ 509 RLSeatHeatgLvlSet_Nine "fuel,ev";
BA_ "GenSigSendType" SG_ 509 RRSeatHeatgLvlSet_Nine 2;
BA_ "Match" SG_ 509 RRSeatHeatgLvlSet_Nine "RRSeatHeatgLvlSet_Nine";
BA_ "Origin" SG_ 509 RRSeatHeatgLvlSet_Nine "fuel,ev";
BA_ "GenSigSendType" SG_ 476 PassSeatMassgModSet 2;
BA_ "Match" SG_ 476 PassSeatMassgModSet "PassSeatMassgModSet";
BA_ "Origin" SG_ 476 PassSeatMassgModSet "fuel,ev";
BA_ "GenSigSendType" SG_ 476 DrvSeatMassgModSet 2;
BA_ "Match" SG_ 476 DrvSeatMassgModSet "DrvSeatMassgModSet";
BA_ "Origin" SG_ 476 DrvSeatMassgModSet "fuel,ev";
BA_ "GenSigSendType" SG_ 476 PPMI_P_BSR_SwtSet 2;
BA_ "GenSigStartValue" SG_ 476 PPMI_P_BSR_SwtSet 2;
BA_ "Match" SG_ 476 PPMI_P_BSR_SwtSet "PPMI_P_BSR_SwtSet";
BA_ "Origin" SG_ 476 PPMI_P_BSR_SwtSet "fuel,ev";
BA_ "GenSigSendType" SG_ 476 RWPC_SwtReq 2;
BA_ "GenSigStartValue" SG_ 476 RWPC_SwtReq 1;
BA_ "Match" SG_ 476 RWPC_SwtReq "RWPC_SwtReq";
BA_ "Origin" SG_ 476 RWPC_SwtReq "fuel,ev";
BA_ "GenSigSendType" SG_ 477 DrvSeatVentnLvlSet_Nine 2;
BA_ "Match" SG_ 477 DrvSeatVentnLvlSet_Nine "DrvSeatVentnLvlSet_Nine";
BA_ "Origin" SG_ 477 DrvSeatVentnLvlSet_Nine "fuel";
BA_ "GenSigSendType" SG_ 477 PassSeatVentnLvlSet_Nine 2;
BA_ "Match" SG_ 477 PassSeatVentnLvlSet_Nine "PassSeatVentnLvlSet_Nine";
BA_ "Origin" SG_ 477 PassSeatVentnLvlSet_Nine "fuel";
BA_ "GenSigSendType" SG_ 477 RLSeatVentnLvlSet_Nine 2;
BA_ "Match" SG_ 477 RLSeatVentnLvlSet_Nine "RLSeatVentnLvlSet_Nine";
BA_ "Origin" SG_ 477 RLSeatVentnLvlSet_Nine "fuel";
BA_ "GenSigSendType" SG_ 477 RRSeatVentnLvlSet_Nine 2;
BA_ "Match" SG_ 477 RRSeatVentnLvlSet_Nine "RRSeatVentnLvlSet_Nine";
BA_ "Origin" SG_ 477 RRSeatVentnLvlSet_Nine "fuel";
BA_ "GenSigSendType" SG_ 477 ARFSwtReq 2;
BA_ "Match" SG_ 477 ARFSwtReq "ARFSwtReq";
BA_ "Origin" SG_ 477 ARFSwtReq "ev";
BA_ "GenSigSendType" SG_ 477 ASFCSwtReq 2;
BA_ "Match" SG_ 477 ASFCSwtReq "ASFCSwtReq";
BA_ "Origin" SG_ 477 ASFCSwtReq "ev";
BA_ "GenSigSendType" SG_ 477 AGSSwtReq 2;
BA_ "Match" SG_ 477 AGSSwtReq "AGSSwtReq";
BA_ "Origin" SG_ 477 AGSSwtReq "ev";
BA_ "GenSigSendType" SG_ 477 SOCMngmntSwtReq 2;
BA_ "Match" SG_ 477 SOCMngmntSwtReq "SOCMngmntSwtReq";
BA_ "Origin" SG_ 477 SOCMngmntSwtReq "ev";
BA_ "GenSigSendType" SG_ 74 AUTODefrost_TC 2;
BA_ "Match" SG_ 74 AUTODefrost_TC "AUTODefrost_TC";
BA_ "Origin" SG_ 74 AUTODefrost_TC "fuel,ev";
BA_ "GenSigSendType" SG_ 74 AUTODefrost_VR 2;
BA_ "Match" SG_ 74 AUTODefrost_VR "AUTODefrost_VR";
BA_ "Origin" SG_ 74 AUTODefrost_VR "fuel,ev";
BA_ "GenSigSendType" SG_ 74 LaneCalActvtCmd 2;
BA_ "Match" SG_ 74 LaneCalActvtCmd "LaneCalActvtCmd";
BA_ "Origin" SG_ 74 LaneCalActvtCmd "fuel,ev";
BA_ "GenSigSendType" SG_ 74 MODChgReq 2;
BA_ "Match" SG_ 74 MODChgReq "MODChgReq";
BA_ "Origin" SG_ 74 MODChgReq "fuel,ev";
BA_ "GenSigSendType" SG_ 74 Radar_DispCmd 2;
BA_ "Match" SG_ 74 Radar_DispCmd "Radar_DispCmd";
BA_ "Origin" SG_ 74 Radar_DispCmd "fuel,ev";
BA_ "GenSigSendType" SG_ 74 Guid_Ovl_Display_Cmd 2;
BA_ "Match" SG_ 74 Guid_Ovl_Display_Cmd "Guid_Ovl_Display_Cmd";
BA_ "Origin" SG_ 74 Guid_Ovl_Display_Cmd "fuel,ev";
BA_ "GenSigSendType" SG_ 74 Sgl_View_Sel 2;
BA_ "Match" SG_ 74 Sgl_View_Sel "Sgl_View_Sel";
BA_ "Origin" SG_ 74 Sgl_View_Sel "fuel,ev";
BA_ "GenSigSendType" SG_ 74 SwToFieldCalRstCmd 2;
BA_ "Match" SG_ 74 SwToFieldCalRstCmd "SwToFieldCalRstCmd";
BA_ "Origin" SG_ 74 SwToFieldCalRstCmd "fuel,ev";
BA_ "GenSigSendType" SG_ 74 AutoViewChgCmd 2;
BA_ "Match" SG_ 74 AutoViewChgCmd "AutoViewChgCmd";
BA_ "Origin" SG_ 74 AutoViewChgCmd "fuel,ev";
BA_ "GenSigSendType" SG_ 74 MdlColrChgCmd 2;
BA_ "Match" SG_ 74 MdlColrChgCmd "MdlColrChgCmd";
BA_ "Origin" SG_ 74 MdlColrChgCmd "fuel,ev";
BA_ "GenSigSendType" SG_ 74 CarMdlTrsprcySwtCmd 2;
BA_ "Match" SG_ 74 CarMdlTrsprcySwtCmd "CarMdlTrsprcySwtCmd";
BA_ "Origin" SG_ 74 CarMdlTrsprcySwtCmd "fuel,ev";
BA_ "GenSigSendType" SG_ 74 CarMdlDispCmd 2;
BA_ "Match" SG_ 74 CarMdlDispCmd "CarMdlDispCmd";
BA_ "Origin" SG_ 74 CarMdlDispCmd "fuel,ev";
BA_ "GenSigSendType" SG_ 74 AutoAVMSwSet_Cmd 2;
BA_ "Match" SG_ 74 AutoAVMSwSet_Cmd "AutoAVMSwSet_Cmd";
BA_ "Origin" SG_ 74 AutoAVMSwSet_Cmd "fuel,ev";
BA_ "GenSigSendType" SG_ 74 FPAS_AutoModSwt 2;
BA_ "Match" SG_ 74 FPAS_AutoModSwt "FPAS_AutoModSwt";
BA_ "Origin" SG_ 74 FPAS_AutoModSwt "fuel,ev";
BA_ "GenSigSendType" SG_ 74 MEBSwtSet 2;
BA_ "Match" SG_ 74 MEBSwtSet "MEBSwtSet";
BA_ "Origin" SG_ 74 MEBSwtSet "fuel,ev";
BA_ "GenSigSendType" SG_ 74 WshSoftSwt 2;
BA_ "Match" SG_ 74 WshSoftSwt "WshSoftSwt";
BA_ "Origin" SG_ 74 WshSoftSwt "fuel,ev";
BA_ "GenSigSendType" SG_ 74 View_SoftswitchCmd 2;
BA_ "Match" SG_ 74 View_SoftswitchCmd "View_SoftswitchCmd";
BA_ "Origin" SG_ 74 View_SoftswitchCmd "fuel,ev";
BA_ "GenSigSendType" SG_ 465 AntiDisIdnResp 2;
BA_ "Match" SG_ 465 AntiDisIdnResp "AntiDisIdnResp";
BA_ "Origin" SG_ 465 AntiDisIdnResp "fuel,ev";
BA_ "GenSigCycleTime" SG_ 288 IB_Warn 20;
BA_ "Match" SG_ 288 IB_Warn "IB_Warn";
BA_ "Origin" SG_ 288 IB_Warn "fuel,ev";
BA_ "GenSigCycleTime" SG_ 573 Checksum_IFC3 50;
BA_ "Match" SG_ 573 Checksum_IFC3 "Checksum_IFC3";
BA_ "Origin" SG_ 573 Checksum_IFC3 "fuel,ev";
BA_ "GenSigCycleTime" SG_ 573 LDWResp 50;
BA_ "Match" SG_ 573 LDWResp "LDWResp";
BA_ "Origin" SG_ 573 LDWResp "fuel,ev";
BA_ "GenSigCycleTime" SG_ 573 LKAResp 50;
BA_ "Match" SG_ 573 LKAResp "LKAResp";
BA_ "Origin" SG_ 573 LKAResp "fuel,ev";
BA_ "GenSigCycleTime" SG_ 573 LCKResp 50;
BA_ "Match" SG_ 573 LCKResp "LCKResp";
BA_ "Origin" SG_ 573 LCKResp "fuel,ev";
BA_ "GenSigCycleTime" SG_ 573 ELKResp 50;
BA_ "Match" SG_ 573 ELKResp "ELKResp";
BA_ "Origin" SG_ 573 ELKResp "fuel,ev";
BA_ "GenSigCycleTime" SG_ 573 LDW_LKA_Snvty 50;
BA_ "Match" SG_ 573 LDW_LKA_Snvty "LDW_LKA_Snvty";
BA_ "Origin" SG_ 573 LDW_LKA_Snvty "fuel,ev";
BA_ "GenSigCycleTime" SG_ 573 IFCHUTInterface 50;
BA_ "Match" SG_ 573 IFCHUTInterface "IFCHUTInterface";
BA_ "Origin" SG_ 573 IFCHUTInterface "fuel,ev";
BA_ "GenSigCycleTime" SG_ 573 LSSWarnFormResp 50;
BA_ "Match" SG_ 573 LSSWarnFormResp "LSSWarnFormResp";
BA_ "Origin" SG_ 573 LSSWarnFormResp "fuel,ev";
BA_ "GenSigCycleTime" SG_ 573 LSSResp 50;
BA_ "Match" SG_ 573 LSSResp "LSSResp";
BA_ "Origin" SG_ 573 LSSResp "fuel,ev";
BA_ "GenSigCycleTime" SG_ 573 AESSts 50;
BA_ "Match" SG_ 573 AESSts "AESSts";
BA_ "Origin" SG_ 573 AESSts "fuel,ev";
BA_ "GenSigCycleTime" SG_ 573 ESSSts 50;
BA_ "Match" SG_ 573 ESSSts "ESSSts";
BA_ "Origin" SG_ 573 ESSSts "fuel,ev";
BA_ "GenSigCycleTime" SG_ 573 AESErrSts 50;
BA_ "Match" SG_ 573 AESErrSts "AESErrSts";
BA_ "Origin" SG_ 573 AESErrSts "fuel,ev";
BA_ "GenSigCycleTime" SG_ 573 ESSErrSts 50;
BA_ "Match" SG_ 573 ESSErrSts "ESSErrSts";
BA_ "Origin" SG_ 573 ESSErrSts "fuel,ev";
BA_ "GenSigCycleTime" SG_ 573 RollingCounter_IFC3 50;
BA_ "Match" SG_ 573 RollingCounter_IFC3 "RollingCounter_IFC3";
BA_ "Origin" SG_ 573 RollingCounter_IFC3 "fuel,ev";
BA_ "GenSigCycleTime" SG_ 573 Checksum_IFC4 50;
BA_ "Match" SG_ 573 Checksum_IFC4 "Checksum_IFC4";
BA_ "Origin" SG_ 573 Checksum_IFC4 "fuel,ev";
BA_ "GenSigCycleTime" SG_ 573 IFC_Handsoffwarn 50;
BA_ "Match" SG_ 573 IFC_Handsoffwarn "IFC_Handsoffwarn";
BA_ "Origin" SG_ 573 IFC_Handsoffwarn "fuel,ev";
BA_ "GenSigCycleTime" SG_ 573 IFCCalibrationSts 50;
BA_ "Match" SG_ 573 IFCCalibrationSts "IFCCalibrationSts";
BA_ "Origin" SG_ 573 IFCCalibrationSts "fuel,ev";
BA_ "GenSigCycleTime" SG_ 573 CameraBlockageSts 50;
BA_ "Match" SG_ 573 CameraBlockageSts "CameraBlockageSts";
BA_ "Origin" SG_ 573 CameraBlockageSts "fuel,ev";
BA_ "GenSigCycleTime" SG_ 573 LDW_LKAWarn 50;
BA_ "Match" SG_ 573 LDW_LKAWarn "LDW_LKAWarn";
BA_ "Origin" SG_ 573 LDW_LKAWarn "fuel,ev";
BA_ "GenSigCycleTime" SG_ 573 LSSIntervention 50;
BA_ "Match" SG_ 573 LSSIntervention "LSSIntervention";
BA_ "Origin" SG_ 573 LSSIntervention "fuel,ev";
BA_ "GenSigCycleTime" SG_ 573 LSSFuncSts 50;
BA_ "Match" SG_ 573 LSSFuncSts "LSSFuncSts";
BA_ "Origin" SG_ 573 LSSFuncSts "fuel,ev";
BA_ "GenSigCycleTime" SG_ 573 ELKMainState 50;
BA_ "Match" SG_ 573 ELKMainState "ELKMainState";
BA_ "Origin" SG_ 573 ELKMainState "fuel,ev";
BA_ "GenSigCycleTime" SG_ 573 LaneAvailability 50;
BA_ "Match" SG_ 573 LaneAvailability "LaneAvailability";
BA_ "Origin" SG_ 573 LaneAvailability "fuel,ev";
BA_ "GenSigCycleTime" SG_ 573 TJA_FollowSts 50;
BA_ "Match" SG_ 573 TJA_FollowSts "TJA_FollowSts";
BA_ "Origin" SG_ 573 TJA_FollowSts "fuel,ev";
BA_ "GenSigCycleTime" SG_ 573 LSSErrSts 50;
BA_ "Match" SG_ 573 LSSErrSts "LSSErrSts";
BA_ "Origin" SG_ 573 LSSErrSts "fuel,ev";
BA_ "GenSigCycleTime" SG_ 573 AESintervention 50;
BA_ "Match" SG_ 573 AESintervention "AESintervention";
BA_ "Origin" SG_ 573 AESintervention "fuel,ev";
BA_ "GenSigCycleTime" SG_ 573 ESSintervention 50;
BA_ "Match" SG_ 573 ESSintervention "ESSintervention";
BA_ "Origin" SG_ 573 ESSintervention "fuel,ev";
BA_ "GenSigCycleTime" SG_ 573 ELKActSts 50;
BA_ "Match" SG_ 573 ELKActSts "ELKActSts";
BA_ "Origin" SG_ 573 ELKActSts "fuel,ev";
BA_ "GenSigCycleTime" SG_ 573 IntelligentEvaActSts 50;
BA_ "Match" SG_ 573 IntelligentEvaActSts "IntelligentEvaActSts";
BA_ "Origin" SG_ 573 IntelligentEvaActSts "fuel,ev";
BA_ "GenSigCycleTime" SG_ 573 LCKStsIndcr 50;
BA_ "Match" SG_ 573 LCKStsIndcr "LCKStsIndcr";
BA_ "Origin" SG_ 573 LCKStsIndcr "fuel,ev";
BA_ "GenSigCycleTime" SG_ 573 RollingCounter_IFC4 50;
BA_ "Match" SG_ 573 RollingCounter_IFC4 "RollingCounter_IFC4";
BA_ "Origin" SG_ 573 RollingCounter_IFC4 "fuel,ev";
BA_ "GenSigCycleTime" SG_ 573 Checksum_IFC5 50;
BA_ "Match" SG_ 573 Checksum_IFC5 "Checksum_IFC5";
BA_ "Origin" SG_ 573 Checksum_IFC5 "fuel,ev";
BA_ "GenSigCycleTime" SG_ 573 IFC_LaneCurve 50;
BA_ "GenSigStartValue" SG_ 573 IFC_LaneCurve 2047;
BA_ "Match" SG_ 573 IFC_LaneCurve "IFC_LaneCurve";
BA_ "Origin" SG_ 573 IFC_LaneCurve "fuel,ev";
BA_ "GenSigCycleTime" SG_ 573 IFC_LeLaneTyp 50;
BA_ "Match" SG_ 573 IFC_LeLaneTyp "IFC_LeLaneTyp";
BA_ "Origin" SG_ 573 IFC_LeLaneTyp "fuel,ev";
BA_ "GenSigCycleTime" SG_ 573 IFC_RiLaneTyp 50;
BA_ "Match" SG_ 573 IFC_RiLaneTyp "IFC_RiLaneTyp";
BA_ "Origin" SG_ 573 IFC_RiLaneTyp "fuel,ev";
BA_ "GenSigCycleTime" SG_ 573 IFC_NextLeLaneTyp 50;
BA_ "Match" SG_ 573 IFC_NextLeLaneTyp "IFC_NextLeLaneTyp";
BA_ "Origin" SG_ 573 IFC_NextLeLaneTyp "fuel,ev";
BA_ "GenSigCycleTime" SG_ 573 IFC_NextRiLaneTyp 50;
BA_ "Match" SG_ 573 IFC_NextRiLaneTyp "IFC_NextRiLaneTyp";
BA_ "Origin" SG_ 573 IFC_NextRiLaneTyp "fuel,ev";
BA_ "GenSigCycleTime" SG_ 573 IFC_LeLane_dy 50;
BA_ "GenSigStartValue" SG_ 573 IFC_LeLane_dy 2496;
BA_ "Match" SG_ 573 IFC_LeLane_dy "IFC_LeLane_dy";
BA_ "Origin" SG_ 573 IFC_LeLane_dy "fuel,ev";
BA_ "GenSigCycleTime" SG_ 573 IFC_RiLane_dy 50;
BA_ "GenSigStartValue" SG_ 573 IFC_RiLane_dy 2496;
BA_ "Match" SG_ 573 IFC_RiLane_dy "IFC_RiLane_dy";
BA_ "Origin" SG_ 573 IFC_RiLane_dy "fuel,ev";
BA_ "GenSigCycleTime" SG_ 573 RollingCounter_IFC5 50;
BA_ "Match" SG_ 573 RollingCounter_IFC5 "RollingCounter_IFC5";
BA_ "Origin" SG_ 573 RollingCounter_IFC5 "fuel,ev";
BA_ "GenSigCycleTime" SG_ 573 Checksum_IFC6 50;
BA_ "Match" SG_ 573 Checksum_IFC6 "Checksum_IFC6";
BA_ "Origin" SG_ 573 Checksum_IFC6 "fuel,ev";
BA_ "GenSigCycleTime" SG_ 573 IFC_NextLeLane_dy 50;
BA_ "GenSigStartValue" SG_ 573 IFC_NextLeLane_dy 2496;
BA_ "Match" SG_ 573 IFC_NextLeLane_dy "IFC_NextLeLane_dy";
BA_ "Origin" SG_ 573 IFC_NextLeLane_dy "fuel,ev";
BA_ "GenSigCycleTime" SG_ 573 IFC_NextRiLane_dy 50;
BA_ "GenSigStartValue" SG_ 573 IFC_NextRiLane_dy 2496;
BA_ "Match" SG_ 573 IFC_NextRiLane_dy "IFC_NextRiLane_dy";
BA_ "Origin" SG_ 573 IFC_NextRiLane_dy "fuel,ev";
BA_ "GenSigCycleTime" SG_ 573 RollingCounter_IFC6 50;
BA_ "Match" SG_ 573 RollingCounter_IFC6 "RollingCounter_IFC6";
BA_ "Origin" SG_ 573 RollingCounter_IFC6 "fuel,ev";
BA_ "GenSigCycleTime" SG_ 573 AESResp 50;
BA_ "Match" SG_ 573 AESResp "AESResp";
BA_ "Origin" SG_ 573 AESResp "fuel,ev";
BA_ "GenSigCycleTime" SG_ 573 ESS_Pedresp 50;
BA_ "Match" SG_ 573 ESS_Pedresp "ESS_Pedresp";
BA_ "Origin" SG_ 573 ESS_Pedresp "fuel,ev";
BA_ "GenSigCycleTime" SG_ 573 ESS_Vehresp 50;
BA_ "Match" SG_ 573 ESS_Vehresp "ESS_Vehresp";
BA_ "Origin" SG_ 573 ESS_Vehresp "fuel,ev";
BA_ "GenSigCycleTime" SG_ 573 IntelligentEvaResp 50;
BA_ "Match" SG_ 573 IntelligentEvaResp "IntelligentEvaResp";
BA_ "Origin" SG_ 573 IntelligentEvaResp "fuel,ev";
BA_ "GenSigCycleTime" SG_ 573 FreshnessValue_IFC_FD2 50;
BA_ "Match" SG_ 573 FreshnessValue_IFC_FD2 "FreshnessValue_IFC_FD2";
BA_ "Origin" SG_ 573 FreshnessValue_IFC_FD2 "fuel,ev";
BA_ "GenSigCycleTime" SG_ 573 MAC_Check_IFC_FD2 50;
BA_ "Match" SG_ 573 MAC_Check_IFC_FD2 "MAC_Check_IFC_FD2";
BA_ "Origin" SG_ 573 MAC_Check_IFC_FD2 "fuel,ev";
BA_ "GenSigCycleTime" SG_ 719 TSRResp 100;
BA_ "Match" SG_ 719 TSRResp "TSRResp";
BA_ "Origin" SG_ 719 TSRResp "fuel,ev";
BA_ "GenSigCycleTime" SG_ 719 TSRSpdLimUnit 100;
BA_ "GenSigStartValue" SG_ 719 TSRSpdLimUnit 1;
BA_ "Match" SG_ 719 TSRSpdLimUnit "TSRSpdLimUnit";
BA_ "Origin" SG_ 719 TSRSpdLimUnit "fuel,ev";
BA_ "GenSigCycleTime" SG_ 719 TSRSpdLim 100;
BA_ "Match" SG_ 719 TSRSpdLim "TSRSpdLim";
BA_ "Origin" SG_ 719 TSRSpdLim "fuel,ev";
BA_ "GenSigCycleTime" SG_ 719 TSRSpdLimCfdc 100;
BA_ "Match" SG_ 719 TSRSpdLimCfdc "TSRSpdLimCfdc";
BA_ "Origin" SG_ 719 TSRSpdLimCfdc "fuel,ev";
BA_ "GenSigCycleTime" SG_ 719 TSRSts 100;
BA_ "Match" SG_ 719 TSRSts "TSRSts";
BA_ "Origin" SG_ 719 TSRSts "fuel,ev";
BA_ "GenSigCycleTime" SG_ 719 TSRSpdLimSts 100;
BA_ "Match" SG_ 719 TSRSpdLimSts "TSRSpdLimSts";
BA_ "Origin" SG_ 719 TSRSpdLimSts "fuel,ev";
BA_ "GenSigCycleTime" SG_ 719 TSRTrfcSignValCfdc 100;
BA_ "Match" SG_ 719 TSRTrfcSignValCfdc "TSRTrfcSignValCfdc";
BA_ "Origin" SG_ 719 TSRTrfcSignValCfdc "fuel,ev";
BA_ "GenSigCycleTime" SG_ 719 TSRTrfcSignVal 100;
BA_ "Match" SG_ 719 TSRTrfcSignVal "TSRTrfcSignVal";
BA_ "Origin" SG_ 719 TSRTrfcSignVal "fuel,ev";
BA_ "GenSigCycleTime" SG_ 719 TSRSpdLimWarn 100;
BA_ "Match" SG_ 719 TSRSpdLimWarn "TSRSpdLimWarn";
BA_ "Origin" SG_ 719 TSRSpdLimWarn "fuel,ev";
BA_ "GenSigCycleTime" SG_ 719 TSRWarnResp 100;
BA_ "Match" SG_ 719 TSRWarnResp "TSRWarnResp";
BA_ "Origin" SG_ 719 TSRWarnResp "fuel,ev";
BA_ "GenSigCycleTime" SG_ 719 TSR_Snvty 100;
BA_ "GenSigStartValue" SG_ 719 TSR_Snvty 15;
BA_ "Match" SG_ 719 TSR_Snvty "TSR_Snvty";
BA_ "Origin" SG_ 719 TSR_Snvty "fuel,ev";
BA_ "GenSigCycleTime" SG_ 719 IDC_L2_TurnLightReq 100;
BA_ "Match" SG_ 719 IDC_L2_TurnLightReq "IDC_L2_TurnLightReq";
BA_ "Origin" SG_ 719 IDC_L2_TurnLightReq "fuel,ev";
BA_ "GenSigCycleTime" SG_ 719 HWA_ALC_Trig 100;
BA_ "Match" SG_ 719 HWA_ALC_Trig "HWA_ALC_Trig";
BA_ "Origin" SG_ 719 HWA_ALC_Trig "fuel,ev";
BA_ "GenSigCycleTime" SG_ 719 HWA_WarnInfoDisp 100;
BA_ "Match" SG_ 719 HWA_WarnInfoDisp "HWA_WarnInfoDisp";
BA_ "Origin" SG_ 719 HWA_WarnInfoDisp "fuel,ev";
BA_ "GenSigCycleTime" SG_ 719 HWA_TakOver_Trig 100;
BA_ "Match" SG_ 719 HWA_TakOver_Trig "HWA_TakOver_Trig";
BA_ "Origin" SG_ 719 HWA_TakOver_Trig "fuel,ev";
BA_ "GenSigCycleTime" SG_ 719 HWA_TakOver_Req 100;
BA_ "Match" SG_ 719 HWA_TakOver_Req "HWA_TakOver_Req";
BA_ "Origin" SG_ 719 HWA_TakOver_Req "fuel,ev";
BA_ "GenSigCycleTime" SG_ 719 MRC_InterSysInfoDisp 100;
BA_ "Match" SG_ 719 MRC_InterSysInfoDisp "MRC_InterSysInfoDisp";
BA_ "Origin" SG_ 719 MRC_InterSysInfoDisp "fuel,ev";
BA_ "GenSigCycleTime" SG_ 719 MRC_TakOver_Req 100;
BA_ "Match" SG_ 719 MRC_TakOver_Req "MRC_TakOver_Req";
BA_ "Origin" SG_ 719 MRC_TakOver_Req "fuel,ev";
BA_ "GenSigCycleTime" SG_ 719 NOH_WarnInfoDisp 100;
BA_ "Match" SG_ 719 NOH_WarnInfoDisp "NOH_WarnInfoDisp";
BA_ "Origin" SG_ 719 NOH_WarnInfoDisp "fuel,ev";
BA_ "GenSigCycleTime" SG_ 719 IFC_Line01_Source 100;
BA_ "Match" SG_ 719 IFC_Line01_Source "IFC_Line01_Source";
BA_ "Origin" SG_ 719 IFC_Line01_Source "fuel,ev";
BA_ "GenSigCycleTime" SG_ 719 IFC_Line02_Source 100;
BA_ "Match" SG_ 719 IFC_Line02_Source "IFC_Line02_Source";
BA_ "Origin" SG_ 719 IFC_Line02_Source "fuel,ev";
BA_ "GenSigCycleTime" SG_ 719 TSR_Traffic_Light_Posn 100;
BA_ "Match" SG_ 719 TSR_Traffic_Light_Posn "TSR_Traffic_Light_Posn";
BA_ "Origin" SG_ 719 TSR_Traffic_Light_Posn "fuel,ev";
BA_ "GenSigCycleTime" SG_ 719 Stop_Mark_Detn 100;
BA_ "Match" SG_ 719 Stop_Mark_Detn "Stop_Mark_Detn";
BA_ "Origin" SG_ 719 Stop_Mark_Detn "fuel,ev";
BA_ "GenSigCycleTime" SG_ 719 Stop_Mark_Dx 100;
BA_ "Match" SG_ 719 Stop_Mark_Dx "Stop_Mark_Dx";
BA_ "Origin" SG_ 719 Stop_Mark_Dx "fuel,ev";
BA_ "GenSigCycleTime" SG_ 719 Zebra_Mark_Detn 100;
BA_ "Match" SG_ 719 Zebra_Mark_Detn "Zebra_Mark_Detn";
BA_ "Origin" SG_ 719 Zebra_Mark_Detn "fuel,ev";
BA_ "GenSigCycleTime" SG_ 719 Grid_Mark_Detn 100;
BA_ "Match" SG_ 719 Grid_Mark_Detn "Grid_Mark_Detn";
BA_ "Origin" SG_ 719 Grid_Mark_Detn "fuel,ev";
BA_ "GenSigCycleTime" SG_ 719 HWA_InhibitWarn 100;
BA_ "Match" SG_ 719 HWA_InhibitWarn "HWA_InhibitWarn";
BA_ "Origin" SG_ 719 HWA_InhibitWarn "fuel,ev";
BA_ "GenSigCycleTime" SG_ 719 LaneChngCfmSwt_Resp 100;
BA_ "Match" SG_ 719 LaneChngCfmSwt_Resp "LaneChngCfmSwt_Resp";
BA_ "Origin" SG_ 719 LaneChngCfmSwt_Resp "fuel,ev";
BA_ "GenSigCycleTime" SG_ 719 ALC_SwtReq_Resp 100;
BA_ "Match" SG_ 719 ALC_SwtReq_Resp "ALC_SwtReq_Resp";
BA_ "Origin" SG_ 719 ALC_SwtReq_Resp "fuel,ev";
BA_ "GenSigCycleTime" SG_ 719 AutoSpdSetSwt_Resp 100;
BA_ "Match" SG_ 719 AutoSpdSetSwt_Resp "AutoSpdSetSwt_Resp";
BA_ "Origin" SG_ 719 AutoSpdSetSwt_Resp "fuel,ev";
BA_ "GenSigCycleTime" SG_ 719 VoiceBrdcSwt_Resp 100;
BA_ "Match" SG_ 719 VoiceBrdcSwt_Resp "VoiceBrdcSwt_Resp";
BA_ "Origin" SG_ 719 VoiceBrdcSwt_Resp "fuel,ev";
BA_ "GenSigCycleTime" SG_ 719 UsrManSts_Resp 100;
BA_ "Match" SG_ 719 UsrManSts_Resp "UsrManSts_Resp";
BA_ "Origin" SG_ 719 UsrManSts_Resp "fuel,ev";
BA_ "GenSigCycleTime" SG_ 719 Grid_Mark_Dx 100;
BA_ "Match" SG_ 719 Grid_Mark_Dx "Grid_Mark_Dx";
BA_ "Origin" SG_ 719 Grid_Mark_Dx "fuel,ev";
BA_ "GenSigCycleTime" SG_ 719 Zebra_Mark_Dx 100;
BA_ "Match" SG_ 719 Zebra_Mark_Dx "Zebra_Mark_Dx";
BA_ "Origin" SG_ 719 Zebra_Mark_Dx "fuel,ev";
BA_ "GenSigCycleTime" SG_ 719 TSR_Traffic_Light 100;
BA_ "Match" SG_ 719 TSR_Traffic_Light "TSR_Traffic_Light";
BA_ "Origin" SG_ 719 TSR_Traffic_Light "fuel,ev";
BA_ "GenSigCycleTime" SG_ 719 TSR_Traffic_Light_Through 100;
BA_ "Match" SG_ 719 TSR_Traffic_Light_Through "TSR_Traffic_Light_Through";
BA_ "Origin" SG_ 719 TSR_Traffic_Light_Through "fuel,ev";
BA_ "GenSigCycleTime" SG_ 719 TSR_Traffic_Light_Le 100;
BA_ "Match" SG_ 719 TSR_Traffic_Light_Le "TSR_Traffic_Light_Le";
BA_ "Origin" SG_ 719 TSR_Traffic_Light_Le "fuel,ev";
BA_ "GenSigCycleTime" SG_ 719 TSR_Traffic_Light_Ri 100;
BA_ "Match" SG_ 719 TSR_Traffic_Light_Ri "TSR_Traffic_Light_Ri";
BA_ "Origin" SG_ 719 TSR_Traffic_Light_Ri "fuel,ev";
BA_ "GenSigCycleTime" SG_ 719 RainMode_Swt_Resp 100;
BA_ "Match" SG_ 719 RainMode_Swt_Resp "RainMode_Swt_Resp";
BA_ "Origin" SG_ 719 RainMode_Swt_Resp "fuel,ev";
BA_ "GenSigCycleTime" SG_ 719 LCMode_Swt_Resp 100;
BA_ "Match" SG_ 719 LCMode_Swt_Resp "LCMode_Swt_Resp";
BA_ "Origin" SG_ 719 LCMode_Swt_Resp "fuel,ev";
BA_ "GenSigCycleTime" SG_ 719 NavDecSwtResp 100;
BA_ "Match" SG_ 719 NavDecSwtResp "NavDecSwtResp";
BA_ "Origin" SG_ 719 NavDecSwtResp "fuel,ev";
BA_ "GenSigCycleTime" SG_ 415 IFC_Line01_Dy 50;
BA_ "GenSigStartValue" SG_ 415 IFC_Line01_Dy 2825;
BA_ "Match" SG_ 415 IFC_Line01_Dy "IFC_Line01_Dy";
BA_ "Origin" SG_ 415 IFC_Line01_Dy "fuel,ev";
BA_ "GenSigCycleTime" SG_ 415 IFC_Line01_Curv 50;
BA_ "GenSigStartValue" SG_ 415 IFC_Line01_Curv 15625;
BA_ "Match" SG_ 415 IFC_Line01_Curv "IFC_Line01_Curv";
BA_ "Origin" SG_ 415 IFC_Line01_Curv "fuel,ev";
BA_ "GenSigCycleTime" SG_ 415 IFC_Line01_CurvChange 50;
BA_ "GenSigStartValue" SG_ 415 IFC_Line01_CurvChange 480000;
BA_ "Match" SG_ 415 IFC_Line01_CurvChange "IFC_Line01_CurvChange";
BA_ "Origin" SG_ 415 IFC_Line01_CurvChange "fuel,ev";
BA_ "GenSigCycleTime" SG_ 415 IFC_Line01_Type 50;
BA_ "Match" SG_ 415 IFC_Line01_Type "IFC_Line01_Type";
BA_ "Origin" SG_ 415 IFC_Line01_Type "fuel,ev";
BA_ "GenSigCycleTime" SG_ 415 IFC_Line02_Dy 50;
BA_ "GenSigStartValue" SG_ 415 IFC_Line02_Dy 2825;
BA_ "Match" SG_ 415 IFC_Line02_Dy "IFC_Line02_Dy";
BA_ "Origin" SG_ 415 IFC_Line02_Dy "fuel,ev";
BA_ "GenSigCycleTime" SG_ 415 IFC_Line02_Curv 50;
BA_ "GenSigStartValue" SG_ 415 IFC_Line02_Curv 15625;
BA_ "Match" SG_ 415 IFC_Line02_Curv "IFC_Line02_Curv";
BA_ "Origin" SG_ 415 IFC_Line02_Curv "fuel,ev";
BA_ "GenSigCycleTime" SG_ 415 IFC_Line02_CurvChange 50;
BA_ "GenSigStartValue" SG_ 415 IFC_Line02_CurvChange 480000;
BA_ "Match" SG_ 415 IFC_Line02_CurvChange "IFC_Line02_CurvChange";
BA_ "Origin" SG_ 415 IFC_Line02_CurvChange "fuel,ev";
BA_ "GenSigCycleTime" SG_ 415 IFC_Line02_Type 50;
BA_ "Match" SG_ 415 IFC_Line02_Type "IFC_Line02_Type";
BA_ "Origin" SG_ 415 IFC_Line02_Type "fuel,ev";
BA_ "GenSigCycleTime" SG_ 415 IFC_Line03_Dy 50;
BA_ "GenSigStartValue" SG_ 415 IFC_Line03_Dy 2825;
BA_ "Match" SG_ 415 IFC_Line03_Dy "IFC_Line03_Dy";
BA_ "Origin" SG_ 415 IFC_Line03_Dy "fuel,ev";
BA_ "GenSigCycleTime" SG_ 415 IFC_Line03_Curv 50;
BA_ "GenSigStartValue" SG_ 415 IFC_Line03_Curv 15625;
BA_ "Match" SG_ 415 IFC_Line03_Curv "IFC_Line03_Curv";
BA_ "Origin" SG_ 415 IFC_Line03_Curv "fuel,ev";
BA_ "GenSigCycleTime" SG_ 415 IFC_Line03_CurvChange 50;
BA_ "GenSigStartValue" SG_ 415 IFC_Line03_CurvChange 480000;
BA_ "Match" SG_ 415 IFC_Line03_CurvChange "IFC_Line03_CurvChange";
BA_ "Origin" SG_ 415 IFC_Line03_CurvChange "fuel,ev";
BA_ "GenSigCycleTime" SG_ 415 IFC_Line03_Type 50;
BA_ "Match" SG_ 415 IFC_Line03_Type "IFC_Line03_Type";
BA_ "Origin" SG_ 415 IFC_Line03_Type "fuel,ev";
BA_ "GenSigCycleTime" SG_ 415 IFC_Line04_Dy 50;
BA_ "GenSigStartValue" SG_ 415 IFC_Line04_Dy 2825;
BA_ "Match" SG_ 415 IFC_Line04_Dy "IFC_Line04_Dy";
BA_ "Origin" SG_ 415 IFC_Line04_Dy "fuel,ev";
BA_ "GenSigCycleTime" SG_ 415 IFC_Line04_Curv 50;
BA_ "GenSigStartValue" SG_ 415 IFC_Line04_Curv 15625;
BA_ "Match" SG_ 415 IFC_Line04_Curv "IFC_Line04_Curv";
BA_ "Origin" SG_ 415 IFC_Line04_Curv "fuel,ev";
BA_ "GenSigCycleTime" SG_ 415 IFC_Line04_CurvChange 50;
BA_ "GenSigStartValue" SG_ 415 IFC_Line04_CurvChange 480000;
BA_ "Match" SG_ 415 IFC_Line04_CurvChange "IFC_Line04_CurvChange";
BA_ "Origin" SG_ 415 IFC_Line04_CurvChange "fuel,ev";
BA_ "GenSigCycleTime" SG_ 415 IFC_Line04_Type 50;
BA_ "Match" SG_ 415 IFC_Line04_Type "IFC_Line04_Type";
BA_ "Origin" SG_ 415 IFC_Line04_Type "fuel,ev";
BA_ "GenSigCycleTime" SG_ 415 IFC_Roadedge01_Dy 50;
BA_ "GenSigStartValue" SG_ 415 IFC_Roadedge01_Dy 2825;
BA_ "Match" SG_ 415 IFC_Roadedge01_Dy "IFC_Roadedge01_Dy";
BA_ "Origin" SG_ 415 IFC_Roadedge01_Dy "fuel,ev";
BA_ "GenSigCycleTime" SG_ 415 IFC_Roadedge01_Curv 50;
BA_ "GenSigStartValue" SG_ 415 IFC_Roadedge01_Curv 15625;
BA_ "Match" SG_ 415 IFC_Roadedge01_Curv "IFC_Roadedge01_Curv";
BA_ "Origin" SG_ 415 IFC_Roadedge01_Curv "fuel,ev";
BA_ "GenSigCycleTime" SG_ 415 IFC_Roadedge01_CurvChange 50;
BA_ "GenSigStartValue" SG_ 415 IFC_Roadedge01_CurvChange 480000;
BA_ "Match" SG_ 415 IFC_Roadedge01_CurvChange "IFC_Roadedge01_CurvChange";
BA_ "Origin" SG_ 415 IFC_Roadedge01_CurvChange "fuel,ev";
BA_ "GenSigCycleTime" SG_ 415 IFC_Roadedge01_Type 50;
BA_ "Match" SG_ 415 IFC_Roadedge01_Type "IFC_Roadedge01_Type";
BA_ "Origin" SG_ 415 IFC_Roadedge01_Type "fuel,ev";
BA_ "GenSigCycleTime" SG_ 415 IFC_Roadedge02_Dy 50;
BA_ "GenSigStartValue" SG_ 415 IFC_Roadedge02_Dy 2825;
BA_ "Match" SG_ 415 IFC_Roadedge02_Dy "IFC_Roadedge02_Dy";
BA_ "Origin" SG_ 415 IFC_Roadedge02_Dy "fuel,ev";
BA_ "GenSigCycleTime" SG_ 415 IFC_Roadedge02_Curv 50;
BA_ "GenSigStartValue" SG_ 415 IFC_Roadedge02_Curv 15625;
BA_ "Match" SG_ 415 IFC_Roadedge02_Curv "IFC_Roadedge02_Curv";
BA_ "Origin" SG_ 415 IFC_Roadedge02_Curv "fuel,ev";
BA_ "GenSigCycleTime" SG_ 415 IFC_Roadedge02_CurvChange 50;
BA_ "GenSigStartValue" SG_ 415 IFC_Roadedge02_CurvChange 480000;
BA_ "Match" SG_ 415 IFC_Roadedge02_CurvChange "IFC_Roadedge02_CurvChange";
BA_ "Origin" SG_ 415 IFC_Roadedge02_CurvChange "fuel,ev";
BA_ "GenSigCycleTime" SG_ 415 IFC_Roadedge02_Type 50;
BA_ "Match" SG_ 415 IFC_Roadedge02_Type "IFC_Roadedge02_Type";
BA_ "Origin" SG_ 415 IFC_Roadedge02_Type "fuel,ev";
BA_ "GenSigCycleTime" SG_ 546 IFC_Line01_DxStart 50;
BA_ "Match" SG_ 546 IFC_Line01_DxStart "IFC_Line01_DxStart";
BA_ "Origin" SG_ 546 IFC_Line01_DxStart "fuel,ev";
BA_ "GenSigCycleTime" SG_ 546 IFC_Line01_DxEnd 50;
BA_ "Match" SG_ 546 IFC_Line01_DxEnd "IFC_Line01_DxEnd";
BA_ "Origin" SG_ 546 IFC_Line01_DxEnd "fuel,ev";
BA_ "GenSigCycleTime" SG_ 546 IFC_Line01_HeadingAngle 50;
BA_ "GenSigStartValue" SG_ 546 IFC_Line01_HeadingAngle 201;
BA_ "Match" SG_ 546 IFC_Line01_HeadingAngle "IFC_Line01_HeadingAngle";
BA_ "Origin" SG_ 546 IFC_Line01_HeadingAngle "fuel,ev";
BA_ "GenSigCycleTime" SG_ 546 IFC_Line02_HeadingAngle 50;
BA_ "GenSigStartValue" SG_ 546 IFC_Line02_HeadingAngle 201;
BA_ "Match" SG_ 546 IFC_Line02_HeadingAngle "IFC_Line02_HeadingAngle";
BA_ "Origin" SG_ 546 IFC_Line02_HeadingAngle "fuel,ev";
BA_ "GenSigCycleTime" SG_ 546 IFC_Line02_DxStart 50;
BA_ "Match" SG_ 546 IFC_Line02_DxStart "IFC_Line02_DxStart";
BA_ "Origin" SG_ 546 IFC_Line02_DxStart "fuel,ev";
BA_ "GenSigCycleTime" SG_ 546 IFC_Line02_DxEnd 50;
BA_ "Match" SG_ 546 IFC_Line02_DxEnd "IFC_Line02_DxEnd";
BA_ "Origin" SG_ 546 IFC_Line02_DxEnd "fuel,ev";
BA_ "GenSigCycleTime" SG_ 546 IFC_Line03_DxStart 50;
BA_ "Match" SG_ 546 IFC_Line03_DxStart "IFC_Line03_DxStart";
BA_ "Origin" SG_ 546 IFC_Line03_DxStart "fuel,ev";
BA_ "GenSigCycleTime" SG_ 546 IFC_Line03_DxEnd 50;
BA_ "Match" SG_ 546 IFC_Line03_DxEnd "IFC_Line03_DxEnd";
BA_ "Origin" SG_ 546 IFC_Line03_DxEnd "fuel,ev";
BA_ "GenSigCycleTime" SG_ 546 IFC_Line03_HeadingAngle 50;
BA_ "GenSigStartValue" SG_ 546 IFC_Line03_HeadingAngle 201;
BA_ "Match" SG_ 546 IFC_Line03_HeadingAngle "IFC_Line03_HeadingAngle";
BA_ "Origin" SG_ 546 IFC_Line03_HeadingAngle "fuel,ev";
BA_ "GenSigCycleTime" SG_ 546 IFC_Line04_DxStart 50;
BA_ "Match" SG_ 546 IFC_Line04_DxStart "IFC_Line04_DxStart";
BA_ "Origin" SG_ 546 IFC_Line04_DxStart "fuel,ev";
BA_ "GenSigCycleTime" SG_ 546 IFC_Line04_HeadingAngle 50;
BA_ "GenSigStartValue" SG_ 546 IFC_Line04_HeadingAngle 201;
BA_ "Match" SG_ 546 IFC_Line04_HeadingAngle "IFC_Line04_HeadingAngle";
BA_ "Origin" SG_ 546 IFC_Line04_HeadingAngle "fuel,ev";
BA_ "GenSigCycleTime" SG_ 546 IFC_Line04_DxEnd 50;
BA_ "Match" SG_ 546 IFC_Line04_DxEnd "IFC_Line04_DxEnd";
BA_ "Origin" SG_ 546 IFC_Line04_DxEnd "fuel,ev";
BA_ "GenSigCycleTime" SG_ 546 IFC_Roadedge01_DxStart 50;
BA_ "Match" SG_ 546 IFC_Roadedge01_DxStart "IFC_Roadedge01_DxStart";
BA_ "Origin" SG_ 546 IFC_Roadedge01_DxStart "fuel,ev";
BA_ "GenSigCycleTime" SG_ 546 IFC_Roadedge01_DxEnd 50;
BA_ "Match" SG_ 546 IFC_Roadedge01_DxEnd "IFC_Roadedge01_DxEnd";
BA_ "Origin" SG_ 546 IFC_Roadedge01_DxEnd "fuel,ev";
BA_ "GenSigCycleTime" SG_ 546 IFC_Roadedge01_HeadingAngle 50;
BA_ "GenSigStartValue" SG_ 546 IFC_Roadedge01_HeadingAngle 201;
BA_ "Match" SG_ 546 IFC_Roadedge01_HeadingAngle "IFC_Roadedge01_HeadingAngle";
BA_ "Origin" SG_ 546 IFC_Roadedge01_HeadingAngle "fuel,ev";
BA_ "GenSigCycleTime" SG_ 546 IFC_Roadedge02_DxStart 50;
BA_ "Match" SG_ 546 IFC_Roadedge02_DxStart "IFC_Roadedge02_DxStart";
BA_ "Origin" SG_ 546 IFC_Roadedge02_DxStart "fuel,ev";
BA_ "GenSigCycleTime" SG_ 546 IFC_Roadedge02_DxEnd 50;
BA_ "Match" SG_ 546 IFC_Roadedge02_DxEnd "IFC_Roadedge02_DxEnd";
BA_ "Origin" SG_ 546 IFC_Roadedge02_DxEnd "fuel,ev";
BA_ "GenSigCycleTime" SG_ 546 IFC_Roadedge02_HeadingAngle 50;
BA_ "GenSigStartValue" SG_ 546 IFC_Roadedge02_HeadingAngle 201;
BA_ "Match" SG_ 546 IFC_Roadedge02_HeadingAngle "IFC_Roadedge02_HeadingAngle";
BA_ "Origin" SG_ 546 IFC_Roadedge02_HeadingAngle "fuel,ev";
BA_ "GenSigCycleTime" SG_ 265 IFCTrqOvlCmdProtnValue 20;
BA_ "GenSigStartValue" SG_ 265 IFCTrqOvlCmdProtnValue 7169;
BA_ "Match" SG_ 265 IFCTrqOvlCmdProtnValue "IFCTrqOvlCmdProtnValue";
BA_ "Origin" SG_ 265 IFCTrqOvlCmdProtnValue "fuel,ev";
BA_ "GenSigCycleTime" SG_ 265 IFCTrqOvlCmdReqValue 20;
BA_ "GenSigStartValue" SG_ 265 IFCTrqOvlCmdReqValue 1023;
BA_ "Match" SG_ 265 IFCTrqOvlCmdReqValue "IFCTrqOvlCmdReqValue";
BA_ "Origin" SG_ 265 IFCTrqOvlCmdReqValue "fuel,ev";
VAL_ 728 ADAS_Stub_MsgTyp 0 "System Specific" 1 "Position" 2 "Segment" 3 "Stub" 4 "Profile Short" 5 "Profile Long" 6 "Meta-data" 7 "Reserved";
VAL_ 728 ADAS_Stub_Offset 0 "Valid data" 8190 "Valid data" 8191 "Invalid data";
VAL_ 728 ADAS_Stub_CycCnt 0 "Valid value" 3 "Valid value";
VAL_ 728 ADAS_Stub_PathIdx 0 "Valid value" 63 "Valid value";
VAL_ 728 ADAS_Stub_StubPathIdx 0 "Valid value" 63 "Valid value";
VAL_ 728 ADAS_Stub_Retr 0 "False" 1 "True";
VAL_ 728 ADAS_Stub_Update 0 "False" 1 "True";
VAL_ 728 ADAS_Stub_RelProbb 0 "unknown" 1 "Valid data" 30 "Valid data" 31 "Invalid";
VAL_ 728 ADAS_Stub_FuncRoadClass 0 "Unkown" 1 "Expressway" 2 "City expressway" 3 "National road" 4 "Provincial rode or County road" 5 "City or Village road" 6 "Other road" 7 "Invalid";
VAL_ 728 ADAS_Stub_PartOfCalcRoute 0 "New path from this point on is not part of Calculated Route" 1 "New path from this point on is part of Calculated Route" 2 "Unknown" 3 "invalid";
VAL_ 728 ADAS_Stub_CmplxInsct 0 "New path is not part of complex intersection" 1 "New path is part of a complex intersection" 2 "Unknown" 3 "invalid";
VAL_ 728 ADAS_Stub_FormOfWay 0 "Unkown" 1 "Freeway or Controlled Access road that is not a slip roadramp" 2 "Multiple Carriageway or Multiply Digitized Road" 3 "Single Carriageway (default)" 4 "Roundabout Circle" 5 "Traffic SquareSpecial Traffic Figure" 6 "Reserved" 7 "Reserved" 8 "Parallel Road (as special type of a slip roadramp)" 9 "Slip RoadRamp on a Freeway or Controlled Access road" 10 "Slip RoadRamp (not on a Freeway or Controlled Access road)" 11 "Service Road or Frontage Road" 12 "Entrance to or exit of a Car Park" 13 "Entrance to or exit to Service" 14 "Pedestrian Zone" 15 "Unknow";
VAL_ 728 ADAS_Stub_TurnAngl 0 "In path direction" 1 "1.417 degrees right" 2 "Right from path direction" 126 "178.583 degrees right" 127 "Opposite direction" 128 "178.583 degrees left (181.417 degrees right)" 129 "Left from path direction" 252 "Left from path direction" 253 "1.417 degrees left (358.583 degrees right)" 254 "Unknown" 255 "Invalid";
VAL_ 728 ADAS_Stub_LastStub 0 "False" 1 "True";
VAL_ 728 ADAS_Stub_RtOfWay 0 "Drvg towards this stub has priority over all conflicting vehicle movements" 1 "Drvg towards this stub might require yielding to conflicting vehicle movements" 2 "Unknown" 3 "Invalid";
VAL_ 728 ADAS_Stub_NumOfLaneOppDir 0 "one-direction road" 1 "one lane only" 2 "indicates 2 or more lanes" 3 "invalid";
VAL_ 728 ADAS_Stub_NumOfLaneDrvDir 0 "One-direction road driven in wrong direction" 1 "Verbatim values" 5 "Verbatim values" 6 "6 or more lanes" 7 "invalid";
VAL_ 825 HUT_RemtEngCtrl 0 "No action" 1 "Start" 2 "Stop" 3 "Invalid";
VAL_ 825 ACDrvSetTempReq_ETC_VR 0 "Initial value" 1 "Level 1(Low)_17(Hi)" 17 "Level 1(Low)_17(Hi)" 18 "Reserved" 31 "Reserved";
VAL_ 825 ACDrvSetTempSteplsReq_ETC_TC 0 "Initial value" 1 "Level 1(Low)_17(Hi)" 17 "Level 1(Low)_17(Hi)" 18 "Reserved" 31 "Reserved";
VAL_ 825 HUT_ChrgnMode 0 "Immediate Charging" 1 "Delay Charging" 2 "Invalid value" 3 "No action";
VAL_ 825 HUT_BattKeepTemp 0 "Default" 1 "ON" 2 "OFF" 3 "Reserved";
VAL_ 825 HUT_IntelEngIdlChrgnSet 0 "Default" 1 "ON" 2 "OFF" 3 "Reserved";
VAL_ 825 HUT_IntelBattTempMagSet 0 "Default" 1 "ON" 2 "OFF" 3 "Reserved";
VAL_ 825 HUT_BattSOCLim 0 "100%" 1 "50%" 2 "60%" 3 "70%" 4 "80%" 5 "90%" 6 "No action" 7 "Reserved";
VAL_ 694 PassSeatAdjmtSwt_HUT 0 "Seat_Swt_Idle" 1 "Seat_Swt_Slide_Fwd" 2 "Seat_Swt_Slide_Rwd" 3 "Seat_Swt_BckRst_Fwd" 4 "Seat_Swt_BckRst_Rwd" 5 "Seat_Swt_Height_F_up" 6 "Seat_Swt_Height_F_down" 7 "Seat_Swt_Height_R_up" 8 "Seat_Swt_Height_R_down" 9 "Reserved" 15 "Reserved";
VAL_ 694 SeatFlankAdjmtSwt_HUT 0 "Seat_Swt_Idle" 1 "Seat_Swt_BckRst_In" 2 "Seat_Swt_BckRst_Out" 3 "Seat_Swt_Sflank_In" 4 "Seat_Swt_Sflank_Out" 5 "Reserved" 7 "Reserved";
VAL_ 694 AVM_dispsts 0 "OFF" 1 "ON";
VAL_ 875 AMP_HFMVolSet 0 "HFM volume step 0-39" 39 "HFM volume step 0-39" 40 "Reserved" 62 "Reserved" 63 "Invalid Value";
VAL_ 875 AMP_TTSVolSet_VR 0 "VR_TTS volume step 0-39" 39 "VR_TTS volume step 0-39" 40 "Reserved" 62 "Reserved" 63 "Invalid Value";
VAL_ 875 AMP_NaviVolSet 0 "Navi volume step 0-39" 39 "Navi volume step 0-39" 40 "Reserved" 62 "Reserved" 63 "Invalid Value";
VAL_ 875 AMP_MainVolSet 0 "Main volume step 0-39" 39 "Main volume step 0-39" 40 "Reserved" 62 "Reserved" 63 "Invalid Value";
VAL_ 875 AMP_GetSWInfoReq 0 "No action" 1 "Get information";
VAL_ 875 AMP_GetHWInfoReq 0 "No action" 1 "Get information";
VAL_ 875 AMP_GetTempInfoReq 0 "No action" 1 "Get information";
VAL_ 875 AMP_GetIntVoltInfoReq 0 "No action" 1 "Get information";
VAL_ 875 AMP_GetDTCInfoReq 0 "No action" 1 "Get information";
VAL_ 875 IESS_MdlSwtReq 0 "OFF" 1 "Model 1" 2 "Model 2" 3 "Model 3";
VAL_ 875 IESS_MdlInfoReq 0 "No action" 1 "Get information";
VAL_ 875 AMP_BestListegPosnReq 0 "All Seat" 1 "Front Seat" 2 "Rear Seat" 3 "Driver Seat" 4 "Boss Seat" 5 "Children sleep Seat" 6 "reserved" 7 "reserved";
VAL_ 875 AMP_Clari_FiReq 0 "OFF" 1 "ON";
VAL_ 489 HUD_HeightLvlSwt 0 "No action" 1 "Level 1_Low" 2 "Level 2" 3 "Level 3" 4 "Level 4" 5 "Level 5" 6 "Level 6" 7 "Level 7" 8 "Level 8" 9 "Level 9" 10 "Level 10" 11 "Level 11_Middle" 12 "Level 12" 13 "Level 13" 14 "Level 14" 15 "Level 15" 16 "Level 16" 17 "Level 17" 18 "Level 18" 19 "Level 19" 20 "Level 20" 21 "Level 21_High" 22 "Reserved" 31 "Reserved";
VAL_ 489 HUD_BrightnessLvlSwt 0 "No action" 1 "Level 1_Low" 2 "Level 2" 3 "Level 3" 4 "Level 4" 5 "Level 5_Middle" 6 "Level 6" 7 "Level 7" 8 "Level 8" 9 "Level 9_High" 10 "Reserved" 15 "Reserved";
VAL_ 489 HUD_SwtReq 0 "No action" 1 "OFF" 2 "ON" 3 "Reserved";
VAL_ 489 BackReq_AVM 0 "No request" 1 "Request";
VAL_ 489 PPMIHWSwtSet 0 "No action" 1 "OFF" 2 "ON" 3 "Reserved";
VAL_ 489 PPMIBSRSwtSet 0 "No action" 1 "OFF" 2 "ON" 3 "Reserved";
VAL_ 489 PPMIHW_SwtSet 0 "No action" 1 "OFF" 2 "ON" 3 "Reserved";
VAL_ 489 PPMIBSR_SwtSet 0 "No action" 1 "OFF" 2 "ON" 3 "Reserved";
VAL_ 623 CheckSum_HUT32 0 "Valid value" 255 "Valid value";
VAL_ 623 ScrnOpSts 0 "Release" 1 "Pressed" 2 "Hold" 3 "Reserved";
VAL_ 623 XLvl 0 "Valid value" 2046 "Valid value" 2047 "Invalid";
VAL_ 623 YLvl 0 "Valid value" 2046 "Valid value" 2047 "Invalid";
VAL_ 623 DetVideoLost 0 "Nomal" 1 "Video lost";
VAL_ 623 PrkgCtrlModReqValid 0 "valid" 1 "invalid";
VAL_ 623 PrkgCtrlModReq 0 "No action" 1 "Parking in car" 2 "Remote parking" 3 "Reserved";
VAL_ 623 ContnPrkgReqValid 0 "valid" 1 "invalid";
VAL_ 623 ContnPrkgReq 2 "cancle parking" 3 "invalid";
VAL_ 623 PrkStraightSwtReq_HUT 0 "No request" 1 "Request";
VAL_ 623 PrkStraightSuspendOrFinishReq_HU 0 "No request" 1 "Request suspend" 2 "Request finish" 3 "Reserved";
VAL_ 623 PrkStraightModSel_HUT 0 "No select" 1 "Front vertical head park straight" 2 "Rear vertical tail park straight" 3 "Reserved";
VAL_ 623 PrkStraightSts_HUT 0 "No error" 1 "Error";
VAL_ 623 PrkStraightStrtReq_HUT 0 "No request" 1 "Request";
VAL_ 623 PrkStraightVehStrtReq_HUT_Valid 0 "Invalid" 1 "Valid";
VAL_ 623 PrkStraightContinueReq_HUT 0 "User not continue request" 1 "User continue request";
VAL_ 623 P2P_PrkgDirSwtReq 0 "No request" 1 "Request";
VAL_ 623 RainMode_Swt_Req 0 "OFF" 1 "ON";
VAL_ 623 LCMode_Swt_Req 0 "Normal" 1 "Sport" 2 "Comfort" 3 "Reserve";
VAL_ 623 NavDecSwtReq 0 "OFF" 1 "ON";
VAL_ 623 RollingCounter_HUT32 0 "Valid value" 14 "Valid value" 15 "Invalid value";
VAL_ 493 FlaoutUnlockSet 0 "No action" 1 "OFF" 2 "ON" 3 "Reserved";
VAL_ 493 PrkInDirChoice 0 "None" 1 "Tail in" 2 "Head in" 3 "Reserved";
VAL_ 493 ADASDispSwt 0 "No action" 1 "OFF" 2 "ON" 3 "Reserved";
VAL_ 493 NaviDispSwt 0 "No action" 1 "OFF" 2 "ON" 3 "Reserved";
VAL_ 493 NaviDispSwt_VR 0 "No action" 1 "OFF" 2 "ON" 3 "Reserved";
VAL_ 493 ADASDispSwt_VR 0 "No action" 1 "OFF" 2 "ON" 3 "Reserved";
VAL_ 493 ApproachLampSet 0 "No action" 1 "OFF" 2 "ON" 3 "Reserved";
VAL_ 493 SuperLockSet 0 "No action" 1 "OFF" 2 "ON" 3 "Reserved";
VAL_ 493 ALCMDynModSet 0 "DynModOFF" 1 "DynMod1" 2 "DynMod2" 3 "DynMod3" 4 "DynMod4" 5 "DynMod5" 6 "DynMod6" 7 "DynMod7";
VAL_ 493 RLWinSwtReq_VR 0 "No action" 1 "Close" 2 "Open" 3 "Half_Open" 4 "5%_Up" 5 "5%_Down" 6 "13_Open" 7 "Reserved";
VAL_ 493 RRWinSwtReq_VR 0 "No action" 1 "Close" 2 "Open" 3 "Half_Open" 4 "5%_Up" 5 "5%_Down" 6 "13_Open" 7 "Reserved";
VAL_ 493 DrvWinSwtReq_VR 0 "No action" 1 "Close" 2 "Open" 3 "Half_Open" 4 "5%_Up" 5 "5%_Down" 6 "13_Open" 7 "Reserved";
VAL_ 493 PassWinSwtReq_VR 0 "No action" 1 "Close" 2 "Open" 3 "Half_Open" 4 "5%_Up" 5 "5%_Down" 6 "13_Open" 7 "Reserved";
VAL_ 493 ChairMemPosnSetSwt 0 "no action" 1 "set memory button 1" 2 "set memory button 2" 3 "set memory button 3" 4 "recall  memory button 1" 5 "recall  memory button 2" 6 "recall  memory button 3" 7 "Reserved";
VAL_ 493 PathLrngFinshCmd 0 "No request" 1 "Request";
VAL_ 493 PathLrngStartCmd 0 "No request" 1 "Request";
VAL_ 493 SelPrkOutDirReq 0 "No selection" 1 "Park out frontvertical head out" 2 "Park out rearvertical tail out" 3 "Park out leftparallel left out" 4 "Park out rightparallel right out" 5 "Reserved" 7 "Reserved";
VAL_ 493 StartPrkgPath2Cmd 0 "No request" 1 "Request";
VAL_ 493 DeletePath2Cmd 0 "No request" 1 "Request";
VAL_ 493 StartPrkgPath1Cmd 0 "No request" 1 "Request";
VAL_ 493 DeletePath1Cmd 0 "No request" 1 "Request";
VAL_ 493 SelPrkgFctnCmd 0 "No selection" 1 "Select APA parking" 2 "Select P2P parking" 3 "Select Explore Forward" 4 "Select drive back" 5 "Reserved" 7 "Reserved";
VAL_ 493 ParkMdlCmd 0 "No request" 1 "Request";
VAL_ 493 BackReq_APS 0 "No request" 1 "Request";
VAL_ 493 ACFGAEnaReq_TC 0 "No action" 1 "Disable" 2 "Enable" 3 "Reserved";
VAL_ 493 ACFGAChanTyp_TC 0 "No action" 1 "OFF" 2 "Channel 1" 3 "Channel 2" 4 "Channel 3" 5 "Reserved" 7 "Reserved";
VAL_ 493 ACFGALvlReq_TC 0 "No action" 1 "OFF" 2 "Level1 (Low)" 3 "Level2 (Mid)" 4 "Level3 (High)" 5 "Reserved" 7 "Reserved";
VAL_ 493 P2P_PrkgDirectSwtCmd 0 "No Request" 1 "Request";
VAL_ 880 TimeMod 0 "24" 1 "12";
VAL_ 880 TimeIndcn 0 "am" 1 "pm";
VAL_ 880 Time_Hour 0 "Valid hour" 23 "Valid hour" 24 "Reserved" 30 "Reserved" 31 "Invalid";
VAL_ 880 Time_Minutes 0 "Valid minute" 59 "Valid minute" 60 "Reserved" 62 "Reserved" 63 "Invalid";
VAL_ 880 Time_Second 0 "Valid second" 59 "Valid second" 60 "Reserved" 62 "Reserved" 63 "Invalid";
VAL_ 880 Time_Year_Left 0 "Valid year" 9 "Valid year" 10 "Reserved" 14 "Reserved" 15 "Invalid";
VAL_ 880 Time_Year_Right 0 "Valid year" 9 "Valid year" 10 "Reserved" 14 "Reserved" 15 "Invalid";
VAL_ 880 Time_Month 0 "Invalid" 1 "Valid month" 12 "Valid month" 13 "Reserved" 15 "Reserved";
VAL_ 880 Time_Day 0 "Invalid" 1 "Valid day" 31 "Valid day";
VAL_ 880 HUT_TgtSOCSet 0 "Valid value" 50 "Valid value" 51 "Invalid" 52 "Extremely comfortable" 53 "Outdoor camping" 54 "Reserve" 63 "Reserve";
VAL_ 485 ACRearTempReq_ETC_VR 0 "Initial value" 1 "Level 1(Low)_17(Hi)" 17 "Level 1(Low)_17(Hi)" 18 "Reserved" 31 "Reserved";
VAL_ 485 ACRearTempSteplsReq_ETC_TC 0 "Initial value" 1 "Level 1(Low)_17(Hi)" 17 "Level 1(Low)_17(Hi)" 18 "Reserved" 31 "Reserved";
VAL_ 485 ACDrvTempDecReq_ETC_TC 0 "No action" 1 "Pressed" 2 "Reserved" 3 "Reserved";
VAL_ 485 ACDrvTempIncReq_ETC_TC 0 "No action" 1 "Pressed" 2 "Reserved" 3 "Reserved";
VAL_ 485 ACRearTempDecReq_ETC_TC 0 "No action" 1 "Pressed" 2 "Reserved" 3 "Reserved";
VAL_ 485 ACRearTempIncReq_ETC_TC 0 "No action" 1 "Pressed" 2 "Reserved" 3 "Reserved";
VAL_ 485 ACRearPowerReq_VR 0 "No action" 1 "Inactive" 2 "Active" 3 "Reserved";
VAL_ 485 ACMaxReq_VR 0 "No action" 1 "Not active" 2 "Active" 3 "Reserved";
VAL_ 485 ACMaxReq_TC 0 "No action" 1 "Pressed" 2 "Reserved" 3 "Reserved";
VAL_ 485 FrntWiprCtrl_VR 0 "No action" 1 "Off" 2 "On" 3 "Reserved";
VAL_ 485 ACRearAutoModReq_VR 0 "No action" 1 "Not active_reserved" 2 "Active" 3 "Reserved";
VAL_ 485 LockWinSet 0 "Close" 1 "Open";
VAL_ 485 ACRearLockReq_TC 0 "No action" 1 "Pressed" 2 "Reserved" 3 "Reserved";
VAL_ 485 SrSpdCtrlSwt 0 "OFF" 1 "ON";
VAL_ 485 DPF_Request 0 "No action" 1 "Active" 2 "No Active" 3 "Reserved";
VAL_ 485 ColorCategory 0 "Single color" 1 "Multi color" 2 "Reserved" 3 "Reserved";
VAL_ 485 SingleColorNr 0 "No command" 1 "Valid" 64 "Valid" 65 "Reserved" 127 "Reserved";
VAL_ 487 ACRLTempDecReq_TC 0 "No action" 1 "Pressed" 2 "Reserved" 3 "Reserved";
VAL_ 487 ACRLTempIncReq_TC 0 "No action" 1 "Pressed" 2 "Reserved" 3 "Reserved";
VAL_ 487 ACRLTempReq_VR 0 "No action" 1 "Low" 2 "valid value(phys=0.5 * raw + 15.5)" 32 "valid value(phys=0.5 * raw + 15.5)" 33 "High" 34 "Reserved" 63 "Reserved";
VAL_ 487 ACRRTempDecReq_TC 0 "No action" 1 "Pressed" 2 "Reserved" 3 "Reserved";
VAL_ 487 ACRRTempIncReq_TC 0 "No action" 1 "Pressed" 2 "Reserved" 3 "Reserved";
VAL_ 487 ACRRTempReq_VR 0 "No action" 1 "Low" 2 "valid value(phys=0.5 * raw + 15.5)" 32 "valid value(phys=0.5 * raw + 15.5)" 33 "High" 34 "Reserved" 63 "Reserved";
VAL_ 487 ACRRTempSteplsReq_TC 0 "No action" 1 "Pressed" 2 "Reserved" 3 "Reserved";
VAL_ 487 ACHumidifierReq_VR 0 "No action" 1 "Inactive" 2 "Active" 3 "Reserved";
VAL_ 487 ACHumidifierReq_TC 0 "No action" 1 "Inactive" 2 "Active" 3 "Reserved";
VAL_ 487 ACOzoneReq_TC 0 "No action" 1 "Inactive" 2 "Active" 3 "Reserved";
VAL_ 487 ACOzoneReq_VR 0 "No action" 1 "Inactive" 2 "Active" 3 "Reserved";
VAL_ 487 ACUltravioletReq_TC 0 "No action" 1 "Inactive" 2 "Active" 3 "Reserved";
VAL_ 487 ACUltravioletReq_VR 0 "No action" 1 "Inactive" 2 "Active" 3 "Reserved";
VAL_ 487 ACFrntWinHeatCmd_TC 0 "No action" 1 "Pressed" 2 "Reserved" 3 "Reserved";
VAL_ 487 ACFrntWinHeatCmd_VR 0 "No action" 1 "Close" 2 "Open" 3 "Reserved";
VAL_ 487 DrvDoorALCMFlashFreq 0 "No action" 1 "1Hz" 2 "2Hz" 3 "4Hz" 4 "OFF" 5 "Reserved" 7 "Reserved";
VAL_ 487 PassDoorALCMFlashFreq 0 "No action" 1 "1Hz" 2 "2Hz" 3 "4Hz" 4 "OFF" 5 "Reserved" 7 "Reserved";
VAL_ 487 LRDoorALCMFlashFreq 0 "No action" 1 "1Hz" 2 "2Hz" 3 "4Hz" 4 "OFF" 5 "Reserved" 7 "Reserved";
VAL_ 487 RRDoorALCMFlashFreq 0 "No action" 1 "1Hz" 2 "2Hz" 3 "4Hz" 4 "OFF" 5 "Reserved" 7 "Reserved";
VAL_ 487 FootALCMFlashFreq 0 "No action" 1 "1Hz" 2 "2Hz" 3 "4Hz" 4 "OFF" 5 "Reserved" 7 "Reserved";
VAL_ 487 LeftPanelALCMFlashFreq 0 "No action" 1 "1Hz" 2 "2Hz" 3 "4Hz" 4 "OFF" 5 "Reserved" 7 "Reserved";
VAL_ 487 RightPanelALCMFlashFreq 0 "No action" 1 "1Hz" 2 "2Hz" 3 "4Hz" 4 "OFF" 5 "Reserved" 7 "Reserved";
VAL_ 487 ACRearLockReq_VR 0 "No_Action" 1 "Not_Active" 2 "Active" 3 "Reserved";
VAL_ 491 ActvEntryLockSet 0 "OFF" 1 "ON";
VAL_ 491 ActvEntryUnlockSet 0 "OFF" 1 "ON";
VAL_ 491 LockPromptFunSet 0 "Horn&Light" 1 "HornOnly" 2 "LightOnly" 3 "Reserved";
VAL_ 491 BTAPAEntryLockSet 0 "OFF" 1 "ON";
VAL_ 491 BTAPALvngUnlockSet 0 "OFF" 1 "ON";
VAL_ 491 ClsWinSpdSet 0 "Close" 1 "60kmh" 2 "80kmh" 3 "100kmh";
VAL_ 491 DrvSeatMassgLvlSet 0 "OFF" 1 "Level1_Low" 2 "Level2_Middle" 3 "Level3_High" 4 "No Action" 5 "Reserved" 7 "Reserved";
VAL_ 491 PassSeatMassgLvlSet 0 "OFF" 1 "Level1_Low" 2 "Level2_Middle" 3 "Level3_High" 4 "No Action" 5 "Reserved" 7 "Reserved";
VAL_ 491 SeatKeyMemEna 0 "Disable" 1 "Enable";
VAL_ 491 RLSeatMassgLvlSet 0 "OFF" 1 "Level1_Low" 2 "Level2_Middle" 3 "Level3_High" 4 "No Action" 5 "reserved" 7 "reserved";
VAL_ 491 RRSeatMassgLvlSet 0 "OFF" 1 "Level1_Low" 2 "Level2_Middle" 3 "Level3_High" 4 "No Action" 5 "Reserved" 7 "Reserved";
VAL_ 491 DrvDoorALCMClrSet 0 "Colour set 0-63" 63 "Colour set 0-63" 64 "No action" 65 "Reserved" 127 "Reserved";
VAL_ 491 PassDoorALCMClrSet 0 "Colour set 0-63" 63 "Colour set 0-63" 64 "No action" 65 "Reserved" 127 "Reserved";
VAL_ 491 LRDoorALCMClrSet 0 "Colour set 0-63" 63 "Colour set 0-63" 64 "No action" 65 "Reserved" 127 "Reserved";
VAL_ 491 DrvDoorALCMSwt 0 "OFF" 1 "ON";
VAL_ 491 PassDoorALCMSwt 0 "OFF" 1 "ON";
VAL_ 877 DrvSeatVentnLvlSet 0 "OFF" 1 "Level 1_Low" 2 "Level 2_Middle" 3 "Level 3_High";
VAL_ 877 PassSeatVentnLvlSet 0 "OFF" 1 "Level 1_Low" 2 "Level 2_Middle" 3 "Level 3_High";
VAL_ 877 ACAutoModReq_VR 0 "No action" 1 "Not active_reserved" 2 "Active" 3 "Reserved";
VAL_ 877 ACCmprReq_VR 0 "No action" 1 "Not active" 2 "Active" 3 "Reserved";
VAL_ 877 ACPowerReq_VR 0 "No action" 1 "Power off" 2 "Power on" 3 "Reserved";
VAL_ 877 ACBlwrSpdReq_VR 0 "No Command" 1 "Stepless Speed1_Low" 2 "Stepless Speed2" 3 "Stepless Speed3" 4 "Stepless Speed4" 5 "Stepless Speed5" 6 "Stepless Speed6" 7 "Stepless Speed7_High" 8 "Reserved" 15 "Reserved";
VAL_ 877 ACDrvTempReq_VR 0 "No action" 1 "Low" 2 "valid value(phys=0.5 * raw + 15.5)" 32 "valid value(phys=0.5 * raw + 15.5)" 33 "High" 34 "Reserved" 63 "Reserved";
VAL_ 877 ACFrntDefrostReq_VR 0 "No action" 1 "Not active" 2 "Active" 3 "Reserved";
VAL_ 877 ACDrvAirDistribModReq_VR 0 "No action" 1 "Face" 2 "Face & Foot" 3 "Foot" 4 "Foot & Defrost" 5 "Reserved" 7 "Reserved";
VAL_ 877 ACAirInletReq_VR 0 "no action" 1 "Fresh" 2 "Recirculation" 3 "Reserved";
VAL_ 877 ACModReq_HUT 0 "no action" 1 "comfort" 2 "economy" 3 "reserved";
VAL_ 877 ElecSideSteppingSysSet 0 "OFF" 1 "ON";
VAL_ 877 RoofModSet 0 "OFF" 1 "ON";
VAL_ 877 AllTerrainDislSet 0 "OFF" 1 "ON";
VAL_ 877 RemUpgrdSts 0 "NO action" 1 "End the Remote upgrade mode";
VAL_ 877 ACRearAutoModReq_TC 0 "No action" 1 "Pressed";
VAL_ 877 DrvSeatSupportLvlSet 0 "OFF" 1 "Level 1" 2 "Level 2" 3 "Level 3" 4 "Level 4" 5 "Level 5" 6 "Level adjust fail" 7 "Reserved";
VAL_ 877 PassSeatSupportLvlSet 0 "OFF" 1 "Level 1" 2 "Level 2" 3 "Level 3" 4 "Level 4" 5 "Level 5" 6 "Level adjust fail" 7 "Reserved";
VAL_ 877 ACRearOffReq_TC 0 "No action" 1 "Pressed";
VAL_ 877 ACRearAirDistribModReq_TC 0 "No action" 1 "Face" 2 "Face & Foot" 3 "Foot" 4 "Reserved" 7 "Reserved";
VAL_ 877 RLSeatVentnLvlSet 0 "OFF" 1 "Level 1_Low" 2 "Level 2_Middle" 3 "Level 3_High";
VAL_ 877 RRSeatVentnLvlSet 0 "OFF" 1 "Level 1_Low" 2 "Level 2_Middle" 3 "Level 3_High";
VAL_ 548 ALCMMasterSwt 0 "OFF" 1 "ON";
VAL_ 548 ALCMPartitionSwt 0 "OFF" 1 "ON";
VAL_ 548 MusicFrq0 0 "63Hz amplitude intensity 0-100" 100 "63Hz amplitude intensity 0-100" 101 "No action" 102 "Reserved" 127 "Reserved";
VAL_ 548 MusicFrq1 0 "160Hz amplitude intensity 0-100" 100 "160Hz amplitude intensity 0-100" 101 "No action" 102 "Reserved" 127 "Reserved";
VAL_ 548 MusicFrq2 0 "400Hz amplitude intensity 0-100" 100 "400Hz amplitude intensity 0-100" 101 "No action" 102 "Reserved" 127 "Reserved";
VAL_ 548 MusicFrq3 0 "1KHz amplitude intensity 0-100" 100 "1KHz amplitude intensity 0-100" 101 "No action" 102 "Reserved" 127 "Reserved";
VAL_ 548 MusicFrq4 0 "2.5KHz amplitude intensity 0-100" 100 "2.5KHz amplitude intensity 0-100" 101 "No action" 102 "Reserved" 127 "Reserved";
VAL_ 548 MusicFrq5 0 "6.25KHz amplitude intensity 0-100" 100 "6.25KHz amplitude intensity 0-100" 101 "No action" 102 "Reserved" 127 "Reserved";
VAL_ 548 MusicFrq6 0 "16KHz amplitude intensity 0-100" 100 "16KHz amplitude intensity 0-100" 101 "No action" 102 "Reserved" 127 "Reserved";
VAL_ 507 RRDoorALCMClrSet 0 "Colour set 0-63" 63 "Colour set 0-63" 64 "No action" 65 "Reserved" 127 "Reserved";
VAL_ 507 LeftPanelALCMClrSet 0 "Colour set 0-63" 63 "Colour set 0-63" 64 "No action" 65 "Reserved" 127 "Reserved";
VAL_ 507 RightPanelALCMClrSet 0 "Colour set 0-63" 63 "Colour set 0-63" 64 "No action" 65 "Reserved" 127 "Reserved";
VAL_ 507 FootALCMClrSet 0 "Colour set 0-63" 63 "Colour set 0-63" 64 "No action" 65 "Reserved" 127 "Reserved";
VAL_ 507 DrvDoorALCMLightLvlSet 0 "No action" 1 "10" 2 "20" 3 "30" 4 "40" 5 "50" 6 "60" 7 "70" 8 "80" 9 "90" 10 "100" 11 "Reserved" 15 "Reserved";
VAL_ 507 PassDoorALCMLightLvlSet 0 "No action" 1 "10" 2 "20" 3 "30" 4 "40" 5 "50" 6 "60" 7 "70" 8 "80" 9 "90" 10 "100" 11 "Reserved" 15 "Reserved";
VAL_ 507 LRDoorALCMLightLvlSet 0 "No action" 1 "10" 2 "20" 3 "30" 4 "40" 5 "50" 6 "60" 7 "70" 8 "80" 9 "90" 10 "100" 11 "Reserved" 15 "Reserved";
VAL_ 507 RRDoorALCMLightLvlSet 0 "No action" 1 "10" 2 "20" 3 "30" 4 "40" 5 "50" 6 "60" 7 "70" 8 "80" 9 "90" 10 "100" 11 "Reserved" 15 "Reserved";
VAL_ 507 LeftPanelALCMLightLvlSet 0 "No action" 1 "10" 2 "20" 3 "30" 4 "40" 5 "50" 6 "60" 7 "70" 8 "80" 9 "90" 10 "100" 11 "Reserved" 15 "Reserved";
VAL_ 507 RightPanelALCMLightLvlSet 0 "No action" 1 "10" 2 "20" 3 "30" 4 "40" 5 "50" 6 "60" 7 "70" 8 "80" 9 "90" 10 "100" 11 "Reserved" 15 "Reserved";
VAL_ 507 FootALCMLightLvlSet 0 "No action" 1 "10" 2 "20" 3 "30" 4 "40" 5 "50" 6 "60" 7 "70" 8 "80" 9 "90" 10 "100" 11 "Reserved" 15 "Reserved";
VAL_ 507 ALCMFloSwt 0 "OFF" 1 "ON";
VAL_ 507 ALCMBreSwt 0 "OFF" 1 "ON";
VAL_ 507 RightPanelALCMSwt 0 "OFF" 1 "ON";
VAL_ 507 LRDoorALCMSwt 0 "OFF" 1 "ON";
VAL_ 507 RRDoorALCMSwt 0 "OFF" 1 "ON";
VAL_ 507 FootALCMSwt 0 "OFF" 1 "ON";
VAL_ 507 RoofALCMSwt 0 "OFF" 1 "ON";
VAL_ 507 LeftPanelALCMSwt 0 "OFF" 1 "ON";
VAL_ 505 ACRLTempSteplsReq_TC 0 "No action" 1 "Low" 2 "Valid value" 32 "Valid value" 33 "High" 34 "Reserved" 63 "Reserved";
VAL_ 509 RLSeatMassgModSet 0 "No Action" 1 "Wave Mode" 2 "Serpentine Mode" 3 "Catwalk Mode" 4 "Shoulder Mode" 5 "Lumbar Mode" 6 "Soothing Mode" 7 "Butterfly Mode" 8 "Full Body Stretch Mode" 9 "Single Row Mode" 10 "Pulse Mode" 11 "Reserved" 15 "Reserved";
VAL_ 509 RRSeatMassgModSet 0 "No Action" 1 "Wave Mode" 2 "Serpentine Mode" 3 "Catwalk Mode" 4 "Shoulder Mode" 5 "Lumbar Mode" 6 "Soothing Mode" 7 "Butterfly Mode" 8 "Full Body Stretch Mode" 9 "Single Row Mode" 10 "Pulse Mode" 11 "Reserved" 15 "Reserved";
VAL_ 509 DrvSeatHeatgLvlSet_Nine 0 "No Action" 1 "OFF" 2 "Level1_Low" 3 "Level2" 4 "Level3" 5 "Level4" 6 "Level5" 7 "Level6" 8 "Level7" 9 "Level8" 10 "Level9_High" 11 "Reserved" 15 "Reserved";
VAL_ 509 PassSeatHeatgLvlSet_Nine 0 "No Action" 1 "OFF" 2 "Level1_Low" 3 "Level2" 4 "Level3" 5 "Level4" 6 "Level5" 7 "Level6" 8 "Level7" 9 "Level8" 10 "Level9_High" 11 "Reserved" 15 "Reserved";
VAL_ 509 RLSeatHeatgLvlSet_Nine 0 "No Action" 1 "OFF" 2 "Level1_Low" 3 "Level2" 4 "Level3" 5 "Level4" 6 "Level5" 7 "Level6" 8 "Level7" 9 "Level8" 10 "Level9_High" 11 "Reserved" 15 "Reserved";
VAL_ 509 RRSeatHeatgLvlSet_Nine 0 "No Action" 1 "OFF" 2 "Level1_Low" 3 "Level2" 4 "Level3" 5 "Level4" 6 "Level5" 7 "Level6" 8 "Level7" 9 "Level8" 10 "Level9_High" 11 "Reserved" 15 "Reserved";
VAL_ 476 PassSeatMassgModSet 0 "No Action" 1 "Wave Mode" 2 "Serpentine Mode" 3 "Catwalk Mode" 4 "Shoulder Mode" 5 "Lumbar Mode" 6 "Soothing Mode" 7 "Butterfly Mode" 8 "Full Body Stretch Mode" 9 "Single Row Mode" 10 "Pulse Mode" 11 "Reserved" 15 "Reserved";
VAL_ 476 DrvSeatMassgModSet 0 "No Action" 1 "Wave Mode" 2 "Serpentine Mode" 3 "Catwalk Mode" 4 "Shoulder Mode" 5 "Lumbar Mode" 6 "Soothing Mode" 7 "Butterfly Mode" 8 "Full Body Stretch Mode" 9 "Single Row Mode" 10 "Pulse Mode" 11 "Reserved" 15 "Reserved";
VAL_ 476 PPMI_P_BSR_SwtSet 0 "No action" 1 "OFF" 2 "ON" 3 "Reserved";
VAL_ 476 RWPC_SwtReq 0 "No action" 1 "Initial Value" 2 "Close" 3 "Open";
VAL_ 477 DrvSeatVentnLvlSet_Nine 0 "No Action" 1 "OFF" 2 "Level1_Low" 3 "Level2" 4 "Level3" 5 "Level4" 6 "Level5" 7 "Level6" 8 "Level7" 9 "Level8" 10 "Level9_High" 11 "Reserved" 15 "Reserved";
VAL_ 477 PassSeatVentnLvlSet_Nine 0 "No Action" 1 "OFF" 2 "Level1_Low" 3 "Level2" 4 "Level3" 5 "Level4" 6 "Level5" 7 "Level6" 8 "Level7" 9 "Level8" 10 "Level9_High" 11 "Reserved" 15 "Reserved";
VAL_ 477 RLSeatVentnLvlSet_Nine 0 "No Action" 1 "OFF" 2 "Level1_Low" 3 "Level2" 4 "Level3" 5 "Level4" 6 "Level5" 7 "Level6" 8 "Level7" 9 "Level8" 10 "Level9_High" 11 "Reserved" 15 "Reserved";
VAL_ 477 RRSeatVentnLvlSet_Nine 0 "No Action" 1 "OFF" 2 "Level1_Low" 3 "Level2" 4 "Level3" 5 "Level4" 6 "Level5" 7 "Level6" 8 "Level7" 9 "Level8" 10 "Level9_High" 11 "Reserved" 15 "Reserved";
VAL_ 477 ARFSwtReq 0 "No_action" 1 "OFF" 2 "ON";
VAL_ 477 ASFCSwtReq 0 "No_action" 1 "OFF" 2 "ON";
VAL_ 477 AGSSwtReq 0 "No_action" 1 "OFF" 2 "ON";
VAL_ 477 SOCMngmntSwtReq 0 "No_action" 1 "OFF" 2 "ON";
VAL_ 74 AUTODefrost_TC 0 "No action" 1 "Pressed" 2 "Reserved" 3 "Reserved";
VAL_ 74 AUTODefrost_VR 0 "No action" 1 "Not active" 2 "Active" 3 "Reserved";
VAL_ 74 LaneCalActvtCmd 0 "Off" 1 "On";
VAL_ 74 MODChgReq 0 "No request" 1 "Request";
VAL_ 74 Radar_DispCmd 0 "No Request" 1 "Request";
VAL_ 74 Guid_Ovl_Display_Cmd 0 "No Request" 1 "Request";
VAL_ 74 Sgl_View_Sel 0 "No Commands" 1 "Touch 2D Front Button" 2 "Touch 2D Rear Button" 3 "Touch 2D Left Button" 4 "Touch 2D Right Button" 5 "Touch 2D Left Front  Button" 6 "Touch 2D Right Front Button" 7 "Touch 2D Left Back Button" 8 "Touch 2D Right Back Button" 9 "Touch return Button" 10 "Touch Engine Room Button" 11 "Reserved" 15 "Reserved";
VAL_ 74 SwToFieldCalRstCmd 0 "Off" 1 "On";
VAL_ 74 AutoViewChgCmd 0 "No Request" 1 "Request";
VAL_ 74 MdlColrChgCmd 0 "No Request" 1 "Request";
VAL_ 74 CarMdlTrsprcySwtCmd 0 "No Request" 1 "Request";
VAL_ 74 CarMdlDispCmd 0 "No Request" 1 "Request";
VAL_ 74 AutoAVMSwSet_Cmd 0 "No Request" 1 "Request";
VAL_ 74 FPAS_AutoModSwt 0 "No Request" 1 "Request";
VAL_ 74 MEBSwtSet 0 "No Request" 1 "Request";
VAL_ 74 WshSoftSwt 0 "No request" 1 "Request";
VAL_ 74 View_SoftswitchCmd 0 "No request" 1 "Request";
VAL_ 288 IB_Warn 0 "Warning lamp off" 1 "Warning lamp on";
VAL_ 573 Checksum_IFC3 0 "Valid value" 255 "Valid value";
VAL_ 573 LDWResp 0 "OFF" 1 "ON";
VAL_ 573 LKAResp 0 "OFF" 1 "ON";
VAL_ 573 LCKResp 0 "OFF" 1 "ON";
VAL_ 573 ELKResp 0 "OFF" 1 "ON";
VAL_ 573 LDW_LKA_Snvty 0 "Normal" 1 "High sensitivity" 2 "Low sensitivity" 3 "Reserved";
VAL_ 573 IFCHUTInterface 0 "No response" 1 "Response";
VAL_ 573 LSSWarnFormResp 0 "Voice" 1 "Haptic" 2 "Voice+Haptic" 3 "Reserved";
VAL_ 573 LSSResp 0 "OFF" 1 "ON";
VAL_ 573 AESSts 0 "OFF" 1 "ON" 2 "Reserved" 3 "Reserved";
VAL_ 573 ESSSts 0 "OFF" 1 "ON" 2 "Reserved" 3 "Reserved";
VAL_ 573 AESErrSts 0 "No Error" 1 "Error";
VAL_ 573 ESSErrSts 0 "No Error" 1 "Error";
VAL_ 573 RollingCounter_IFC3 0 "Valid value" 14 "Valid value" 15 "Invalid value";
VAL_ 573 Checksum_IFC4 0 "Valid value" 255 "Valid value";
VAL_ 573 IFC_Handsoffwarn 0 "No warning" 1 "Level1 warning" 2 "Level2 warning" 3 "Level3 warning" 4 "Level4 warning" 5 "Level5 warning" 6 "LKA warning" 7 "Reserved";
VAL_ 573 IFCCalibrationSts 0 "Calibration Success" 1 "Calibration In Process" 2 "Calibration Failed" 3 "Reserved";
VAL_ 573 CameraBlockageSts 0 "Camera Not Blocked" 1 "Camera Blocked";
VAL_ 573 LDW_LKAWarn 0 "No LDW_LKA warning" 1 "LDW_LKA left warning" 2 "LDW_LKA right warning" 3 "Reserved";
VAL_ 573 LSSIntervention 0 "No warning and Intervention" 1 "Left warning" 2 "Right warning" 3 "Left Intervention" 4 "Right Intervention" 5 "Both Intervention" 6 "Left warn only reminder" 7 "Right warn only reminder";
VAL_ 573 LSSFuncSts 0 "OFF" 1 "LDW on" 2 "LKA on" 3 "LCK ON" 4 "Reserved" 7 "Reserved";
VAL_ 573 ELKMainState 0 "ELK-OFF(Ã¥Â…Â³Ã©Â—Â­)" 1 "ELK-Standby(Ã¥Â¼Â€Ã¥ÂÂ¯)" 2 "ELK-Enable(Ã¥Â·Â²Ã¤Â½Â¿Ã¨ÂƒÂ½Ã¯Â¼ÂŒÃ¤Â¸ÂÃ¦Â»Â¡Ã¨Â¶Â³Ã¦Â‰Â­Ã§ÂŸÂ©Ã¤Â»Â‹Ã¥Â…Â¥Ã¦ÂÂ¡Ã¤Â»Â¶)" 3 "ELK-Road edge Active(Ã©ÂÂ“Ã¨Â·Â¯Ã¨Â¾Â¹Ã§Â¼Â˜Ã¦Â‰Â­Ã§ÂŸÂ©Ã¤Â»Â‹Ã¥Â…Â¥)" 4 "ELK-Oncoming ActiveÃ¯Â¼ÂˆoncomingÃ¦Â‰Â­Ã§ÂŸÂ©Ã¤Â»Â‹Ã¥Â…Â¥Ã¯Â¼Â‰" 5 "ELK-Overtaking ActiveÃ¯Â¼ÂˆovertakingÃ¦Â‰Â­Ã§ÂŸÂ©Ã¤Â»Â‹Ã¥Â…Â¥Ã¯Â¼Â‰" 6 "ELK-Failure" 7 "Reserved";
VAL_ 573 LaneAvailability 0 "Not Avaliable" 1 "Left Lane Marker Available" 2 "Right Lane Marker Available" 3 "Both Lane Markers Available";
VAL_ 573 TJA_FollowSts 0 "No Follow" 1 "Follow Vehicle" 2 "Reserved" 3 "Reserved";
VAL_ 573 LSSErrSts 0 "No error" 1 "LDW error" 2 "LKA error" 3 "LCK error" 4 "ELK error" 5 "ESS error" 6 "Reserved" 7 "Reserved";
VAL_ 573 AESintervention 0 "No intervention" 1 "Left intervention" 2 "Right intervention" 3 "Reserved";
VAL_ 573 ESSintervention 0 "No intervention" 1 "Left intervention" 2 "Right intervention" 3 "Reserved";
VAL_ 573 ELKActSts 0 "Inactive" 1 "Left Active" 2 "Right active" 3 "Reserved";
VAL_ 573 IntelligentEvaActSts 0 "Inactive" 1 "Left Eva" 2 "Right Eva" 3 "Reserved";
VAL_ 573 LCKStsIndcr 0 "No indicator" 1 "Active indicator" 2 "Passive indicator" 3 "Reserved";
VAL_ 573 RollingCounter_IFC4 0 "Valid value" 14 "Valid value" 15 "Invalid value";
VAL_ 573 Checksum_IFC5 0 "Valid value" 255 "Valid value";
VAL_ 573 IFC_LaneCurve 0 "Valid value" 4094 "Valid value" 4095 "Reserved";
VAL_ 573 IFC_LeLaneTyp 0 "No display" 1 "Solid lane" 2 "Dashed lane" 3 "Rode edge" 4 "Reserved" 7 "Reserved";
VAL_ 573 IFC_RiLaneTyp 0 "No display" 1 "Solid lane" 2 "Dashed lane" 3 "Rode edge" 4 "Reserved" 7 "Reserved";
VAL_ 573 IFC_NextLeLaneTyp 0 "No display" 1 "Solid lane" 2 "Dashed lane" 3 "Rode edge" 4 "Reserved" 7 "Reserved";
VAL_ 573 IFC_NextRiLaneTyp 0 "No display" 1 "Solid lane" 2 "Dashed lane" 3 "Rode edge" 4 "Reserved" 7 "Reserved";
VAL_ 573 IFC_LeLane_dy 0 "Valid value" 4094 "Valid value" 4095 "Invalid value";
VAL_ 573 IFC_RiLane_dy 0 "Valid value" 4094 "Valid value" 4095 "Invalid value";
VAL_ 573 RollingCounter_IFC5 0 "Valid value" 14 "Valid value" 15 "Invalid value";
VAL_ 573 Checksum_IFC6 0 "Valid value" 255 "Valid value";
VAL_ 573 IFC_NextLeLane_dy 0 "Valid value" 4094 "Valid value" 4095 "Invalid value";
VAL_ 573 IFC_NextRiLane_dy 0 "Valid value" 4094 "Valid value" 4095 "Invalid value";
VAL_ 573 RollingCounter_IFC6 0 "Valid value" 14 "Valid value" 15 "Invalid value";
VAL_ 573 AESResp 0 "OFF" 1 "ON";
VAL_ 573 ESS_Pedresp 0 "OFF" 1 "ON";
VAL_ 573 ESS_Vehresp 0 "OFF" 1 "ON";
VAL_ 573 IntelligentEvaResp 0 "OFF" 1 "ON";
VAL_ 719 TSRResp 0 "OFF" 1 "ON";
VAL_ 719 TSRSpdLimUnit 0 "Unknown" 1 "KMH" 2 "MPH" 3 "Reserved";
VAL_ 719 TSRSpdLim 0 "No Display" 1 "SPL 5" 2 "SPL 10" 3 "SPL 15" 4 "SPL 20" 5 "SPL 25" 6 "SPL 30" 7 "SPL 35" 8 "SPL 40" 9 "SPL 45" 10 "SPL 50" 11 "SPL 55" 12 "SPL 60" 13 "SPL 65" 14 "SPL 70" 15 "SPL 75" 16 "SPL 80" 17 "SPL 85" 18 "SPL 90" 19 "SPL 95" 20 "SPL 100" 21 "SPL 105" 22 "SPL 110" 23 "SPL 115" 24 "SPL 120" 25 "SPL 125" 26 "SPL 130" 27 "SPL 135" 28 "SPL 140" 29 "SPL 145" 30 "SPL 150" 31 "Reserved" 62 "Reserved" 63 "Invalid";
VAL_ 719 TSRSpdLimCfdc 0 "Null" 1 "Implicit" 2 "Explicit" 3 "Reserved";
VAL_ 719 TSRSts 0 "Off" 1 "Fusion mode" 2 "Vision mode" 3 "Navigation only mode" 4 "Failed" 5 "Reserved" 7 "Reserved";
VAL_ 719 TSRSpdLimSts 0 "No Speed Limit" 1 "Speed Limit" 2 "Speed Limit Cancel" 3 "Reserved";
VAL_ 719 TSRTrfcSignValCfdc 0 "Null" 1 "Implicit" 2 "Explicit" 3 "Reserved";
VAL_ 719 TSRTrfcSignVal 0 "None" 1 "Snow" 2 "Fog" 3 "ThunderStorm" 4 "Rain" 5 "FWay" 6 "EFWay" 7 "Straight" 8 "FrontageLeft" 9 "TurnLeftRight" 10 "FrontageRight" 11 "Right" 12 "TurnRight" 13 "Left" 14 "TurnLeft" 15 "RelieveNoOvertake" 16 "NoOvertake" 17 "StopGiveWay" 18 "GiveWay" 19 "NoPass" 20 "NoEntry" 21 "NoCar" 22 "NoTruck" 23 "NoBus" 24 "NoTurnaround" 25 "NoStraightLeftTurn" 26 "NoStraightRightTurn" 27 "NoLeftRightTurn" 28 "NoLeftTurn" 29 "NoRightTurn" 30 "NoStraight" 31 "WarnKids" 32 "WarnPed" 33 "WarnBike" 34 "WarnWorks" 35 "WarnWildanimal" 36 "WarnCattle" 37 "ACCidentProneSection" 38 "Town" 39 "Slow" 40 "SharpTurnR" 41 "SharpTurnL" 42 "ReverseCurveL" 43 "ReverseCurveR" 44 "ContinuousBend" 45 "Crossroads" 46 "ConfluenceR" 47 "ConfluenceL" 48 "RainWetness" 49 "SnowIcy" 50 "Time" 51 "Distance For" 52 "Distance In" 53 "Straight" 54 "FrontageLeft" 55 "TurnLeftRight" 56 "FrontageRight" 57 "Right" 58 "Turn Right" 59 "Left" 60 "Turn Left" 61 "Highway Start" 62 "Highway End" 63 "Mortorway Start" 64 "Mortorway End" 65 "City Entry" 66 "City Exit" 67 "Residential zones Entry" 68 "Residential zones Exit" 69 "Trailer" 70 "Reserved" 254 "Reserved" 255 "Invalid";
VAL_ 719 TSRSpdLimWarn 0 "No Warning" 1 "Warning";
VAL_ 719 TSRWarnResp 0 "OFF" 1 "ON";
VAL_ 719 TSR_Snvty 0 "valid" 30 "valid" 31 "Invalid";
VAL_ 719 IDC_L2_TurnLightReq 0 "Turn_OFF" 1 "Turn_Left_ON" 2 "Turn_Right_ON" 3 "Turn_OFF_Light_Swt";
VAL_ 719 HWA_ALC_Trig 0 "No_display" 1 "Slow_vehicle_ahead" 2 "Reserved" 3 "Reserved";
VAL_ 719 HWA_WarnInfoDisp 0 "No display" 1 "Construction site ahead" 2 "Large vehicles warn" 3 "night warning" 4 "Adverse weather warning" 5 "Restart to activate HIPilot" 6 "Camera blocked" 7 "Auto store to debug HIPilot" 8 "Left lane change confirmation" 9 "Right lane change confirmation" 10 "Try ALC later" 11 "lane change is cancelled because of risk" 12 "lane change aborted" 13 "Please Keep Attention_distraction" 14 "Fasten copilot seatbelt" 15 "Reserve";
VAL_ 719 HWA_TakOver_Trig 0 "Default" 1 "Off_ramp_fail" 2 "To_mainroad_fail" 3 "Turning_fail" 4 "Toll_gate_fail" 5 "Roundabout_fail";
VAL_ 719 HWA_TakOver_Req 0 "Default" 1 "Steer_wheel_req" 2 "Takeover_req" 3 "Reserved";
VAL_ 719 MRC_InterSysInfoDisp 0 "default" 1 "L_CR_fail" 2 "R_CR_fail" 3 "L_RSDS_fail" 4 "R_RSDS_fail" 5 "Radar_or_Cam_fail";
VAL_ 719 MRC_TakOver_Req 0 "No_display" 1 "Slow_stop" 2 "Roadside_stop" 3 "Emergent_stop";
VAL_ 719 NOH_WarnInfoDisp 0 "Default" 1 "Auto store to debug NOH" 2 "Restart to activate NOH" 3 "Off ramp fail" 4 "To mainroad fail" 5 "Turning fail" 6 "Toll gate fail" 7 "Roundabout fail" 8 "Reroute" 9 "Lane change manually" 10 "NOH resumed" 11 "Veh merge warn" 12 "Ramp off warn" 13 "GPS fail" 14 "Lane mark blurred" 15 "To drive out of main road";
VAL_ 719 IFC_Line01_Source 0 "Detected_value" 1 "Fitted_value";
VAL_ 719 IFC_Line02_Source 0 "Detected_value" 1 "Fitted_value";
VAL_ 719 TSR_Traffic_Light_Posn 0 "No_Display" 1 "Front" 2 "Left" 3 "Right";
VAL_ 719 Stop_Mark_Detn 0 "Not_dectected" 1 "Dectected" 2 "Reserved" 3 "Invalid";
VAL_ 719 Zebra_Mark_Detn 0 "Not_dectected" 1 "Dectected" 2 "Reserved" 3 "Invalid";
VAL_ 719 Grid_Mark_Detn 0 "Not_dectected" 1 "Dectected" 2 "Reserved" 3 "Invalid";
VAL_ 719 HWA_InhibitWarn 0 "Default" 1 "Environment_inhibit" 2 "Attention" 3 "Handson" 4 "Seatbelt" 5 "Close_door";
VAL_ 719 LaneChngCfmSwt_Resp 0 "OFF" 1 "ON";
VAL_ 719 ALC_SwtReq_Resp 0 "OFF" 1 "ON";
VAL_ 719 AutoSpdSetSwt_Resp 0 "OFF" 1 "ON";
VAL_ 719 VoiceBrdcSwt_Resp 0 "OFF" 1 "ON";
VAL_ 719 UsrManSts_Resp 0 "OFF" 1 "Page_1" 2 "Page_2" 3 "Page_3" 4 "Page_4" 5 "Page_5" 6 "Page_6" 7 "Page_7" 8 "Page_8" 9 "Page_9";
VAL_ 719 TSR_Traffic_Light 0 "No_Display" 1 "Greenlight" 2 "Redlight" 3 "Yellowlight";
VAL_ 719 TSR_Traffic_Light_Through 0 "No_Display" 1 "Greenlight" 2 "Redlight" 3 "Yellowlight";
VAL_ 719 TSR_Traffic_Light_Le 0 "No_Display" 1 "Greenlight" 2 "Redlight" 3 "Yellowlight";
VAL_ 719 TSR_Traffic_Light_Ri 0 "No_Display" 1 "Greenlight" 2 "Redlight" 3 "Yellowlight";
VAL_ 719 RainMode_Swt_Resp 0 "OFF" 1 "ON";
VAL_ 719 LCMode_Swt_Resp 0 "Normal" 1 "Sport" 2 "Comfort" 3 "Reserve";
VAL_ 719 NavDecSwtResp 0 "OFF" 1 "ON";
VAL_ 415 IFC_Line01_Dy 0 "Valid value" 6001 "Valid value" 6002 "Reversed" 8191 "Reversed";
VAL_ 415 IFC_Line01_Curv 0 "Valid value" 31250 "Valid value" 31251 "Reversed" 32767 "Reversed";
VAL_ 415 IFC_Line01_CurvChange 0 "Valid value" 960000 "Valid value" 960001 "Reversed" 1048575 "Reversed";
VAL_ 415 IFC_Line01_Type 0 "undecided" 1 "solid" 2 "dashed" 3 "double solid dashed" 4 "double dashed solid" 5 "double solid solid" 6 "double dashed dashed" 7 "botts" 8 "deceleration" 9 "hov_lane" 10 "road edge" 11 "elevated_structure" 12 "curb" 13 "cones_poles";
VAL_ 415 IFC_Line02_Dy 0 "Valid value" 6001 "Valid value" 6002 "Reversed" 8191 "Reversed";
VAL_ 415 IFC_Line02_Curv 0 "Valid value" 31250 "Valid value" 31251 "Reversed" 32767 "Reversed";
VAL_ 415 IFC_Line02_CurvChange 0 "Valid value" 960000 "Valid value" 960001 "Reversed" 1048575 "Reversed";
VAL_ 415 IFC_Line02_Type 0 "undecided" 1 "solid" 2 "dashed" 3 "double solid dashed" 4 "double dashed solid" 5 "double solid solid" 6 "double dashed dashed" 7 "botts" 8 "deceleration" 9 "hov_lane" 10 "road edge" 11 "elevated_structure" 12 "curb" 13 "cones_poles";
VAL_ 415 IFC_Line03_Dy 0 "valid value" 6001 "valid value" 6002 "reversed" 8191 "reversed";
VAL_ 415 IFC_Line03_Curv 0 "valid value" 31250 "valid value" 31251 "reversed" 32767 "reversed";
VAL_ 415 IFC_Line03_CurvChange 0 "valid value" 960000 "valid value" 960001 "reversed" 1048575 "reversed";
VAL_ 415 IFC_Line03_Type 0 "undecided" 1 "solid" 2 "dashed" 3 "double solid dashed" 4 "double dashed solid" 5 "double solid solid" 6 "double dashed dashed" 7 "botts" 8 "deceleration" 9 "hov_lane" 10 "road edge" 11 "elevated_structure" 12 "curb" 13 "cones_poles";
VAL_ 415 IFC_Line04_Dy 0 "valid value" 6001 "valid value" 6002 "reversed" 8191 "reversed";
VAL_ 415 IFC_Line04_Curv 0 "valid value" 31250 "valid value" 31251 "reversed" 32767 "reversed";
VAL_ 415 IFC_Line04_CurvChange 0 "valid value" 960000 "valid value" 960001 "reversed" 1048575 "reversed";
VAL_ 415 IFC_Line04_Type 0 "undecided" 1 "solid" 2 "dashed" 3 "double solid dashed" 4 "double dashed solid" 5 "double solid solid" 6 "double dashed dashed" 7 "botts" 8 "deceleration" 9 "hov_lane" 10 "road edge" 11 "elevated_structure" 12 "curb" 13 "cones_poles";
VAL_ 415 IFC_Roadedge01_Dy 0 "valid value" 6001 "valid value" 6002 "reversed" 8191 "reversed";
VAL_ 415 IFC_Roadedge01_Curv 0 "valid value" 31250 "valid value" 31251 "reversed" 32767 "reversed";
VAL_ 415 IFC_Roadedge01_Type 0 "undecided" 1 "solid" 2 "dashed" 3 "double solid dashed" 4 "double dashed solid" 5 "double solid solid" 6 "double dashed dashed" 7 "botts" 8 "deceleration" 9 "hov_lane" 10 "road edge" 11 "elevated_structure" 12 "curb" 13 "cones_poles";
VAL_ 415 IFC_Roadedge02_Dy 0 "valid value" 6001 "valid value" 6002 "reversed" 8191 "reversed";
VAL_ 415 IFC_Roadedge02_Curv 0 "valid value" 31250 "valid value" 31251 "reversed" 32767 "reversed";
VAL_ 415 IFC_Roadedge02_CurvChange 0 "valid value" 960000 "valid value" 960001 "reversed" 1048575 "reversed";
VAL_ 415 IFC_Roadedge02_Type 0 "undecided" 1 "solid" 2 "dashed" 3 "double solid dashed" 4 "double dashed solid" 5 "double solid solid" 6 "double dashed dashed" 7 "botts" 8 "deceleration" 9 "hov_lane" 10 "road edge" 11 "elevated_structure" 12 "curb" 13 "cones_poles";
VAL_ 546 IFC_Line01_DxStart 0 "valid value" 20001 "valid value" 20002 "reversed" 32767 "reversed";
VAL_ 546 IFC_Line01_DxEnd 0 "valid value" 20001 "valid value" 20002 "reversed" 32767 "reversed";
VAL_ 546 IFC_Line01_HeadingAngle 0 "valid value" 401 "valid value" 402 "reversed" 511 "reversed";
VAL_ 546 IFC_Line02_HeadingAngle 0 "valid value" 401 "valid value" 402 "reversed" 511 "reversed";
VAL_ 546 IFC_Line02_DxStart 0 "valid value" 20001 "valid value" 20002 "reversed" 32767 "reversed";
VAL_ 546 IFC_Line02_DxEnd 0 "valid value" 20001 "valid value" 20002 "reversed" 32767 "reversed";
VAL_ 546 IFC_Line03_DxStart 0 "valid value" 20001 "valid value" 20002 "reversed" 32767 "reversed";
VAL_ 546 IFC_Line03_DxEnd 0 "valid value" 20001 "valid value" 20002 "reversed" 32767 "reversed";
VAL_ 546 IFC_Line03_HeadingAngle 0 "valid value" 401 "valid value" 402 "reversed" 511 "reversed";
VAL_ 546 IFC_Line04_DxStart 0 "valid value" 20001 "valid value" 20002 "reversed" 32767 "reversed";
VAL_ 546 IFC_Line04_HeadingAngle 0 "valid value" 401 "valid value" 402 "reversed" 511 "reversed";
VAL_ 546 IFC_Line04_DxEnd 0 "valid value" 20001 "valid value" 20002 "reversed" 32767 "reversed";
VAL_ 546 IFC_Roadedge01_DxStart 0 "valid value" 20001 "valid value" 20002 "reversed" 32767 "reversed";
VAL_ 546 IFC_Roadedge01_DxEnd 0 "valid value" 20001 "valid value" 20002 "reversed" 32767 "reversed";
VAL_ 546 IFC_Roadedge01_HeadingAngle 0 "valid value" 401 "valid value" 402 "reversed" 511 "reversed";
VAL_ 546 IFC_Roadedge02_DxStart 0 "valid value" 20001 "valid value" 20002 "reversed" 32767 "reversed";
VAL_ 546 IFC_Roadedge02_DxEnd 0 "valid value" 20001 "valid value" 20002 "reversed" 32767 "reversed";
VAL_ 546 IFC_Roadedge02_HeadingAngle 0 "valid value" 401 "valid value" 402 "reversed" 511 "reversed";
VAL_ 265 IFCTrqOvlCmdProtnValue 0 "Valid value" 16383 "Valid value";
VAL_ 265 IFCTrqOvlCmdReqValue 0 "Valid value" 2047 "Valid value";
SIG_GROUP_ 623 HUT32 1 : CheckSum_HUT32 ContnPrkgReq PrkgCtrlModReq PrkStraightSwtReq_HUT PrkgCtrlModReqValid DetVideoLost ContnPrkgReqValid XLvl PrkStraightSuspendOrFinishReq_HU YLvl ScrnOpSts PrkStraightStrtReq_HUT PrkStraightVehStrtReq_HUT_Valid PrkStraightContinueReq_HUT P2P_PrkgDirSwtReq RainMode_Swt_Req LCMode_Swt_Req NavDecSwtReq PrkStraightModSel_HUT PrkStraightSts_HUT RollingCounter_HUT32;
SIG_GROUP_ 573 IFC3_IFC_FD2 1 : Checksum_IFC3 LDWResp LKAResp LCKResp ELKResp AESResp LDW_LKA_Snvty IFCHUTInterface ESS_Pedresp ESS_Vehresp LSSWarnFormResp LSSResp IntelligentEvaResp AESSts ESSSts AESErrSts ESSErrSts RollingCounter_IFC3;
SIG_GROUP_ 573 IFC4_IFC_FD2 1 : Checksum_IFC4 LDW_LKAWarn LSSIntervention LSSFuncSts ELKMainState LaneAvailability TJA_FollowSts LSSErrSts IFC_Handsoffwarn IFCCalibrationSts CameraBlockageSts ELKActSts IntelligentEvaActSts LCKStsIndcr AESintervention ESSintervention RollingCounter_IFC4;
SIG_GROUP_ 573 IFC5_IFC_FD2 1 : Checksum_IFC5 IFC_LaneCurve IFC_LeLaneTyp IFC_RiLaneTyp IFC_NextLeLaneTyp IFC_NextRiLaneTyp IFC_LeLane_dy IFC_RiLane_dy RollingCounter_IFC5;
SIG_GROUP_ 573 IFC6_IFC_FD2 1 : Checksum_IFC6 IFC_NextLeLane_dy IFC_NextRiLane_dy RollingCounter_IFC6;
